VERSION "HNNBNNNYNNNNNNNNNNNNNNNNNNNNNNNNNNNNNNNNNN/4/%%%/4/'%**4NNN///"

NS_ :

BS_:

BU_: _4CL_C6 _6HP_C6 Airbag_C6 CVT_C6 DME_EDC16CP3000 DME_ME7_MED9_C6 DME_SIMOS6_C6 DME_Slave EPB_C6 ESP8_C6 Gateway_C6 LWR_AFS_C6 LWS_C6

BO_ 866 ACC_1: 8 DME_ME7_MED9_C6
 SG_ BZ_ACC1 : 0|4@1+ (1.0,0.0) [0.0|15.0] ""  DME_EDC16CP3000,DME_ME7_MED9_C6,DME_SIMOS6_C6,ESP8_C6
 SG_ Status_ACC : 4|3@1+ (1.0,0.0) [0.0|7.0] ""  DME_EDC16CP3000,DME_ME7_MED9_C6,DME_SIMOS6_C6,ESP8_C6
 SG_ Momenten_Anf_ACC : 8|8@1+ (0.39,0.0) [0.0|99.06] "%MDI"  DME_EDC16CP3000,DME_ME7_MED9_C6,DME_SIMOS6_C6
 SG_ Anhalten : 16|1@1+ (1.0,0.0) [0.0|1.0] ""  Vector__XXX
 SG_ AWV2_Freigabe : 17|1@1+ (1.0,0.0) [0.0|1.0] ""  Vector__XXX
 SG_ Freigabe_Momenten_Anf : 19|1@1+ (1.0,0.0) [0.0|1.0] ""  DME_EDC16CP3000,DME_ME7_MED9_C6,DME_SIMOS6_C6
 SG_ Verhinderung_SA : 20|1@1+ (1.0,0.0) [0.0|1.0] ""  DME_SIMOS6_C6
 SG_ Freigabe_Verzoeg_Anf : 21|1@1+ (1.0,0.0) [0.0|1.0] ""  _6HP_C6,DME_EDC16CP3000,DME_ME7_MED9_C6,ESP8_C6
 SG_ FSPE_ACC : 22|1@1+ (1.0,0.0) [0.0|1.0] ""  Vector__XXX
 SG_ Vorbefuellung_Bremsanlage : 23|1@1+ (1.0,0.0) [0.0|1.0] ""  ESP8_C6
 SG_ Verzoeg_Anf_ACC : 24|8@1+ (0.024,-3.984) [-3.984|2.112] "m/s2"  DME_EDC16CP3000,DME_ME7_MED9_C6,ESP8_C6
 SG_ Sollbeschl_Getr : 32|8@1+ (0.024,-3.984) [-3.984|2.112] "m/s2"  Vector__XXX
 SG_ AWV2_Priowarnung_LDW : 40|1@1+ (1.0,0.0) [0.0|1.0] ""  Vector__XXX
 SG_ Dynamik_Bremsdruck : 41|2@1+ (1.0,0.0) [0.0|3.0] ""  ESP8_C6
 SG_ Sender_Info : 43|1@1+ (1.0,0.0) [0.0|1.0] ""  _6HP_C6
 SG_ ESP_Beeinflussung_ACC : 44|1@1+ (1.0,0.0) [0.0|1.0] ""  ESP8_C6
 SG_ AWV2_Ruckprofil : 45|3@1+ (1.0,0.0) [0.0|7.0] ""  Vector__XXX
 SG_ AWV1_Freigabe : 48|1@1+ (1.0,0.0) [0.0|1.0] ""  ESP8_C6
 SG_ AWV1_Prefill : 49|1@1+ (1.0,0.0) [0.0|1.0] ""  ESP8_C6
 SG_ AWV1_Parameter_HBA : 50|2@1+ (1.0,0.0) [0.0|3.0] ""  ESP8_C6
 SG_ AWV1_Parameter_Nachtreten_HBA : 52|4@1+ (1.0,0.0) [0.0|15.0] ""  Vector__XXX
 SG_ CHK_ACC1 : 56|8@1+ (1.0,0.0) [0.0|255.0] ""  DME_EDC16CP3000,DME_ME7_MED9_C6,DME_SIMOS6_C6,ESP8_C6

BO_ 80 Airbag_1: 4 Airbag_C6
 SG_ Front_Crash : 0|1@1+ (1.0,0.0) [0.0|1.0] ""  ESP8_C6,Gateway_C6
 SG_ Heck_Crash : 1|1@1+ (1.0,0.0) [0.0|1.0] ""  ESP8_C6,Gateway_C6
 SG_ Seiten_Crash_Fahrer : 2|1@1+ (1.0,0.0) [0.0|1.0] ""  ESP8_C6,Gateway_C6
 SG_ Seiten_Crash_Beifahrer : 3|1@1+ (1.0,0.0) [0.0|1.0] ""  ESP8_C6,Gateway_C6
 SG_ Rollover : 4|1@1+ (1.0,0.0) [0.0|1.0] ""  ESP8_C6,Gateway_C6
 SG_ Crash_Intensitaet : 5|3@1+ (1.0,0.0) [0.0|7.0] ""  DME_EDC16CP3000,DME_ME7_MED9_C6,DME_SIMOS6_C6,Gateway_C6
 SG_ Airbag_Lampe : 8|1@1+ (1.0,0.0) [0.0|1.0] ""  Gateway_C6
 SG_ Airbag_deaktiviert : 9|1@1+ (1.0,0.0) [0.0|1.0] ""  Gateway_C6
 SG_ Beifahrerairbag_deaktiviert : 10|1@1+ (1.0,0.0) [0.0|1.0] ""  Gateway_C6
 SG_ Airbag_Systemfehler : 11|1@1+ (1.0,0.0) [0.0|1.0] ""  ESP8_C6,Gateway_C6
 SG_ Gurtschlossabfrage_Fahrer : 12|2@1+ (1.0,0.0) [0.0|3.0] ""  EPB_C6,ESP8_C6,Gateway_C6
 SG_ Gurtschlossabfrage_Beifahrer : 14|2@1+ (1.0,0.0) [0.0|3.0] ""  ESP8_C6,Gateway_C6
 SG_ Airbag_in_Diagnose : 16|1@1+ (1.0,0.0) [0.0|1.0] ""  Gateway_C6
 SG_ Airbag_im_Stellgliedtest : 17|1@1+ (1.0,0.0) [0.0|1.0] ""  DME_EDC16CP3000,Gateway_C6
 SG_ Gurtwarnung_Beifahrer : 18|1@1+ (1.0,0.0) [0.0|1.0] ""  Gateway_C6
 SG_ FSPE_Airbag : 19|1@1+ (1.0,0.0) [0.0|1.0] ""  Gateway_C6
 SG_ BZ_Airbag1 : 20|4@1+ (1.0,0.0) [0.0|15.0] ""  DME_EDC16CP3000,DME_ME7_MED9_C6,DME_SIMOS6_C6,EPB_C6,ESP8_C6,Gateway_C6
 SG_ CHK_Airbag1 : 24|8@1+ (1.0,0.0) [0.0|255.0] ""  DME_EDC16CP3000,DME_ME7_MED9_C6,DME_SIMOS6_C6,EPB_C6,ESP8_C6,Gateway_C6

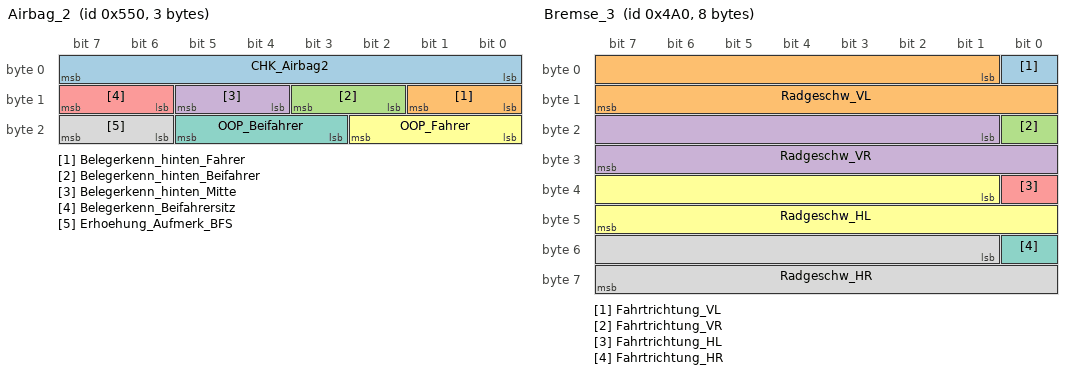
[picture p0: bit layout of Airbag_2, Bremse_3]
BO_ 1360 Airbag_2: 3 Airbag_C6
 SG_ CHK_Airbag2 : 0|8@1+ (1.0,0.0) [0.0|255.0] ""  Gateway_C6
 SG_ Belegerkenn_hinten_Fahrer : 8|2@1+ (1.0,0.0) [0.0|3.0] ""  Gateway_C6
 SG_ Belegerkenn_hinten_Beifahrer : 10|2@1+ (1.0,0.0) [0.0|3.0] ""  Gateway_C6
 SG_ Belegerkenn_hinten_Mitte : 12|2@1+ (1.0,0.0) [0.0|3.0] ""  Gateway_C6
 SG_ Belegerkenn_Beifahrersitz : 14|2@1+ (1.0,0.0) [0.0|3.0] ""  Gateway_C6
 SG_ OOP_Fahrer : 16|3@1+ (1.0,0.0) [0.0|7.0] ""  Gateway_C6
 SG_ OOP_Beifahrer : 19|3@1+ (1.0,0.0) [0.0|7.0] ""  Gateway_C6
 SG_ Erhoehung_Aufmerk_BFS : 22|2@1+ (1.0,0.0) [0.0|3.0] ""  Gateway_C6

BO_ 882 BEM_1_ACAN: 8 Gateway_C6
 SG_ Leerlaufdrehzahl_Erhoehung : 0|2@1+ (1.0,0.0) [0.0|3.0] ""  DME_EDC16CP3000,DME_SIMOS6_C6
 SG_ Anforderung_HSH : 2|1@1+ (1.0,0.0) [0.0|1.0] ""  Vector__XXX
 SG_ Abschaltstufen : 3|3@1+ (1.0,0.0) [0.0|7.0] ""  _4CL_C6,DME_SIMOS6_C6
 SG_ Lastabwurf_Rueckmeldung : 6|2@1+ (1.0,0.0) [0.0|3.0] ""  DME_SIMOS6_C6
 SG_ Load_Response_Generator : 8|2@1+ (3.0,0.0) [0.0|9.0] "s"  DME_SIMOS6_C6
 SG_ Einschaltung_PTC_Hzg : 10|2@1+ (1.0,0.0) [0.0|3.0] ""  DME_EDC16CP3000,DME_SIMOS6_C6
 SG_ BZ_BEM1 : 12|4@1+ (1.0,0.0) [0.0|15.0] ""  DME_EDC16CP3000,DME_SIMOS6_C6
 SG_ Generator_Lastmoment : 16|8@1+ (0.5,0.0) [0.0|127.0] "Nm"  DME_ME7_MED9_C6,DME_SIMOS6_C6
 SG_ Generator_Leistungsaufnahme : 24|8@1+ (50.0,0.0) [0.0|12700.0] "W"  DME_SIMOS6_C6
 SG_ Ruecknahme_HSH : 34|1@1+ (1.0,0.0) [0.0|1.0] ""  Vector__XXX
 SG_ Red_Innenraumgeblaese : 35|2@1+ (1.0,0.0) [0.0|3.0] ""  Vector__XXX
 SG_ Anforderung_Kluefter_ : 37|1@1+ (1.0,0.0) [0.0|1.0] ""  Vector__XXX
 SG_ BEM_Batteriespannung : 40|8@1+ (0.05,5.0) [5.0|16.0] "V"  Vector__XXX
 SG_ Abschalt_Heizsysteme : 48|3@1+ (1.0,0.0) [0.0|7.0] ""  Vector__XXX
 SG_ HL_Systemregelung_Status : 51|1@1+ (1.0,0.0) [0.0|1.0] ""  Vector__XXX
 SG_ HL_Systeme_Status : 52|4@1+ (1.0,0.0) [0.0|7.0] ""  Vector__XXX
 SG_ CHK_BEM1 : 56|8@1+ (1.0,0.0) [0.0|255.0] ""  _4CL_C6,DME_EDC16CP3000,DME_SIMOS6_C6

BO_ 416 Bremse_1: 8 ESP8_C6
 SG_ ASR_Anforderung : 0|1@1+ (1.0,0.0) [0.0|1.0] ""  _4CL_C6,_6HP_C6,Airbag_C6,DME_EDC16CP3000,DME_ME7_MED9_C6,DME_SIMOS6_C6,EPB_C6,Gateway_C6
 SG_ MSR_Anforderung : 1|1@1+ (1.0,0.0) [0.0|1.0] ""  Airbag_C6,DME_EDC16CP3000,DME_ME7_MED9_C6,DME_SIMOS6_C6,EPB_C6,Gateway_C6
 SG_ ABS_Bremsung : 2|1@1+ (1.0,0.0) [0.0|1.0] ""  _4CL_C6,_6HP_C6,Airbag_C6,DME_EDC16CP3000,DME_ME7_MED9_C6,DME_SIMOS6_C6,EPB_C6,Gateway_C6
 SG_ EDS_Eingriff : 3|1@1+ (1.0,0.0) [0.0|1.0] ""  DME_EDC16CP3000,DME_ME7_MED9_C6,DME_SIMOS6_C6,Gateway_C6
 SG_ ESP_Eingriff : 4|1@1+ (1.0,0.0) [0.0|1.0] ""  _4CL_C6,_6HP_C6,DME_EDC16CP3000,DME_ME7_MED9_C6,DME_SIMOS6_C6,EPB_C6,Gateway_C6
 SG_ ASR_Schaltbeeinflussung : 5|2@1+ (1.0,0.0) [0.0|3.0] ""  _6HP_C6,Gateway_C6
 SG_ EBV_Eingriff : 7|1@1+ (1.0,0.0) [0.0|1.0] ""  EPB_C6,Gateway_C6
 SG_ Lampe_ABS : 8|1@1+ (1.0,0.0) [0.0|1.0] ""  _6HP_C6,Gateway_C6
 SG_ Lampe_ASR_ESP : 9|1@1+ (1.0,0.0) [0.0|1.0] ""  Gateway_C6
 SG_ BKL : 10|1@1+ (1.0,0.0) [0.0|1.0] ""  Gateway_C6
 SG_ Bremslichtschalter_ESP m0  : 11|1@1+ (1.0,0.0) [0.0|1.0] ""  _4CL_C6,DME_EDC16CP3000,DME_ME7_MED9_C6,DME_SIMOS6_C6,EPB_C6,Gateway_C6,LWR_AFS_C6
 SG_ Fahrer_bremst m1  : 11|1@1+ (1.0,0.0) [0.0|1.0] ""  Gateway_C6
 SG_ Bremstestschalter_ESP m0  : 12|1@1+ (1.0,0.0) [0.0|1.0] ""  DME_EDC16CP3000,DME_ME7_MED9_C6,DME_SIMOS6_C6,EPB_C6,Gateway_C6,LWR_AFS_C6
 SG_ Status_aktives_Bremssystem m1  : 12|1@1+ (1.0,0.0) [0.0|1.0] ""  Gateway_C6
 SG_ Schlechtwegausblendung : 13|1@1+ (1.0,0.0) [0.0|1.0] ""  DME_ME7_MED9_C6,DME_SIMOS6_C6,Gateway_C6
 SG_ FStatus_Schlechtwegausblendung : 14|1@1+ (1.0,0.0) [0.0|1.0] ""  DME_ME7_MED9_C6,DME_SIMOS6_C6,Gateway_C6
 SG_ ABS_in_Diagnose : 15|1@1+ (1.0,0.0) [0.0|1.0] ""  DME_ME7_MED9_C6,Gateway_C6
 SG_ Aktiver_BKV M  : 16|1@1+ (1.0,0.0) [0.0|1.0] ""  DME_ME7_MED9_C6,DME_SIMOS6_C6,Gateway_C6
 SG_ Geschwindigkeit_15Bit : 17|15@1+ (0.01,0.0) [0.0|326.39] "km/h"  _6HP_C6,Airbag_C6,DME_EDC16CP3000,DME_ME7_MED9_C6,DME_SIMOS6_C6,EPB_C6,Gateway_C6
 SG_ ASR_Eingriffmom_langsam : 32|8@1+ (0.39,0.0) [0.0|99.06] "%MDI"  _6HP_C6,DME_ME7_MED9_C6,DME_SIMOS6_C6,Gateway_C6
 SG_ ASR_Eingriffmom_schnell : 40|8@1+ (0.39,0.0) [0.0|99.06] "%MDI"  _6HP_C6,DME_EDC16CP3000,DME_ME7_MED9_C6,DME_SIMOS6_C6,Gateway_C6
 SG_ MSR_Eingriffmom : 48|8@1+ (0.39,0.0) [0.0|99.06] "%MDI"  DME_EDC16CP3000,DME_ME7_MED9_C6,DME_SIMOS6_C6,Gateway_C6
 SG_ BZ_Bremse1 : 56|4@1+ (1.0,0.0) [0.0|15.0] ""  _4CL_C6,DME_EDC16CP3000,DME_ME7_MED9_C6,DME_SIMOS6_C6,EPB_C6,Gateway_C6
 SG_ ASR_Steuergeraet : 60|1@1+ (1.0,0.0) [0.0|1.0] ""  DME_ME7_MED9_C6,Gateway_C6
 SG_ ESP_passiv_getastet : 61|1@1+ (1.0,0.0) [0.0|1.0] ""  _6HP_C6,Gateway_C6
 SG_ ESP_Systemstatus : 62|1@1+ (1.0,0.0) [0.0|1.0] ""  _4CL_C6,DME_EDC16CP3000,DME_SIMOS6_C6,EPB_C6,Gateway_C6
 SG_ Geschwindigkeitersatzwert : 63|1@1+ (1.0,0.0) [0.0|1.0] ""  Airbag_C6,DME_SIMOS6_C6,EPB_C6,Gateway_C6

BO_ 1440 Bremse_2: 8 ESP8_C6
 SG_ Querbeschleunigung m0  : 0|8@1+ (0.01,-1.27) [-1.27|1.27] "g"  _4CL_C6,_6HP_C6,DME_EDC16CP3000,DME_ME7_MED9_C6,DME_SIMOS6_C6,Gateway_C6
 SG_ Zaehnezahl m1  : 0|8@1+ (1.0,0.0) [0.0|255.0] ""  Gateway_C6
 SG_ Mux_Code_Bremse2 M  : 8|1@1+ (1.0,0.0) [0.0|1.0] ""  _4CL_C6,_6HP_C6,DME_EDC16CP3000,DME_ME7_MED9_C6,DME_SIMOS6_C6,Gateway_C6
 SG_ Mittlere_Raddrehzahl : 9|15@1+ (0.0020,0.0) [0.0|65.278] "1/s"  Gateway_C6
 SG_ Lampe_ABS : 24|1@1+ (1.0,0.0) [0.0|1.0] ""  Gateway_C6
 SG_ Lampe_ASR_ESP : 25|1@1+ (1.0,0.0) [0.0|1.0] ""  Gateway_C6
 SG_ BKL : 26|1@1+ (1.0,0.0) [0.0|1.0] ""  Gateway_C6
 SG_ Warnlampe_RKA : 27|1@1+ (1.0,0.0) [0.0|1.0] ""  Gateway_C6
 SG_ BZ_Bremse2 : 28|4@1+ (1.0,0.0) [0.0|15.0] ""  _4CL_C6,Gateway_C6
 SG_ Textbits_Bremse : 32|4@1+ (1.0,0.0) [0.0|15.0] ""  Gateway_C6
 SG_ Akustische_Warnung : 36|2@1+ (1.0,0.0) [0.0|3.0] ""  Gateway_C6
 SG_ Bremskontroll_Blinkmode : 39|1@1+ (1.0,0.0) [0.0|1.0] ""  Gateway_C6
 SG_ Wegimpulse_VA : 40|11@1+ (1.0,0.0) [0.0|2047.0] ""  Gateway_C6
 SG_ Wegimpulszaehlerstatus : 51|1@1+ (1.0,0.0) [0.0|1.0] ""  Gateway_C6
 SG_ FSPE_Bremse : 52|1@1+ (1.0,0.0) [0.0|1.0] ""  Gateway_C6
 SG_ QBit_Querbeschleunigung : 54|1@1+ (1.0,0.0) [0.0|1.0] ""  _4CL_C6,Gateway_C6
 SG_ FStatus_Wegimpulse : 55|1@1+ (1.0,0.0) [0.0|1.0] ""  Gateway_C6
 SG_ Impulszahl : 56|6@1+ (1.0,0.0) [0.0|63.0] ""  Gateway_C6
 SG_ SIB_ESP : 62|1@1+ (1.0,0.0) [0.0|1.0] ""  Gateway_C6
 SG_ Gemessene_Querbeschleunigung : 63|1@1+ (1.0,0.0) [0.0|1.0] ""  Gateway_C6

BO_ 1184 Bremse_3: 8 ESP8_C6
 SG_ Fahrtrichtung_VL : 0|1@1+ (1.0,0.0) [0.0|1.0] ""  Gateway_C6,LWS_C6
 SG_ Radgeschw_VL : 1|15@1+ (0.01,0.0) [0.0|326.39] "km/h"  _6HP_C6,DME_ME7_MED9_C6,DME_SIMOS6_C6,EPB_C6,Gateway_C6,LWS_C6
 SG_ Fahrtrichtung_VR : 16|1@1+ (1.0,0.0) [0.0|1.0] ""  Gateway_C6,LWS_C6
 SG_ Radgeschw_VR : 17|15@1+ (0.01,0.0) [0.0|326.39] "km/h"  _6HP_C6,DME_ME7_MED9_C6,DME_SIMOS6_C6,EPB_C6,Gateway_C6,LWS_C6
 SG_ Fahrtrichtung_HL : 32|1@1+ (1.0,0.0) [0.0|1.0] ""  Gateway_C6,LWR_AFS_C6,LWS_C6
 SG_ Radgeschw_HL : 33|15@1+ (0.01,0.0) [0.0|326.39] "km/h"  _6HP_C6,DME_ME7_MED9_C6,DME_SIMOS6_C6,EPB_C6,Gateway_C6,LWR_AFS_C6,LWS_C6
 SG_ Fahrtrichtung_HR : 48|1@1+ (1.0,0.0) [0.0|1.0] ""  Gateway_C6,LWR_AFS_C6,LWS_C6
 SG_ Radgeschw_HR : 49|15@1+ (0.01,0.0) [0.0|326.39] "km/h"  _6HP_C6,DME_ME7_MED9_C6,DME_SIMOS6_C6,EPB_C6,Gateway_C6,LWR_AFS_C6,LWS_C6

BO_ 1192 Bremse_5: 8 ESP8_C6
 SG_ Giergeschwindigkeit : 0|14@1+ (0.01,0.0) [0.0|163.82] "Grad/s"  Gateway_C6
 SG_ Gierrate_ungueltig : 14|1@1+ (1.0,0.0) [0.0|1.0] ""  Gateway_C6
 SG_ Signum_Giergeschwindigkeit : 15|1@1+ (1.0,0.0) [0.0|1.0] ""  Gateway_C6
 SG_ Bremsdruck : 16|12@1+ (0.1,0.0) [0.0|409.4] "bar"  _4CL_C6,EPB_C6,Gateway_C6
 SG_ Stillstandsflag : 28|1@1+ (1.0,0.0) [0.0|1.0] ""  _4CL_C6,EPB_C6,Gateway_C6
 SG_ Bremsdruck_ungueltig : 29|1@1+ (1.0,0.0) [0.0|1.0] ""  _4CL_C6,EPB_C6,Gateway_C6
 SG_ Status_Bremsdruck_ESP_System : 30|1@1+ (1.0,0.0) [0.0|1.0] ""  Gateway_C6
 SG_ Signum_Bremsdruck : 31|1@1+ (1.0,0.0) [0.0|1.0] ""  _4CL_C6,Gateway_C6
 SG_ Reifentoleranzabgleich_VR : 32|8@1+ (0.04883,-6.20117) [-6.20117|6.15234] "%"  Gateway_C6
 SG_ FStatus_Anfahrhilfe : 40|1@1+ (1.0,0.0) [0.0|1.0] ""  EPB_C6,Gateway_C6
 SG_ Anfahrhilfe_aktiv : 41|1@1+ (1.0,0.0) [0.0|1.0] ""  EPB_C6,Gateway_C6
 SG_ Geschwindigkeitsueberwachung : 42|1@1+ (1.0,0.0) [0.0|1.0] ""  Gateway_C6
 SG_ TSP_aktiv : 43|1@1+ (1.0,0.0) [0.0|1.0] ""  Gateway_C6
 SG_ Notfallblinken : 44|1@1+ (1.0,0.0) [0.0|1.0] ""  Gateway_C6
 SG_ Rueckfallebene_ECD : 45|1@1+ (1.0,0.0) [0.0|1.0] ""  Gateway_C6
 SG_ AWV2_Durchfuehrung_Bremsruck : 46|1@1+ (1.0,0.0) [0.0|1.0] ""  Gateway_C6
 SG_ Bremsentemperatur : 48|3@1+ (125.0,125.0) [125.0|1000.0] "°C"  Gateway_C6
 SG_ Bremslicht_ECD : 51|1@1+ (1.0,0.0) [0.0|1.0] ""  Gateway_C6
 SG_ BZ_Bremse5 : 52|4@1+ (1.0,0.0) [0.0|15.0] ""  _4CL_C6,EPB_C6,Gateway_C6
 SG_ CHK_Bremse5 : 56|8@1+ (1.0,0.0) [0.0|255.0] ""  _4CL_C6,EPB_C6,Gateway_C6

BO_ 428 Bremse_8: 8 ESP8_C6
 SG_ CHK_Bremse8 : 0|8@1+ (1.0,0.0) [0.0|255.0] ""  DME_EDC16CP3000,DME_ME7_MED9_C6,DME_SIMOS6_C6,EPB_C6,Gateway_C6
 SG_ BZ_Bremse8 : 8|4@1+ (1.0,0.0) [0.0|15.0] ""  DME_EDC16CP3000,DME_ME7_MED9_C6,DME_SIMOS6_C6,EPB_C6,Gateway_C6
 SG_ Status_Bremse_ACC_Anf : 12|1@1+ (1.0,0.0) [0.0|1.0] ""  DME_SIMOS6_C6,Gateway_C6
 SG_ Verzoegerung_EPB_aktiviert : 13|1@1+ (1.0,0.0) [0.0|1.0] ""  DME_EDC16CP3000,DME_ME7_MED9_C6,DME_SIMOS6_C6,EPB_C6,Gateway_C6
 SG_ Status_Bremsentemperatur : 14|1@1+ (1.0,0.0) [0.0|1.0] ""  DME_EDC16CP3000,DME_ME7_MED9_C6,DME_SIMOS6_C6,Gateway_C6
 SG_ Status_Bremsdruck : 15|1@1+ (1.0,0.0) [0.0|1.0] ""  DME_ME7_MED9_C6,EPB_C6,Gateway_C6
 SG_ Reifentoleranzabgleich_HL : 16|8@1+ (0.04883,-6.20117) [-6.20117|6.15234] "%"  Gateway_C6
 SG_ Reifentoleranzabgleich_HR : 24|8@1+ (0.04883,-6.20117) [-6.20117|6.15234] "%"  Gateway_C6
 SG_ Status_HW_BLS_Ausgang : 41|1@1+ (1.0,0.0) [0.0|1.0] ""  Gateway_C6
 SG_ QBit_Laengsbeschleunigung : 42|1@1+ (1.0,0.0) [0.0|1.0] ""  Gateway_C6
 SG_ AWV1_Parametersatz_HBA : 43|2@1+ (1.0,0.0) [0.0|3.0] ""  Gateway_C6
 SG_ Aktives_Bremssystem : 45|1@1+ (1.0,0.0) [0.0|1.0] ""  Gateway_C6
 SG_ Fahrer_bremst : 46|1@1+ (1.0,0.0) [0.0|1.0] ""  Gateway_C6
 SG_ Status_aktives_Bremssystem : 47|1@1+ (1.0,0.0) [0.0|1.0] ""  Gateway_C6
 SG_ Laengsbeschleunigung : 48|10@1+ (0.03125,-16.0) [-16.0|15.9375] "m/s2"  DME_SIMOS6_C6,Gateway_C6
 SG_ Konsistenz_ACC_Botschaft : 58|1@1+ (1.0,0.0) [0.0|1.0] ""  DME_ME7_MED9_C6,DME_SIMOS6_C6,Gateway_C6
 SG_ Quattroantrieb : 59|1@1+ (1.0,0.0) [0.0|1.0] ""  Gateway_C6
 SG_ Status_Verzoegerungsregler : 60|1@1+ (1.0,0.0) [0.0|1.0] ""  DME_EDC16CP3000,DME_ME7_MED9_C6,DME_SIMOS6_C6,Gateway_C6
 SG_ Status_BLS : 61|1@1+ (1.0,0.0) [0.0|1.0] ""  DME_EDC16CP3000,DME_ME7_MED9_C6,DME_SIMOS6_C6,Gateway_C6
 SG_ EPB_Verzoegerung_verfuegbar : 62|1@1+ (1.0,0.0) [0.0|1.0] ""  EPB_C6,Gateway_C6
 SG_ EPB_Botschaft_plausibel : 63|1@1+ (1.0,0.0) [0.0|1.0] ""  EPB_C6,Gateway_C6

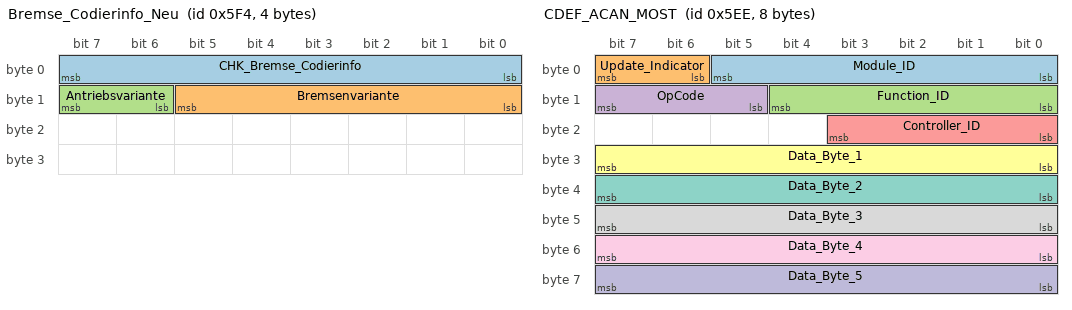
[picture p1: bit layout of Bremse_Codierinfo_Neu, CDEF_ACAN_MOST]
BO_ 1524 Bremse_Codierinfo_Neu: 4 Airbag_C6
 SG_ CHK_Bremse_Codierinfo : 0|8@1+ (1.0,0.0) [0.0|255.0] ""  ESP8_C6
 SG_ Bremsenvariante : 8|6@1+ (1.0,0.0) [0.0|63.0] ""  ESP8_C6
 SG_ Antriebsvariante : 14|2@1+ (1.0,0.0) [0.0|3.0] ""  ESP8_C6

BO_ 1518 CDEF_ACAN_MOST: 8 _4CL_C6
 SG_ Module_ID : 0|6@1+ (1.0,0.0) [0.0|63.0] ""  Gateway_C6
 SG_ Update_Indicator : 6|2@1+ (1.0,0.0) [0.0|3.0] ""  Gateway_C6
 SG_ Function_ID : 8|5@1+ (1.0,0.0) [0.0|31.0] ""  Gateway_C6
 SG_ OpCode : 13|3@1+ (1.0,0.0) [0.0|7.0] ""  Gateway_C6
 SG_ Controller_ID : 16|4@1+ (1.0,0.0) [0.0|15.0] ""  Gateway_C6
 SG_ Data_Byte_1 : 24|8@1+ (1.0,0.0) [0.0|255.0] ""  Gateway_C6
 SG_ Data_Byte_2 : 32|8@1+ (1.0,0.0) [0.0|255.0] ""  Gateway_C6
 SG_ Data_Byte_3 : 40|8@1+ (1.0,0.0) [0.0|255.0] ""  Gateway_C6
 SG_ Data_Byte_4 : 48|8@1+ (1.0,0.0) [0.0|255.0] ""  Gateway_C6
 SG_ Data_Byte_5 : 56|8@1+ (1.0,0.0) [0.0|255.0] ""  Gateway_C6

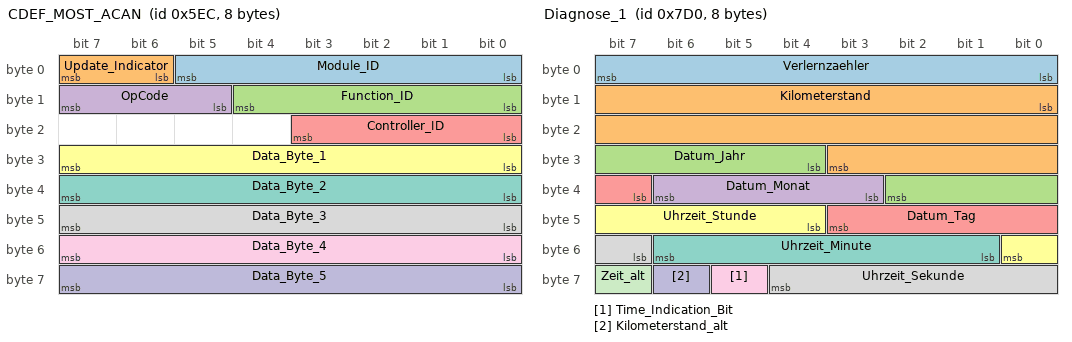
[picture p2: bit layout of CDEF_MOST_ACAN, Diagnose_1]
BO_ 1516 CDEF_MOST_ACAN: 8 Gateway_C6
 SG_ Module_ID : 0|6@1+ (1.0,0.0) [0.0|63.0] ""  _4CL_C6
 SG_ Update_Indicator : 6|2@1+ (1.0,0.0) [0.0|3.0] ""  _4CL_C6
 SG_ Function_ID : 8|5@1+ (1.0,0.0) [0.0|31.0] ""  _4CL_C6
 SG_ OpCode : 13|3@1+ (1.0,0.0) [0.0|7.0] ""  _4CL_C6
 SG_ Controller_ID : 16|4@1+ (1.0,0.0) [0.0|15.0] ""  _4CL_C6
 SG_ Data_Byte_1 : 24|8@1+ (1.0,0.0) [0.0|255.0] ""  _4CL_C6
 SG_ Data_Byte_2 : 32|8@1+ (1.0,0.0) [0.0|255.0] ""  _4CL_C6
 SG_ Data_Byte_3 : 40|8@1+ (1.0,0.0) [0.0|255.0] ""  _4CL_C6
 SG_ Data_Byte_4 : 48|8@1+ (1.0,0.0) [0.0|255.0] ""  _4CL_C6
 SG_ Data_Byte_5 : 56|8@1+ (1.0,0.0) [0.0|255.0] ""  _4CL_C6

BO_ 2000 Diagnose_1: 8 Gateway_C6
 SG_ Verlernzaehler : 0|8@1+ (1.0,0.0) [0.0|254.0] ""  _4CL_C6,EPB_C6,ESP8_C6,LWR_AFS_C6
 SG_ Kilometerstand : 8|20@1+ (1.0,0.0) [0.0|1048574.0] "km"  _4CL_C6,_6HP_C6,DME_EDC16CP3000,EPB_C6,ESP8_C6,LWR_AFS_C6
 SG_ Datum_Jahr : 28|7@1+ (1.0,2000.0) [2000.0|2127.0] ""  _4CL_C6,_6HP_C6,DME_EDC16CP3000,EPB_C6,ESP8_C6,LWR_AFS_C6
 SG_ Datum_Monat : 35|4@1+ (1.0,0.0) [1.0|12.0] ""  _4CL_C6,_6HP_C6,DME_EDC16CP3000,EPB_C6,ESP8_C6,LWR_AFS_C6
 SG_ Datum_Tag : 39|5@1+ (1.0,0.0) [1.0|31.0] ""  _4CL_C6,_6HP_C6,DME_EDC16CP3000,EPB_C6,ESP8_C6,LWR_AFS_C6
 SG_ Uhrzeit_Stunde : 44|5@1+ (1.0,0.0) [0.0|23.0] "h"  _4CL_C6,_6HP_C6,DME_EDC16CP3000,EPB_C6,ESP8_C6,LWR_AFS_C6
 SG_ Uhrzeit_Minute : 49|6@1+ (1.0,0.0) [0.0|59.0] "min"  _4CL_C6,_6HP_C6,DME_EDC16CP3000,EPB_C6,ESP8_C6,LWR_AFS_C6
 SG_ Uhrzeit_Sekunde : 55|6@1+ (1.0,0.0) [0.0|59.0] "s"  _4CL_C6,_6HP_C6,DME_EDC16CP3000,EPB_C6,ESP8_C6,LWR_AFS_C6
 SG_ Time_Indication_Bit : 61|1@1+ (1.0,0.0) [0.0|1.0] ""  Vector__XXX
 SG_ Kilometerstand_alt : 62|1@1+ (1.0,0.0) [0.0|1.0] ""  _4CL_C6,DME_EDC16CP3000,EPB_C6,ESP8_C6,LWR_AFS_C6
 SG_ Zeit_alt : 63|1@1+ (1.0,0.0) [0.0|1.0] ""  _4CL_C6,DME_EDC16CP3000,EPB_C6,ESP8_C6,LWR_AFS_C6

BO_ 1472 EPB_1: 8 EPB_C6
 SG_ BZ_EPB1 : 0|4@1+ (1.0,0.0) [0.0|15.0] ""  ESP8_C6,Gateway_C6
 SG_ FStatus_EPB : 4|2@1+ (1.0,0.0) [0.0|3.0] ""  ESP8_C6,Gateway_C6
 SG_ Status_EPB : 6|1@1+ (1.0,0.0) [0.0|1.0] ""  ESP8_C6,Gateway_C6
 SG_ Schalterstatus_EPB : 7|1@1+ (1.0,0.0) [0.0|1.0] ""  ESP8_C6,Gateway_C6
 SG_ Erreichte_Spannkraft : 8|5@1+ (1.0,0.0) [0.0|30.0] "kN"  ESP8_C6,Gateway_C6
 SG_ Schalterinfo_EPB : 13|2@1+ (1.0,0.0) [0.0|3.0] ""  ESP8_C6,Gateway_C6
 SG_ Status_NWG : 15|1@1+ (1.0,0.0) [0.0|1.0] ""  _6HP_C6,ESP8_C6,Gateway_C6
 SG_ Neigungswinkel : 16|8@1+ (1.0,-128.0) [-128.0|127.0] "%g"  _6HP_C6,ESP8_C6,Gateway_C6
 SG_ Verz_anf_EPB : 24|8@1+ (0.048,-7.968) [-7.968|4.224] "m/s2"  ESP8_C6,Gateway_C6
 SG_ FSPE_EPB : 32|1@1+ (1.0,0.0) [0.0|1.0] ""  Gateway_C6
 SG_ Freig_Verz_anf_EPB : 33|1@1+ (1.0,0.0) [0.0|1.0] ""  ESP8_C6,Gateway_C6
 SG_ Verschleissanzeige : 34|2@1+ (1.0,0.0) [0.0|3.0] ""  Gateway_C6
 SG_ SIB_EPB : 36|1@1+ (1.0,0.0) [0.0|1.0] ""  Gateway_C6
 SG_ KL15_Status_Info : 37|1@1+ (1.0,0.0) [0.0|1.0] ""  Gateway_C6
 SG_ Funktionslampe_Auto_P : 38|1@1+ (1.0,0.0) [0.0|1.0] ""  Gateway_C6
 SG_ Bremslicht_dyn_Abbremsung : 39|1@1+ (1.0,0.0) [0.0|1.0] ""  Gateway_C6
 SG_ Warnton_1 : 40|1@1+ (1.0,0.0) [0.0|1.0] ""  Gateway_C6
 SG_ Warnton_2 : 41|1@1+ (1.0,0.0) [0.0|1.0] ""  Gateway_C6
 SG_ Anforderung_Shift_Lock_Lampe : 42|1@1+ (1.0,0.0) [0.0|1.0] ""  Gateway_C6
 SG_ Auto_Oeffnen_Schliessen_erlaubt : 43|1@1+ (1.0,0.0) [0.0|1.0] ""  CVT_C6,Gateway_C6
 SG_ QBit_Neigungswinkel : 44|1@1+ (1.0,0.0) [0.0|1.0] ""  Gateway_C6
 SG_ Kupplungsmodulationsbereich : 45|2@1+ (1.0,0.0) [0.0|3.0] ""  Gateway_C6
 SG_ Funktionslampe_EPB : 48|1@1+ (1.0,0.0) [0.0|1.0] ""  Gateway_C6
 SG_ Warnton_EPB : 49|1@1+ (1.0,0.0) [0.0|1.0] ""  Gateway_C6
 SG_ Fehlerlampe_BKL : 50|1@1+ (1.0,0.0) [0.0|1.0] ""  Gateway_C6
 SG_ Fehlerlampe_Gelb_EPB : 51|1@1+ (1.0,0.0) [0.0|1.0] ""  Gateway_C6
 SG_ Textmeldungen_EPB : 52|4@1+ (1.0,0.0) [0.0|15.0] ""  Gateway_C6
 SG_ CHK_EPB1 : 56|8@1+ (1.0,0.0) [0.0|255.0] ""  ESP8_C6,Gateway_C6

BO_ 912 Gateway_Komfort_1: 8 Gateway_C6
 SG_ RDK_alt : 0|1@1+ (1.0,0.0) [0.0|1.0] ""  Vector__XXX
 SG_ Anhaenger_alt : 1|1@1+ (1.0,0.0) [0.0|1.0] ""  _4CL_C6,DME_ME7_MED9_C6
 SG_ Licht_hinten_alt : 3|1@1+ (1.0,0.0) [0.0|1.0] ""  DME_ME7_MED9_C6,LWR_AFS_C6
 SG_ Licht_vorne_alt : 5|1@1+ (1.0,0.0) [0.0|1.0] ""  LWR_AFS_C6
 SG_ ACAN_Sleep_ACK : 7|1@1+ (1.0,0.0) [0.0|1.0] ""  _4CL_C6,_6HP_C6,CVT_C6,DME_EDC16CP3000,DME_ME7_MED9_C6,DME_SIMOS6_C6,EPB_C6,ESP8_C6,LWS_C6
 SG_ Rueckfahrlichtschalter_ein : 17|1@1+ (1.0,0.0) [0.0|1.0] ""  EPB_C6,ESP8_C6
 SG_ KY2_ELV_verr : 18|1@1+ (1.0,0.0) [0.0|1.0] ""  EPB_C6
 SG_ mKessy2_alt : 19|1@1+ (1.0,0.0) [0.0|1.0] ""  EPB_C6
 SG_ mStHeizung1_alt : 20|1@1+ (1.0,0.0) [0.0|1.0] ""  Vector__XXX
 SG_ ILM_H_Botschaftszaehler : 24|4@1+ (1.0,0.0) [0.0|15.0] ""  DME_ME7_MED9_C6
 SG_ Rueckfahrlicht_akt : 28|1@1+ (1.0,0.0) [0.0|1.0] ""  ESP8_C6,LWR_AFS_C6
 SG_ Bremsl_HL_def : 29|1@1+ (1.0,0.0) [0.0|1.0] ""  DME_EDC16CP3000,DME_ME7_MED9_C6
 SG_ Bremsl_HR_def : 30|1@1+ (1.0,0.0) [0.0|1.0] ""  DME_EDC16CP3000,DME_ME7_MED9_C6
 SG_ Bremsl_3_def : 31|1@1+ (1.0,0.0) [0.0|1.0] ""  DME_EDC16CP3000,DME_ME7_MED9_C6
 SG_ ILM_BLS_unplausibel : 32|1@1+ (1.0,0.0) [0.0|1.0] ""  Vector__XXX
 SG_ ILM_ECD_unplausibel : 33|1@1+ (1.0,0.0) [0.0|1.0] ""  DME_EDC16CP3000,DME_ME7_MED9_C6
 SG_ Blinken_links : 34|1@1+ (1.0,0.0) [0.0|1.0] ""  LWR_AFS_C6
 SG_ Blinken_rechts : 35|1@1+ (1.0,0.0) [0.0|1.0] ""  LWR_AFS_C6
 SG_ AAG_Botschaftszaehler : 40|4@1+ (1.0,0.0) [0.0|15.0] ""  DME_EDC16CP3000,DME_ME7_MED9_C6
 SG_ AAG_BLS_unplausibel : 44|1@1+ (1.0,0.0) [0.0|1.0] ""  Vector__XXX
 SG_ AAG_ECD_unplausibel : 45|1@1+ (1.0,0.0) [0.0|1.0] ""  DME_EDC16CP3000,DME_ME7_MED9_C6
 SG_ Anhaenger_erkannt : 46|1@1+ (1.0,0.0) [0.0|1.0] ""  _4CL_C6,DME_EDC16CP3000,DME_ME7_MED9_C6
 SG_ Bremslicht_AH_def : 47|1@1+ (1.0,0.0) [0.0|1.0] ""  DME_EDC16CP3000,DME_ME7_MED9_C6
 SG_ Abblendlicht_aktiv : 48|1@1+ (1.0,0.0) [0.0|1.0] ""  LWR_AFS_C6
 SG_ Fernlicht_aktiv : 49|1@1+ (1.0,0.0) [0.0|1.0] ""  LWR_AFS_C6
 SG_ Wischer_vorne_laeuft : 50|1@1+ (1.0,0.0) [0.0|1.0] ""  ESP8_C6
 SG_ ILM_Fahrer1_alt : 51|1@1+ (1.0,0.0) [0.0|1.0] ""  EPB_C6
 SG_ Abblend_VL_def : 52|1@1+ (1.0,0.0) [0.0|1.0] ""  LWR_AFS_C6
 SG_ Abblend_VR_def : 53|1@1+ (1.0,0.0) [0.0|1.0] ""  LWR_AFS_C6
 SG_ Blinken_Autobahn : 54|1@1+ (1.0,0.0) [0.0|1.0] ""  LWR_AFS_C6
 SG_ Warnblink_aktiv : 55|1@1+ (1.0,0.0) [0.0|1.0] ""  Vector__XXX
 SG_ SH_aktiv_Flag : 56|1@1+ (1.0,0.0) [0.0|1.0] ""  DME_ME7_MED9_C6
 SG_ SH_MVW : 57|1@1+ (1.0,0.0) [0.0|1.0] ""  DME_ME7_MED9_C6
 SG_ Nebellicht_aktiv : 58|1@1+ (1.0,0.0) [0.0|1.0] ""  Vector__XXX

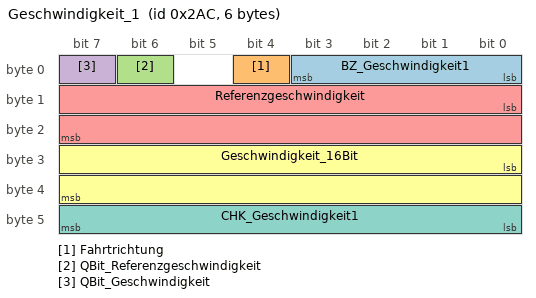
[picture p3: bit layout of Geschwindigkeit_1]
BO_ 684 Geschwindigkeit_1: 6 ESP8_C6
 SG_ BZ_Geschwindigkeit1 : 0|4@1+ (1.0,0.0) [0.0|15.0] ""  _4CL_C6
 SG_ Fahrtrichtung : 4|1@1+ (1.0,0.0) [0.0|1.0] ""  Vector__XXX
 SG_ QBit_Referenzgeschwindigkeit : 6|1@1+ (1.0,0.0) [0.0|1.0] ""  Vector__XXX
 SG_ QBit_Geschwindigkeit : 7|1@1+ (1.0,0.0) [0.0|1.0] ""  _4CL_C6
 SG_ Referenzgeschwindigkeit : 8|16@1+ (0.01,0.0) [0.0|654.15] "km/h"  Vector__XXX
 SG_ Geschwindigkeit_16Bit : 24|16@1+ (0.01,0.0) [0.0|654.15] "km/h"  _4CL_C6
 SG_ CHK_Geschwindigkeit1 : 40|8@1+ (1.0,0.0) [0.0|255.0] ""  _4CL_C6

BO_TX_BU_ 866 :DME_ME7_MED9_C6,Gateway_C6;

CM_ "Generiert durch die EE-Vernetzungsdatenbank, Version 2.17";

CM_ SG_ 866 Anhalten "Anforderung an das Bremssystem, einen Anhaltevorgang bis zum Stand durchzuführen

0x0 = keine Anhalteanforderung
0x1 = Anhalteanforderung aktiv";
CM_ SG_ 866 AWV1_Freigabe "Das Freigabebit muss gesetzt sein, um die Anforderungen 'Prefill' oder 'adaptiver HBA freizugeben'. HBA = hydraulischer Bremsassistent

0x0 = AWV1 nicht freigegeben
0x1 = AWV1 freigegeben";
CM_ SG_ 866 AWV1_Parameter_HBA "Anforderung an das ESP, welcher HBA-Parametersatz verwendet werden soll. Die Festlegung der Empfindlichkeitsschwellen der verschiedenen Parametersätze erfolgt mit der Applikation des Gesamtssystems ESP/ACC bzw. des HBA. Umsetzung der Anforderung im ESP nu";
CM_ SG_ 866 AWV1_Prefill "Anforderung an das ESP, dass Prefill-Funktion aktiviert werden soll. Umsetzung der Prefill-Anforderung im ESP nur in Verbindung mit gesetztem Bit 'AWV1_Freigabe'.

0x0 = keine Prefill Anforderung
0x1 = Prefill Anforderung";
CM_ SG_ 866 AWV2_Freigabe "Das Freigabebit muss gesetzt sein, um die Anforderung AWV2_Ruckprofil zur Umsetzung freizugeben.

0x0 = keine Freigabe
0x1 = Freigabe";
CM_ SG_ 866 AWV2_Priowarnung_LDW "Signal an LDW, zur Unterdrückung der LDW-Warnung bei AWV2-Warnung. Bei AWV2-Warnung kann ein massives Lenkmanöver notwendig sein,  die zusätzliche LDW-Warnung könnte den Fahrer verunsichern. 

0x0 = keine Warnung
0x1 = AWV2 Priowarnung (LDW unterdrückt";
CM_ SG_ 866 AWV2_Ruckprofil "Anforderung an ESP, welcher Ruck aus einer Auswahl von maximal 7 verschiedenen Ruckprofilen verwendet werden soll. Eine Umsetzung der Ruckanforderung im ESP erfolgt nur mit gesetztem Bit AWV2_Freigabe.

0x0 .. 0x7 = Ruckprofile";
CM_ SG_ 866 BZ_ACC1 "Freilaufender 4Bit-Botschaftszähler";
CM_ SG_ 866 CHK_ACC1 "XOR über Summe aller Bytes siehe High-Speed-CAN-Lastenheft";
CM_ SG_ 866 Dynamik_Bremsdruck "Beide Bits können unabhängig voneinander gesetzt oder nicht gesetzt sein. Sie stellen keine direkte Anforderung an das Bremssystem darf, sondern beschreiben, in welcher Weise eine ACC-Verzögerungsanforderung umgesetzt werden soll.

x0 = reduzierte Dynam";
CM_ SG_ 866 ESP_Beeinflussung_ACC "Bit wird verwendet, um ESP zwangsweise zu aktivieren. Bei einem gesetzten Bit ist ein ausgetastetes ESP wieder aktiviert bzw. wird die Austastung verhindert.

0x0 = keine ESP Beeinflussung
0x1 = ESP Zwangszuschaltung";
CM_ SG_ 866 Freigabe_Momenten_Anf "Bit 'Freigabe Momentenanforderung' darf nicht gleichzeitig mit 'Bit Freigabe Verzögerungsanforderung' gesetzt sein (Verriegelung erfolgt im ACC-SG).

0x0 = Momentenanforderung nicht freigegeben
0x1 = Momentenanforderung freigegeben";
CM_ SG_ 866 Freigabe_Verzoeg_Anf "Bit 'Freigabe Verzögerungsanforderung' darf nicht gleichzeitig mit Bit 'Freigabe Momentenanforderung' gesetzt sein.

0x0 = Verzögerungsanforderung nicht freigegeben
0x1 = Verzögerungsanforderung freigegeben

";
CM_ SG_ 866 FSPE_ACC "Bei gesetztem Bit ist mindestens ein Kundendienstfehler eingetragen

0x0 = kein KD_Fehler eingetragen
0x1 = KD_Fehler eingetragen
";
CM_ SG_ 866 Momenten_Anf_ACC "Anforderung von Motormoment durch ACC.

0xFF = nicht definiert";
CM_ SG_ 866 Sender_Info "Kennung für Empfänger (ESP, Getriebe), ob GRA oder ACC im Fahrzeug

0x0 = Sender ist Motor
0x1 = Sender ist ACC ";
CM_ SG_ 866 Sollbeschl_Getr "Vorgesehen für Nutzung mit CVT-Getriebe. Das Signal wird nicht mehr in Motor_6 gespiegelt, sondern sollte direkt vom Getriebe eingelesen werden. Die exakte Spezifikation des Signals 'Sollbeschleunigung' (vgl. mit dem Signal Verzögerungsanforderung) und di";
CM_ SG_ 866 Status_ACC "'ACC OFF' bedeutet ACC-Hauptschalter ist 'Gerastet Aus

'ACC Reversibler Fehler' bedeutet, daß das ACC aktuell einen 
reversiblen Fehler im ACC-SG selbst oder in einem zum 
ACC-System gehörenden SG erkennt.

'ACC irreversibler Fehler' bedeutet, daß ";
CM_ SG_ 866 Verhinderung_SA "0x0  = Schubabschaltung zulässig
0x1 = Schubabschaltung nicht zulässig";
CM_ SG_ 866 Verzoeg_Anf_ACC "Verzögerungsanforderung an die Bremse.

0xA6 = Init";
CM_ SG_ 866 Vorbefuellung_Bremsanlage "Zur Beschleunigung des Einsetzens einer ECD-Bremsung nach ACC-Anforderung.

0x0 = keine Vorbefüllung
0x1 = Bremsanlage Vorbefüllung";

CM_ SG_ 80 Airbag_deaktiviert "Airbag oder Gurtstraffer wurden per Anpassung deaktiviert: Aktualisierung erst nach Selbsttest

0x0 = Airbag aktiv
0x1 = Airbag deaktiviert";
CM_ SG_ 80 Airbag_im_Stellgliedtest "Information, ob Airbag im Stellgliedtest ist, um eine Notrufauflösung beim Stellgliedtest zu verhindern

0x0 = Airbag nicht im Stellgliedtest
0x1 = Airbag im Stellgliedtest";
CM_ SG_ 80 Airbag_in_Diagnose "0x0 = Airbag nicht in Diagnose
0x1 = Airbag in Diagnose";
CM_ SG_ 80 Airbag_Lampe "Sicherheitswarnlampe im Kombi wird vom Airbag-SG angesteuert; Zustand der Lampe wird auf dem CAN-Bus ausgegeben (auch Blinkinformation).

0x0 = Lampe aus
0x1 = Lampe ein";
CM_ SG_ 80 Airbag_Systemfehler "Ggf. wird Warnlampe dauernd eingeschaltet.

0x0 = kein Fehler
0x1 = Systemfehler";
CM_ SG_ 80 Beifahrerairbag_deaktiviert "Als Option vorgehalten, Beifahrerairbag wurden per Schlüsselschalter oder Insassenerkennung deaktiviert

0x0 = Beifahrerairbag aktiv
0x1 = Beifahrerairbag deaktiviert";
CM_ SG_ 80 BZ_Airbag1 "Freilaufender 4Bit-Botschaftszähler";
CM_ SG_ 80 CHK_Airbag1 "XOR über Summe aller Bytes siehe High-Speed-CAN-Lastenheft";
CM_ SG_ 80 Crash_Intensitaet "Die folgende Auswertung ist bei VW geplant:
>= 0x1: ZV auf
>= 0x2: Notruf ausgelöst
>= 0x4: Kraftstoffabschaltung (mit RDW-Schwelle aktiviert, d.h.Bit 7 = 1); 

Information bleibt bei jeder Schwellwert-überschreitung für ~1 s bestehen 
(Achtung: Ene";
CM_ SG_ 80 Front_Crash "Bit wird bei Überschreitung der Gurtstraffer-, US- und RdW-Schwelle gesetzt

0x0 = kein Front-Crash
0x1 = Front-Crash";
CM_ SG_ 80 FSPE_Airbag "Bei gesetztem Bit ist mindestens ein Kundendienstfehler eingetragen

0x0 = kein KD_Fehler eingetragen
0x1 = KD_Fehler eingetragen

";
CM_ SG_ 80 Gurtschlossabfrage_Beifahrer "Schalterinformation Gurtschloß Beifahrer

0x0 = nicht verfügbar
0x1 = Fehler
0x2 = Gurt nicht gesteckt
0x3 = Gurt gesteckt

";
CM_ SG_ 80 Gurtschlossabfrage_Fahrer "Schalterinformation Gurtschloß Fahrer

0x0 = nicht verfügbar
0x1 = Fehler
0x2 = Gurt nicht gesteckt
0x3 = Gurt gesteckt";
CM_ SG_ 80 Gurtwarnung_Beifahrer "Beifahrer hat Gurt nicht gesteckt, Anzeige im Kombi

0x0 = keine Warnung
0x1 = Gurtwarnung auslösen";
CM_ SG_ 80 Heck_Crash "Wird für alle neu anlaufenden Projekte umgesetzt: AB8.4, Audi8/VW8

0x0 = kein Heck-Crash
0x1 = Heck-Crash";
CM_ SG_ 80 Rollover "Wird im B6/B7 Cabrio und New Beetle Cabrio bedient.

0x0 = kein Rollover
0x0 = Rollover";
CM_ SG_ 80 Seiten_Crash_Beifahrer "Z.Zt. nur in Verbindung mit Crash-Intensität >= 100b (Kraftstoffpumpenabschaltung) verwendet.

0x0 = kein Seiten Crash Beifahrer
0x1 = Seiten Crash Beifahrer";
CM_ SG_ 80 Seiten_Crash_Fahrer "Z.Zt. nur in Verbindung mit Crash-Intensität >= 100b (Kraftstoffpumpenabschaltung) verwendet.

0x0 = kein Seiten Crash Fahrer
0x1 = Seiten-Crash Fahrer";

CM_ SG_ 1360 Belegerkenn_Beifahrersitz "Wird in US-Steuergeräten Audi8R/VW8R/AB8.4E++ bedient, optional bei der RdW, falls SBE_EuroNCAP entschieden wird.

0x0 = Beifahrer nicht verfügbar
0x1 = Beifahrer Fehler
0x2 = Beifahrer nicht belegt
0x3 = Beifahrer belegt";
CM_ SG_ 1360 Belegerkenn_hinten_Beifahrer "Belegungserkennung über Gurt-Wickelband

0x0 = hinten Beifahrer nicht verfügbar
0x1 = hinten Beifahrer Fehler
0x2 = hinten Beifahrer nicht belegt
0x3 = hinten Beifahrer belegt";
CM_ SG_ 1360 Belegerkenn_hinten_Fahrer "Belegungserkennung über Gurt-Wickelband

0x0 = hinten Fahrer nicht verfügbar
0x1 = hinten Fahrer Fehler
0x2 = hinten Fahrer nicht belegt
0x3 = hinten Fahrer belegt";
CM_ SG_ 1360 Belegerkenn_hinten_Mitte "Belegungserkennung über Gurt-Wickelband

0x0 = hinten Mitte nicht verfügbar
0x1 = hinten Mitte Fehler
0x2 = hinten Mitte nicht belegt
0x3 = hinten Mitte belegt";
CM_ SG_ 1360 CHK_Airbag2 "XOR über Summe aller Bytes siehe High-Speed-CAN-Lastenheftheft";
CM_ SG_ 1360 Erhoehung_Aufmerk_BFS "Der Fahrer soll bei einem Statuswechsel des Beifahrerairbags (ausgelöst durch die Beifahrerinsassenerkennung oder den Schlüsselschloßschalter) aufmerksam gemacht werden durch eine Anzeige im Kombi. Nur Audi: gültig für: AB2 (4-Türer AU352), B7, C6, D3

";
CM_ SG_ 1360 OOP_Beifahrer "OOP = Out of Position

0x0 = Nicht verfügbar
0x1 = Fehler
0x4 = Fahrer in Position
0x5 = Fahrer out of position 70%
0x6 = Fahrer out of position 30%";
CM_ SG_ 1360 OOP_Fahrer "OOP = Out of Position

0x0 = Nicht verfügbar
0x1 = Fehler
0x4 = Fahrer in Position
0x5 = Fahrer out of position 70%
0x6 = Fahrer out of position 30%";

CM_ SG_ 882 Abschalt_Heizsysteme "Bit 0 = 1 :  Abschaltung FSH und PTC Heizung; 
Bit 1 = 1 :  Abschaltung HSH, Sitzhzg, Aussenspiegelhzg, Lenkradhzg
Bit 2 = reserviert";
CM_ SG_ 882 Abschaltstufen "0x0 = Stufe 0; 0x1 = Stufe 1; 0x2 = Stufe 2; 0x3 = Stufe 3; 0x4 = Stufe 4; 0x5 = Stufe 21; 0x6 = Stufe 5; 0x7 = Stufe 6";
CM_ SG_ 882 Anforderung_HSH "1 = HSH soll  eingeschaltet werden. Wird gesetzt, wenn die Stabilität des Energienetzes diagnostiziert werden soll";
CM_ SG_ 882 BEM_Batteriespannung "Spannungsmessung vom Energiemanagement (Bordnetzbatterie); FFh = Fehler";
CM_ SG_ 882 BZ_BEM1 "Botschaftszaehler zur Lebenderkennung";
CM_ SG_ 882 CHK_BEM1 "XOR über Summe aller Bytes
siehe High-Speed-CAN-Lastenheft";
CM_ SG_ 882 Einschaltung_PTC_Hzg "00:alle Stufen ausgeschaltet
01:300W-Stufe eingeschaltet
10: 2x300W-Stufe eingeschaltet
11:beide Stufen eingeschaltet";
CM_ SG_ 882 Generator_Lastmoment "Wird vom MSG zur Berechnung der Motorlast benoetigt. Genauigkeit ca. +/- (5Nm + 20% vom Messwert). Dieser Wert ist statisch, d.h. Momentaufnahme durch Änderung der Generatorgeschwindigkeit ist nicht b";
CM_ SG_ 882 Generator_Leistungsaufnahme "Wird vom MSG zur Berechnung der Motorlast benoetigt. Genauigkeit ca. +/- (500W + 20% vom Messwert). Dieser Wert ist statisch, d.h. Momentaufnahme durch Änderung der Generatorgeschwindigkeit ist nicht ";
CM_ SG_ 882 HL_Systeme_Status "0000 = idle; 0001 = Reserve 1; 0010 = Reserve 2; 0011 = Reserve 3; 0100 = Überlast 4; 0101 = Überlast 3; 0110 = Überlast 2; 0111 = Überlast 1; 1xxx = undef";
CM_ SG_ 882 HL_Systemregelung_Status "0 = Regelung inaktiv, 1 = Regelung aktiv";
CM_ SG_ 882 Lastabwurf_Rueckmeldung "Rueckmeldung ueber Lastabwurf fuer Notlauf.
Stufe 0:  keine Reduktion
Stufe 1:  Reduktion Generatorspg. = 13,3V
Stufe 2:  Reduktion Generatorspg. = 12,6V
Stufe 3:  Reduktion Generatorspg. = 11,8V";
CM_ SG_ 882 Leerlaufdrehzahl_Erhoehung "Anforderung einer Leerlaufdrehzahlanhebung in 2 Stufen. Die Höhe der LL-Stufen ist im MSG appliziert.
Bit 1 Bit 0 
00 keine Erhoehung 
01 Stufe 1
10 Stufe 2
11 nicht def.";
CM_ SG_ 882 Load_Response_Generator "Bestaetigung der vom MSG angeforderten Load-Response-Time unter Angabe des Wertes. Diese Massnahme darf nur kurzfristig bzw. als Notlauf wirksam sein.";
CM_ SG_ 882 Red_Innenraumgeblaese "00 = nix, 01 = Reduzierung Stufe 1, 02 = Reduzierung Stufe 2, Reduzierung Stufe 3 (= Abschaltung Kompressor)


";
CM_ SG_ 882 Ruecknahme_HSH "1 = Heckscheibenheizung soll ausgeschaltet werden";

CM_ SG_ 416 ABS_Bremsung "Antiblockiersystem, Bit zeigt auch Druckabbau an (z.B. ESP hat zuviel Druck aufgebaut oder ungebremste Regelung auf Bahnübergang)

0x0 = keine ABS-Regelung
0x1 = ABS-Regelung";
CM_ SG_ 416 Aktiver_BKV "neues Status-Bit zur Vermeidung von Problemen während der Übergangszeit auf die neue Definition (BKV) und zur Darstellung des Fehlerzustandes: nur noch in T5 und im Colorado und AU716

0x0 = Aktiver BKV nicht verbaut oder Fehler
0x1 = Aktiver BKV verba";
CM_ SG_ 416 ASR_Anforderung "Die Momentenanforderung 'ASR Eingriffsmoment langsam' Byte 5 und 'ASR Eingriffsmoment schnell' Byte 6 sind auszuführen.

0x0 = keine Anforderung
0x1 = ASR-Anforderung";
CM_ SG_ 416 ASR_Schaltbeeinflussung "Wunsch an das Getriebe während einer ASR Regelung, bei Audi nur 0x0 und 0x1 genutzt

0x0 = keine Anforderung
0x1 = ASR-Schaltkennfeld
0x2 = Rückschaltung
0x3 = Schaltverbot

";
CM_ SG_ 416 ASR_Steuergeraet "Codierinformation für Kombi.Ggf. wird die ASR-Lampe angesteuert.

0x0 = ABS, ABS/EDS
0x1 = ASR, ESP, MABS";
CM_ SG_ 416 BKL "Rote Lampe wird angesteuert, bspw. bei EBV-Ausfall; Sicherheitswarnlampe im Audi C6/D3/AU716. (Blinktakt wird wie bisher vom Kombi generiert). Separate Bremskontroll-Lampe (Audi ab D3/C6) wird als Sicherheitswarnlampe aufgeprüft (Initwert 1); Kombinierte ";
CM_ SG_ 416 Bremslichtschalter_ESP "Signalnamenunterscheidung:

Bosch: Signalname 'Bremslichtschalter' (HW-Signal)
ContiTEVES mit aktivem Bremskraftsverstärker: 'Fahrer bremst' (kein BLS vorhanden!)

Ohne BKV wird hier der Bremslichtschalter (0 kein Bremsen, 1 Bremse betätigt) übertrag";
CM_ SG_ 416 Bremstestschalter_ESP "Beim Bosch-ABS wird der Bremstestschalter (0 kein Bremsen, 1 Bremse betätigt) übertragen ab PQ46: Druckschwelleninformation (Byte 2, Bit 3) kann noch nicht oder aufgrund eines Fehlers nicht ausgegeben werden

0x0 = kein Bremsen
0x1 = Bremse betätigt
";
CM_ SG_ 416 EBV_Eingriff "Elektronische Bremskraftverteilung, aktueller Eingriff (Druckhalten, Druckabbau), kein ABS / ESP-Eingriff

0x0 = kein EBV-Eingriff
0x1 = EBV-Eingriff";
CM_ SG_ 416 EDS_Eingriff "Elektronische Differentialsperre

0x0 = kein EDS-Eingriff
0x1 = EDS-Eingriff";
CM_ SG_ 416 ESP_Eingriff "Eingriff des Fahrdynamikreglers

0x0 = kein ESP-Eingriff
0x1 = ESP-Eingriff";
CM_ SG_ 416 ESP_passiv_getastet "ESP oder ASR vom Fahrer passiv getastet 

0x0 = ESP aktiviert
0x1 = ESP passiv getastet

Andere Bedeutung im AU716:

Offroad Modus

0x0 = ESP aktiviert
0x1 = ESP offroad mode";
CM_ SG_ 416 ESP_Systemstatus "Fehler steht für Stillegung ESP mit Fehlereintrag

0x0 = OK
0x1 = Fehler";
CM_ SG_ 416 Fahrer_bremst "Fahrer bremst bzw. bremst stärker als aktives Bremssystem (nur benötigt für aktive Bremssysteme, die das Bremspedal mitziehen). Zusatzinfo: Signal muß zusammen mit Status BLS (Bremse8, Byte8, Bit5) bewertet werden (Gültigkeit)";
CM_ SG_ 416 FStatus_Schlechtwegausblendung "Initwert 1 wird gesendet, wenn Funktion nicht umgesetzt
ESP 5.7 = Im ESP-Fehlerfall ist Bit ungültig
ESP 8 = Im ESP-Fehlerfall ist Bit weiterhin gültig

0x0 = gültig
0x1 = ungültig
";
CM_ SG_ 416 Geschwindigkeit_15Bit "Wertebereich geht von 0x0000 bis 0x7F7F (^=32639). Ungültiger Wertebereich von 0x7F7F bis 0x7FC3

Spezielle Werte im ungültigen Wertebereich:

0x7FC4 = V_INIT
0x7FD5 = V_USPG
0x7FE6 = V_FEHLER";
CM_ SG_ 416 Geschwindigkeitersatzwert "Geschwindigkeit wird als Ersatzwert ausgegeben, bspw. wenn ein Sensor defekt oder kein Radumfang gelernt ist. Bei Contiteves und passiven Sensoren wird der Wert des Hinterrades eingespiegelt.

0x0 = iO
0x1 = Ersatzwert";
CM_ SG_ 416 Lampe_ABS "Sicherheitswarnlampe

0x0 = Lampe aus
0x1 = Lampe ein";
CM_ SG_ 416 Lampe_ASR_ESP "Zustand der Lampe wird auf dem CAN-Bus ausgegeben (auch Blinkinformation) Fahrzeuge mit ASR/ESP/MABS-Funktionalität bedienen die
Sicherheitswarnlampe

0x0 = Lampe aus
0x1 = Lampe ein";
CM_ SG_ 416 MSR_Anforderung "Die Momentenanforderung 'MSR Eingriffsmoment' in Byte 7 ist auszuführen.

0x0 = keine Anfoderung
0x1 = MSR-Anforderung";
CM_ SG_ 416 Schlechtwegausblendung "OBD-Funktion (MAD-Signal), wird bei Teves / TRW nicht ausgegeben, für Plausibilisierung im Motor wegen Zündaussetzererkennung

0x0 = keine Schlechtwegausblendung
0x1 = Schlechtwegausblendung

";
CM_ SG_ 416 Status_aktives_Bremssystem "Bei einem aktiven BKV wird im angesteuerten Zustand (bspw. bei ESP-Eingriff oder ADR-Bremsung) ohne Beeinflussung des Fahrers das Bremspedal betätigt. In Bremse_1(Byte 2, Bit 3) ist ersichtlich, ob der Fahrer den aktiven BKV übertritt;

0x0 = Aktiver BK";

CM_ SG_ 1440 Akustische_Warnung "1: Bremse steuert den Gong im Kombi ein Mal an
2: Bremse steuert den Gong (oder Summer) im Kombi drei Mal an, z.Zt. nur in Kombination mit Text Werkstatt Bremse (Ausfall der EBV)
3: Summeransteuerung ist durch Kombi auf 1 Sekunde festgelegt. Auslösung d";
CM_ SG_ 1440 BKL "Rote Lampe wird angesteuert, bspw. bei EBV-Ausfall; Sicherheitswarnlampe im Audi C6/D3/AU716. (Blinktakt wird wie bisher vom Kombi generiert). Separate Bremskontroll-Lampe (Audi ab D3/C6) wird als Sicherheitswarnlampe aufgeprüft (Initwert 1); Kombinierte ";
CM_ SG_ 1440 Bremskontroll_Blinkmode "Bremskontroll-Lampe soll im Warnfall mit 1Hz blinken, wenn das Bit gesetzt ist, aktuell nur bei VW implementiert (TRW-Bremse im PQ46)

0x0 = BKL blinkt nicht 
0x1 = BKL blinkt mit 1 Hz";
CM_ SG_ 1440 BZ_Bremse2 "Freilaufender 4Bit-Botschaftszähler";
CM_ SG_ 1440 FStatus_Wegimpulse "Fehler wird gesetzt, wenn beide ABS-Drehzahlfühler an der Hinterachse defekt sind.

0x0 = Wegimpulse iO
0x1 = Fehler";
CM_ SG_ 1440 Gemessene_Querbeschleunigung "Querbeschleunigung in Byte1 wird entweder per Sensorwert gemessen oder im ESP errechnet.

0x0 = errechnet
0x1 = gemessen";
CM_ SG_ 1440 Lampe_ABS "Sicherheitswarnlampe

0x0 = Lampe aus
0x1 = Lampe ein";
CM_ SG_ 1440 Lampe_ASR_ESP "Zustand der Lampe wird auf dem CAN-Bus ausgegeben (auch Blinkinformation) Fahrzeuge mit ASR/ESP/MABS-Funktionalität bedienen die
Sicherheitswarnlampe

0x0 = Lampe aus
0x1 = Lampe ein";
CM_ SG_ 1440 Mittlere_Raddrehzahl "Radumdrehungen pro Sekunde sind Eingangsgröße für die Geschwindigkeitsberechnung im Kombi; es wird der Mittelwert der permanent angetriebenen Räder (alle außer Audi B6/D3) ausgegeben oder bei Audi B6/D3 die Geschwindigkeit des linken Vorderrades; im Kombi";
CM_ SG_ 1440 Mux_Code_Bremse2 "Multiplexer schaltet Byte 1 hat in der Hochlaufphase um (Boschsystem: ca. 2s, Contisystem: ca. 1,7s). Es wird zwischen Querbeschleunigung und Zähnezahl gemultiplext, es wird die Zähnezahl des Impulsrades ausgegeben.

0x0 = Querbeschleunigung übertragen";
CM_ SG_ 1440 QBit_Querbeschleunigung "Querbeschleunigung wird vom ESP aus Ersatzwerten errechnet, wenn Bit gesetzt ist. Güte des Signals ist verändert.

0x0 = gültiger Wert
0x1 =  Ersatzwert oder Initwert";
CM_ SG_ 1440 Querbeschleunigung "Zur Kurvenfahrterkennung für das Getriebe; Muss zusammen mit QBit (Bremse_2, Byte 7, Bit6) ausgewertet werden; Qualität des Signals ist abhängig, ob als gemessene oder berechnete Grösse ausgegeben (siehe Bit 'Gemessene Querbeschleunigung', Byte 8, Bit 7)";
CM_ SG_ 1440 Textbits_Bremse "0x0 = Kein Text
0x1 = ESP Störung
0x2 = ABS Störung
0x3 = ESP/ABS Störung
0x4 = Werkstatt Bremse
0x5 = ASR Störung
0x6 = ESP Deaktiviert
0x7 = ASR Deaktiviert;  im AU716: ESP offroad
0x8 = ESP Aktiviert
0x9 = Störung Hillholder
0xA = Keine Brems";
CM_ SG_ 1440 Warnlampe_RKA "Betrifft aktuell nur ContiTEVES-System im PQ35. Reifen-Kontroll-Anzeige im Kombi.

0x0 = Lampe aus
0x1 = Lampe ein

";
CM_ SG_ 1440 Wegimpulszaehlerstatus "Der Wegimpulszähler ist mindestens einmal übergelaufen (Reset des ABS-Steuergerätes) kann damit erkannt werden.

0x0 = Reset und kein Überlauf
0x1 = mindestens 1x Überlauf";
CM_ SG_ 1440 Zaehnezahl "Zähnezahl des verwendeten Impulsrades wird ausgegeben.";

CM_ SG_ 1184 Fahrtrichtung_HL "Fahrtrichtungserkennung Rad Hinten Links

0x0 = Vorwärts
0x1 = Rückwärts

ACHTUNG: Im AU716 wird ein abweichender Wert für den Stillstand bedient! Im Stillstand wird 0x1 ausgegeben.";
CM_ SG_ 1184 Fahrtrichtung_HR "Fahrtrichtungserkennung Rad Hinten Rechts

0x0 = Vorwärts
0x1 = Rückwärts

ACHTUNG: Im AU716 wird ein abweichender Wert für den Stillstand bedient! Im Stillstand wird 0x1 ausgegeben.";
CM_ SG_ 1184 Fahrtrichtung_VL "Fahrtrichtungserkennung Rad Vorne Links

0x0 = Vorwärts
0x1 = Rückwärts

ACHTUNG: Im AU716 wird ein abweichender Wert für den Stillstand bedient! Im Stillstand wird 0x1 ausgegeben.";
CM_ SG_ 1184 Fahrtrichtung_VR "Fahrtrichtungserkennung Rad Vorne Rechts

0x0 = Vorwärts
0x1 = Rückwärts

ACHTUNG: Im AU716 wird ein abweichender Wert für den Stillstand bedient! Im Stillstand wird 0x1 ausgegeben.";
CM_ SG_ 1184 Radgeschw_HL "Radgeschwindigkeit bezieht sich auf den Reifenumfang Kombi_3

0x7FC4 = V_INIT
0x7FD5 = V_USPG
0x7FE6 = V_FEHLER";
CM_ SG_ 1184 Radgeschw_HR "Radgeschwindigkeit bezieht sich auf den Reifenumfang Kombi_3

0x7FC4 = V_INIT
0x7FD5 = V_USPG
0x7FE6 = V_FEHLER";
CM_ SG_ 1184 Radgeschw_VL "Radgeschwindigkeit bezieht sich auf den Reifenumfang Kombi_3

0x7FC4 = V_INIT
0x7FD5 = V_USPG
0x7FE6 = V_FEHLER";
CM_ SG_ 1184 Radgeschw_VR "Radgeschwindigkeit bezieht sich auf den Reifenumfang Kombi_3

0x7FC4 = V_INIT
0x7FD5 = V_USPG
0x7FE6 = V_FEHLER";

CM_ SG_ 1192 Anfahrhilfe_aktiv "Anfahrhilfe (aktiver Bremsbooster) wird angesteuert (bisher nur Colorado/T5, nicht PQ35)

0x0 = nicht aktiv
0x1 = aktiv";
CM_ SG_ 1192 AWV2_Durchfuehrung_Bremsruck "Rückmeldung von der Bremse an ACC, dass der angeforderte AWV2-Bremsruck aktuell ausgeführt wird

0x0 = kein Bremsruck durchgeführt
0x1 = Bremsruck wird durchgeführt";
CM_ SG_ 1192 Bremsdruck "Low_Byte = Byte 1; High_Byte = Byte 2; Realer Meßbereich 0..170 bar, aktueller nicht offsetkorrigierter Bremsdruck im Hauptbremszylinder (ungefiltert)

Muss zusammen mit Bremsdruck ungültig (Bremse_5, Byte 4, Bit 5) und Status_Bremsdruck (Bremse_5, Byte";
CM_ SG_ 1192 Bremsdruck_ungueltig "QBit des Bremsdrucks

0x0 = gültig
0x1 = ungültig";
CM_ SG_ 1192 Bremsentemperatur "Aus Modell errechnet, bedient in den RB-Projekten Audi D3, C6; nicht ContiTEVES Mk60";
CM_ SG_ 1192 FStatus_Anfahrhilfe "Ausgabe eines niO-Systems: Bei gesetztem Fehler steht die Anfahrhilfe nicht zur Verfügung (bisher nur Colorado/T5, nicht PQ35). Ist die Anfahrhilfe generell in der SW nicht vorhanden wird 0x0 ausgegeben.

0x0 = kein Fehler
0x1 = Fehler";
CM_ SG_ 1192 Geschwindigkeitsueberwachung "Funktion Geschwindigkeitsüberwachung ist aktuell verfügbar, die Bits in Getriebe1 werden beachtet. Z.Zt. nur im Colorado.

0x0 = Geschwindigkeitsüberwachung nicht verfügbar
0x1 = Geschwindigkeitsüberwachung verfügbar
";
CM_ SG_ 1192 Giergeschwindigkeit "Low_Byte = Byte 1; High_Byte = Byte 2; Nicht offsetkorrigierte, gemessene Giergeschwindigkeit
tatsächliche Auflösung Bosch ESP: 0,27 Grad/s

0x3FFF = Fehler
";
CM_ SG_ 1192 Gierrate_ungueltig "Keine Filterung; ungültiger Wert kann bspw. aufgrund einer Unterspannung oder in der Initialisierungsphase ausgegeben werden. 

Beim AU716 auch während eines Sensortests!

QBit der Giergeschwindigkeit

0x0 = gültig
0x1 = ungültig";
CM_ SG_ 1192 Notfallblinken "Automatische Aktivierung des Warnblinkers und Bremsflächenvergrösserung bei Notbremsung. Funktion im ESP8 und ILM-Hinten ab Audi C6 erstmalig implementiert.

0x0 = keine Notbremsung erkannt
0x1 = Notbremsung erkannt";
CM_ SG_ 1192 Reifentoleranzabgleich_VR "Physikalischer Wertebereich +/-5%. Der Reifentoleranzabgleich bezieht sich auf das linke Vorderrad.

physikalischer Wert = ((HexWert-0x7F)/2048)*100%

0xFE = Abgleich noch nicht genügend konvergent
0xFF = Fehler


";
CM_ SG_ 1192 Rueckfallebene_ECD "Bit wird gesetzt, wenn das ESP einen Hardwarefehler (Drucksensor) erkannt hat; im Fehlerfall wird das interne Druckmodell herangezogen; Folge: unkomfortableres ACC, erstmalig umgesetzt Audi C6

0x0 = iO
0x1 = Fehler Drucksensor";
CM_ SG_ 1192 Signum_Bremsdruck "0x0 = positiv
0x1 = negativ";
CM_ SG_ 1192 Signum_Giergeschwindigkeit "0x0 = Giergeschwindigkeit positiv
0x1 = Giergeschwindigkeit negativ";
CM_ SG_ 1192 Status_Bremsdruck_ESP_System "Zur Plausibilisierung: Bremsdruck wird vom ESP aufgebaut bspw. Vorladepumpe. Nachlauf muß vom Empfänger berücksichtigt werden. Bei RB ESP 5.7, ESP 8 und CT Mk60 wird immer 0 ausgegeben, weil Drucksignal am Hauptbremszylinder nicht von Vorladepumpe kommen ";
CM_ SG_ 1192 Stillstandsflag "Fahrzeug steht (Algorithmus im Bremsensteuergerät) im PQ35/46 alle 4 Radgeschwindigkeiten 0.
Im AU716: Wenn alle DF Stillstand erkannt haben und Fahrzeug über Modellberechnung keine Bewegung zeigt wird Stillstand ausgegeben.

0x0 = kein Stillstand erka";
CM_ SG_ 1192 TSP_aktiv "Wenn TSP-Regelung (Trailer Stability Program) zu einer Verzögerung bspw. > 0,4g führt, wird das Bit gesetzt: im Colorado zusätzlich zum Hardwareausgang, in PQ35 / PQ46 ohne Hardwareausgang

0x0 = keine Bremslichtanforderung
0x1 = Bremslicht an";

CM_ SG_ 428 Fahrer_bremst "Fahrer bremst bzw. bremst stärker als aktives Bremssystem (nur benötigt für aktive Bremssysteme, die das Bremspedal mitziehen). Zusatzinfo: Signal muß zusammen mit Status BLS (Bremse8, Byte8, Bit5) bewertet werden (Gültigkeit)";
CM_ SG_ 428 Laengsbeschleunigung "offsetkorrigierter, gefilterter Wert";
CM_ SG_ 428 QBit_Laengsbeschleunigung "0x0 = gültiger Wert
0x1 =  Ersatzwert oder Initwert";
CM_ SG_ 428 Status_aktives_Bremssystem "Bei einem aktiven BKV wird im angesteuerten Zustand (bspw. bei ESP-Eingriff oder ADR-Bremsung) ohne Beeinflussung des Fahrers das Bremspedal betätigt. In Bremse_1(Byte 2, Bit 3) ist ersichtlich, ob der Fahrer den aktiven BKV übertritt;

0x0 = Aktiver BK";
CM_ SG_ 428 Status_BLS "Gültigkeit für Info 'Fahrer bremst' in Bremse1 und Bremse8";
CM_ SG_ 428 Status_Bremsdruck "Bei gesetztem Bit liegt p>2bar an; Modelldruck, hervorgerufen durch Fahrer, ECD, FZR, BMR";
CM_ SG_ 428 Status_HW_BLS_Ausgang "Bit signalisiert, Bremslichtschalterausgang defekt ist.";

CM_ SG_ 1524 Antriebsvariante "Ausgegeben wird die Antriebsvariante zur Codierplausibilisierung im ESP-Steuergerät";
CM_ SG_ 1524 Bremsenvariante "00H keine Variante hinterlegt";
CM_ SG_ 1524 CHK_Bremse_Codierinfo "XOR über Summe aller Bytes
siehe High-Speed-CAN-Lastenheft";

CM_ SG_ 2000 Datum_Monat "alle anderen Werte ungültig";
CM_ SG_ 2000 Datum_Tag "alle anderen Werte ungültig";
CM_ SG_ 2000 Kilometerstand "Low Byte 6, High Byte 7 und in Byte 8 Bit 3..0 (additiv); Wertebereich geht bis (220 - 1), Fehler wird ausgegeben, falls Kilometerstand nicht restaurierbar

0xFFFFF = Fehler
";
CM_ SG_ 2000 Kilometerstand_alt "0 = aktuell; 1 = Wert veraltet";
CM_ SG_ 2000 Time_Indication_Bit "im D3 immer 0 !!";
CM_ SG_ 2000 Uhrzeit_Minute "alle anderen Werte ungültig";
CM_ SG_ 2000 Uhrzeit_Sekunde "alle anderen Werte ungültig";
CM_ SG_ 2000 Uhrzeit_Stunde "alle anderen Werte ungültig";
CM_ SG_ 2000 Verlernzaehler "Binär, wrap around; 0xFF = ungültiger Zählerstand / kein gültiger Fahrzyklus¿;";
CM_ SG_ 2000 Zeit_alt "0 = aktuell; 1 = Wert veraltet";

CM_ SG_ 1472 Anforderung_Shift_Lock_Lampe "EPB kann manuell nur bei betätigter Fußbremse geöffnet werden. Wenn Bit gesetzt ist zeigt PQ46-Kombi die Shift-Lock-Lampe an.

0x0 = Shift Lock Lampe nicht angefordert
0x1 = Shift Lock Lampe angefordert";
CM_ SG_ 1472 Auto_Oeffnen_Schliessen_erlaubt "Automatisches Schließen / Öffnen der EPB erlaubt. Aktuell nur bei Audi für CVT-Getriebe Projekte.

0x0 = Automatisches S/Ö nicht erlaubt
0x1 = Automatisches S/Ö erlaubt";
CM_ SG_ 1472 Bremslicht_dyn_Abbremsung "Bremslichtansteuerung bei dynamischer Abbremsung (nur im VW PQ46)

0x0 = Bremslicht aus
0x1 = Bremslicht ein";
CM_ SG_ 1472 BZ_EPB1 "Freilaufender 4Bit-Botschaftszähler";
CM_ SG_ 1472 CHK_EPB1 "XOR über Summe aller Bytes siehe High-Speed-CAN-Lastenheft";
CM_ SG_ 1472 Erreichte_Spannkraft "Erzeugte Spannkraft. Bezieht sich auf die Aktuatoren.

0x1F = Fehler";
CM_ SG_ 1472 Fehlerlampe_BKL "Die BKL dient als rote Fehlerlampe für die EPB. Sie wird vom EPB-SG aktiv ausgeschaltet.

0x0 = BKL aus
0x1 = BKL ein";
CM_ SG_ 1472 Fehlerlampe_Gelb_EPB "Fehlerlampe für nicht liegenbleiberreleavante Fehler

0x0 = Lampe aus
0x1 = Lampe ein";
CM_ SG_ 1472 Freig_Verz_anf_EPB "0x0 = Verzögerungsanforderung nicht freigegeben
0x1 = Verzögerungsanforderung freigegeben	";
CM_ SG_ 1472 FSPE_EPB "Bei gesetztem Bit ist mindestens ein Kundendienstfehler eingetragen

0x0 = kein KD_Fehler eingetragen
0x1 = KD_Fehler eingetragen
";
CM_ SG_ 1472 FStatus_EPB "0x0 = volle Funktion
0x1 = linke Seite fehlerhaft
0x2 = rechte Seite fehlerhaft
0x3 = beide Seiten fehlerhaft";
CM_ SG_ 1472 Funktionslampe_Auto_P "Fahrerwunsch 'Auto P': im Stillstand wird die Parkeinstellung eingenommen (nur im VW PQ46).

0x0 = Lampe aus
0x1 = Lampe ein";
CM_ SG_ 1472 Funktionslampe_EPB "Bit wird nur gesetzt, wenn volle Spannkraft auf beiden Seiten erreicht. PQ46: Bit wird gesetzt, wenn BKL direkt vom EPB-SG als Funktionslampe angesteuert wird.

0x0 = Lampe aus
0x1 = Lampe ein
";
CM_ SG_ 1472 KL15_Status_Info "KL15 am EPB-Steuergerät. EPB fungierte für das ESP 5.7 im D3 als Lieferant der KL15 Information, weil ESP 5.7 keine CAN-Objekte mehr frei hatte, um die KL15-Information aus dem ZAS_1/Klemmen_Status Botschaft zu entnehmen. SW-Signal für ESP 5.7, um zu erke";
CM_ SG_ 1472 Kupplungsmodulationsbereich "Nur für Handschalter. Wird auf 0x1 gesetzt, wenn das PWM-Signal des Kupplungspedalsensors im Bereich zwischen 80%-Signalpegel und Minimum liegt.  Der Zustand 10 kann derzeit nur von Audi bedient werden, da der PQ46-Sensor keine Plausibilisierung des Signa";
CM_ SG_ 1472 Neigungswinkel "Neigungswinkelsignal";
CM_ SG_ 1472 QBit_Neigungswinkel "Mitteilung z.Zt. für ACC, um unter bestimmten Zuständen mitzuteilen, daß Neigungswinkel temporär ungültig ist. Bsp.: Selbsttest Neigungswinkelsensor.

0x0 = gültiger Wert
0x1 =  Ersatzwert oder Initwert

";
CM_ SG_ 1472 Schalterinfo_EPB "Spiegelt die Schalterstellung wieder.

0x0 = keine Fahreranforderung
0x1 = Fahreranforderung Öffnen
0x2 = Fahreranforderung Schließen
0x3 = Schalterfehler";
CM_ SG_ 1472 Schalterstatus_EPB "Auch bei voller Funktion kann kurzfristig ein Schalterfehler vorliegen. 

0x0 = volle Funktion
0x1 = Schalter ausser Funktion";
CM_ SG_ 1472 SIB_EPB "Die Sleepbereitschaft wird nach KL15 aus durch Setzen dieses Bits signalisiert.

0x0 = 
0x1 = ";
CM_ SG_ 1472 Status_EPB "Gibt den Zustand der EPB-Aktuatoren an. Verknüpfung mit Fehlerstatus; wenn z.B. 'Linke Seite fehlerhaft' und 'Bremse geschlossen', dann ist nur die rechte Seite geschlossen. Das Bit wird gesetzt, wenn auf einer Seite Spannkraft aufgebaut wird. Wenn auf be";
CM_ SG_ 1472 Status_NWG "Funktion des Neigungswinkelsensors. Dauerhafter Ausfall oder Fehler Neigungswinkelgeber.

0x0 = volle Funktion
0x1 = keine Funktion";
CM_ SG_ 1472 Textmeldungen_EPB "0x0 = keine_Anzeige
0x1 = Neigungswinkel_zu_gross
0x2 = Parkbremse_von_Hand_oeffnen
0x3 = EPB_in_Diagnose
0x4 = Bremspedal_betaetigen
0x5 = Parkbremse_Motorlauf_schliessen";
CM_ SG_ 1472 Verschleissanzeige "Es wird der höhere Verschleiß zur Anzeige gebracht.

0x0 = Belagstärke > x mm
0x2 = Belagstärke < y mm

0x1, 0x3 sind nicht belegt";
CM_ SG_ 1472 Verz_anf_EPB "Steuerungsanforderung an andere Systeme (z.B. ESP), um während der Fahrt, durch den Handbremsschalter ausgelöst, zu bremsen (ECD-Funktion)";
CM_ SG_ 1472 Warnton_1 "PQ46-Kombi löst einmal Warnton aus; wird nur zusammen mit gelber Fehlerlampe (Byte 7, Bit 3) gesetzt

0x0 = Warnton 1 aus
0x1 = Warnton 1 ein
";
CM_ SG_ 1472 Warnton_2 "PQ46-Kombi löst dreimal Warnton aus;  wird zusammen mit roter Fehlerlampe (Byte 7, Bit 2) gesetzt

0x0 = Warnton 2 aus
0x1 = Warnton 2 ein


";
CM_ SG_ 1472 Warnton_EPB "Bit wird gesetzt, wenn bei v > 0 eine Fahreran-forderung schließen vorhanden ist (ECD angefordert). PQ46-Kombi sendet Warnton (600Hz) solange dieses Bit gesetzt ist.

0x0 = Warnton aus
0x1 = Warnton an
";

CM_ SG_ 912 AAG_BLS_unplausibel "1 = BLS Signal unplausibel";
CM_ SG_ 912 AAG_ECD_unplausibel "1 = ECD Signal unplausibel";
CM_ SG_ 912 Abblend_VL_def "1 = Abblendlicht_vl_defekt";
CM_ SG_ 912 Abblend_VR_def "1 = Abblendlicht_vr_defekt";
CM_ SG_ 912 Abblendlicht_aktiv "1 = Abblendlicht_aktiv";
CM_ SG_ 912 ACAN_Sleep_ACK "Sleep_ACK für indirektes Netzwerkmanagement im ACAN";
CM_ SG_ 912 Anhaenger_erkannt "1 = Anhaenger erkannt";
CM_ SG_ 912 Bremsl_3_def "1 = hochgesetzte  Bremsleuchte defekt";
CM_ SG_ 912 Bremsl_HL_def "1 = mindestens ein Bremslicht hinten links defekt";
CM_ SG_ 912 Bremsl_HR_def "1 = mindestens ein Bremslicht hinten rechts defekt";
CM_ SG_ 912 Bremslicht_AH_def "1 = Anhaenger Bremslicht defekt";
CM_ SG_ 912 Fernlicht_aktiv "1 = Fernlicht_aktiv";
CM_ SG_ 912 Nebellicht_aktiv "1 = Nebellicht_aktiv";
CM_ SG_ 912 Rueckfahrlicht_akt "1 = Rückfahrlicht aktiv";
CM_ SG_ 912 Rueckfahrlichtschalter_ein "1 = Rueckfahrlichtschalter_ein";
CM_ SG_ 912 SH_aktiv_Flag "1 = Standheizung ist bzw. war die letzte Stunde aktiv; 
Achtung : Bit ist in VW D1 anders belegt";
CM_ SG_ 912 SH_MVW "0 = SH ohne Motorvorwärmung (kl. Kreis); 1 = SH mit Motorvorwärmung (gr. Kreis); Achtung : Bit ist in VW D1 anders belegt";
CM_ SG_ 912 Warnblink_aktiv "1 = Warnblink_aktiv";
CM_ SG_ 912 Wischer_vorne_laeuft "1 = Wischer vorne läuft";

BA_DEF_  "GenNWMApBusSleep" STRING;
BA_DEF_  "GenNWMApCanNormal" STRING;
BA_DEF_  "GenNWMApCanOff" STRING;
BA_DEF_  "GenNWMApCanOn" STRING;
BA_DEF_  "GenNWMApCanSleep" STRING;
BA_DEF_  "GenNWMApCanWakeUp" STRING;
BA_DEF_  "GenNWMGotoMode_Awake" STRING;
BA_DEF_  "GenNWMGotoMode_BusSleep" STRING;
BA_DEF_  "GenNWMSleepTime" INT -2147483648 2147483647;
BA_DEF_  "GenNWMTalkNM" STRING;
BA_DEF_  "Manufacturer" STRING;
BA_DEF_  "NmBaseAddress" HEX 0 2047;
BA_DEF_  "NWM-BasisAdresse" HEX 0 2047;
BA_DEF_  "NmMessageCount" INT 1 255;
BA_DEF_  "NWMMessageCount" INT 1 64;
BA_DEF_  "NmType" STRING;
BA_DEF_  "NWM-Typ" ENUM "VAG-OSEK", "None";
BA_DEF_  "VAGTP20_SetupMessageCount" INT 0 255;
BA_DEF_  "VAGTP20_SetupStartAddress" HEX 0 2047;
BA_DEF_  "VersionDay" INT 1 31;
BA_DEF_  "VersionMonth" INT 1 12;
BA_DEF_  "VersionNumber" INT -2147483648 2147483647;
BA_DEF_  "VersionWeek" INT 1 52;
BA_DEF_  "VersionYear" INT 0 99;
BA_DEF_ BU_  "GenNodAutoGenDsp" ENUM "No", "Yes";
BA_DEF_ BU_  "GenNodAutoGenSnd" ENUM "No", "Yes";
BA_DEF_ BU_  "GenNodSleepTime" INT -2147483648 2147483647;
BA_DEF_ BU_  "iLUsed" ENUM "No", "Yes";
BA_DEF_ BU_  "NmCAN" INT 1 2;
BA_DEF_ BU_  "NmNode" ENUM "No", "Yes";
BA_DEF_ BU_  "NWM-Knoten" ENUM "No", "Yes";
BA_DEF_ BU_  "NmStationAddress" HEX 0 63;
BA_DEF_ BU_  "NWM-StationsAdresse" HEX 0 63;
BA_DEF_ BU_  "NodeLayerModules" STRING;
BA_DEF_ BU_  "VAGTP20_TargetAddress" HEX 0 127;
BA_DEF_ BO_  "GenMsgAutoGenDsp" ENUM "No", "Yes";
BA_DEF_ BO_  "GenMsgAutoGenSnd" ENUM "No", "Yes";
BA_DEF_ BO_  "GenMsgCycleTime" INT 0 65535;
BA_DEF_ BO_  "GenMsgCycleTimeFast" INT 0 65535;
BA_DEF_ BO_  "GenMsgDelayTime" INT 0 100000;
BA_DEF_ BO_  "GenMsgILSupport" ENUM "No", "Yes";
BA_DEF_ BO_  "GenMsgSendType" ENUM "cyclicX", "spontanX", "cyclicIfActiveX", "spontanWithDelay", "cyclicAndSpontanX", "cyclicAndSpontanWithDelay", "spontanWithRepetition", "cyclicIfActiveAndSpontanWD", "cyclicIfActiveFast", "cyclicWithRepeatOnDemand";
BA_DEF_ BO_  "GenMsgStartDelayTime" INT 0 100000;
BA_DEF_ BO_  "NmMessage" ENUM "No", "Yes";
BA_DEF_ BO_  "NWM-Botschaft" ENUM "No", "Yes";
BA_DEF_ BO_  "VAGTP20_API" HEX 0 255;
BA_DEF_ BO_  "VAGTP20_DynConnection" ENUM "No", "Yes";
BA_DEF_ BO_  "VAGTP20_DynSetup" ENUM "No", "Yes";
BA_DEF_ BO_  "VAGTP20_StatConnection" ENUM "No", "Yes";
BA_DEF_ SG_  "GenSigAltSetting" STRING;
BA_DEF_ SG_  "GenSigAssignSetting" STRING;
BA_DEF_ SG_  "GenSigAutoGenDsp" ENUM "No", "Yes";
BA_DEF_ SG_  "GenSigAutoGenSnd" ENUM "No", "Yes";
BA_DEF_ SG_  "GenSigConditionalSend" STRING;
BA_DEF_ SG_  "GenSigEnvVarType" ENUM "int", "float", "undef";
BA_DEF_ SG_  "GenSigEVName" STRING;
BA_DEF_ SG_  "GenSigInactiveValue" INT -2147483648 2147483647;
BA_DEF_ SG_  "GenSigPostIfSetting" STRING;
BA_DEF_ SG_  "GenSigPostSetting" STRING;
BA_DEF_ SG_  "GenSigPreIfSetting" STRING;
BA_DEF_ SG_  "GenSigPreSetting" STRING;
BA_DEF_ SG_  "GenSigSendType" ENUM "Cyclic", "OnWrite", "OnWriteWithRepetition", "OnChange", "OnChangeWithRepetition", "IfActive", "IfActiveWithRepetition", "NoSigSendType";
BA_DEF_ SG_  "GenSigStartValue" INT -2147483648 2147483647;
BA_DEF_ SG_  "NWM-WakeupAllowed" ENUM "No", "Yes";
BA_DEF_ SG_  "GenSigTimeoutMsg_ESP8_C6" HEX 0 2047;
BA_DEF_ SG_  "GenSigTimeoutMsg_DME_EDC16CP3000" HEX 0 2047;
BA_DEF_ SG_  "GenSigTimeoutMsg_DME_ME7_MED9_C6" HEX 0 2047;
BA_DEF_ SG_  "GenSigTimeoutMsg_DME_SIMOS6_C6" HEX 0 2047;
BA_DEF_ SG_  "GenSigTimeoutMsg__6HP_C6" HEX 0 2047;
BA_DEF_ SG_  "GenSigTimeoutMsg_Gateway_C6" HEX 0 2047;
BA_DEF_ SG_  "GenSigTimeoutMsg_EPB_C6" HEX 0 2047;
BA_DEF_ SG_  "GenSigTimeoutMsg__4CL_C6" HEX 0 2047;
BA_DEF_ SG_  "GenSigTimeoutMsg_Airbag_C6" HEX 0 2047;
BA_DEF_ SG_  "GenSigTimeoutMsg_LWR_AFS_C6" HEX 0 2047;
BA_DEF_ SG_  "GenSigTimeoutMsg_LWS_C6" HEX 0 2047;
BA_DEF_ SG_  "GenSigTimeoutMsg_CVT_C6" HEX 0 2047;
BA_DEF_ SG_  "GenSigTimeoutMsg_DME_Slave" HEX 0 2047;
BA_DEF_DEF_  "GenNWMApBusSleep" "";
BA_DEF_DEF_  "GenNWMApCanNormal" "";
BA_DEF_DEF_  "GenNWMApCanOff" "";
BA_DEF_DEF_  "GenNWMApCanOn" "";
BA_DEF_DEF_  "GenNWMApCanSleep" "";
BA_DEF_DEF_  "GenNWMApCanWakeUp" "";
BA_DEF_DEF_  "GenNWMGotoMode_Awake" "";
BA_DEF_DEF_  "GenNWMGotoMode_BusSleep" "";
BA_DEF_DEF_  "GenNWMSleepTime" 0;
BA_DEF_DEF_  "GenNWMTalkNM" "";
BA_DEF_DEF_  "Manufacturer" "";
BA_DEF_DEF_  "NmBaseAddress" 0;
BA_DEF_DEF_  "NWM-BasisAdresse" 0;
BA_DEF_DEF_  "NmMessageCount" 64;
BA_DEF_DEF_  "NWMMessageCount" 64;
BA_DEF_DEF_  "NmType" "VAG-OSEK";
BA_DEF_DEF_  "NWM-Typ" "VAG-OSEK";
BA_DEF_DEF_  "VAGTP20_SetupMessageCount" 128;
BA_DEF_DEF_  "VAGTP20_SetupStartAddress" 0;
BA_DEF_DEF_  "VersionDay" 15;
BA_DEF_DEF_  "VersionMonth" 12;
BA_DEF_DEF_  "VersionNumber" 0;
BA_DEF_DEF_  "VersionWeek" 50;
BA_DEF_DEF_  "VersionYear" 5;
BA_DEF_DEF_  "GenNodAutoGenDsp" "Yes";
BA_DEF_DEF_  "GenNodAutoGenSnd" "Yes";
BA_DEF_DEF_  "GenNodSleepTime" 0;
BA_DEF_DEF_  "iLUsed" "";
BA_DEF_DEF_  "NmCAN" 1;
BA_DEF_DEF_  "NmNode" "No";
BA_DEF_DEF_  "NWM-Knoten" "No";
BA_DEF_DEF_  "NmStationAddress" 0;
BA_DEF_DEF_  "NWM-StationsAdresse" 0;
BA_DEF_DEF_  "NodeLayerModules" "VAGNM01.DLL";
BA_DEF_DEF_  "VAGTP20_TargetAddress" 0;
BA_DEF_DEF_  "GenMsgAutoGenDsp" "Yes";
BA_DEF_DEF_  "GenMsgAutoGenSnd" "Yes";
BA_DEF_DEF_  "GenMsgCycleTime" 0;
BA_DEF_DEF_  "GenMsgCycleTimeFast" 0;
BA_DEF_DEF_  "GenMsgDelayTime" 0;
BA_DEF_DEF_  "GenMsgILSupport" "";
BA_DEF_DEF_  "GenMsgSendType" "cyclicX";
BA_DEF_DEF_  "GenMsgStartDelayTime" 0;
BA_DEF_DEF_  "NmMessage" "No";
BA_DEF_DEF_  "NWM-Botschaft" "No";
BA_DEF_DEF_  "VAGTP20_API" 0;
BA_DEF_DEF_  "VAGTP20_DynConnection" "No";
BA_DEF_DEF_  "VAGTP20_DynSetup" "No";
BA_DEF_DEF_  "VAGTP20_StatConnection" "No";
BA_DEF_DEF_  "GenSigAltSetting" "";
BA_DEF_DEF_  "GenSigAssignSetting" "";
BA_DEF_DEF_  "GenSigAutoGenDsp" "";
BA_DEF_DEF_  "GenSigAutoGenSnd" "";
BA_DEF_DEF_  "GenSigConditionalSend" "";
BA_DEF_DEF_  "GenSigEnvVarType" "undef";
BA_DEF_DEF_  "GenSigEVName" "";
BA_DEF_DEF_  "GenSigInactiveValue" 0;
BA_DEF_DEF_  "GenSigPostIfSetting" "";
BA_DEF_DEF_  "GenSigPostSetting" "";
BA_DEF_DEF_  "GenSigPreIfSetting" "";
BA_DEF_DEF_  "GenSigPreSetting" "";
BA_DEF_DEF_  "GenSigSendType" "Cyclic";
BA_DEF_DEF_  "GenSigStartValue" 0;
BA_DEF_DEF_  "NWM-WakeupAllowed" "";
BA_DEF_DEF_  "GenSigTimeoutMsg_ESP8_C6" 0;
BA_DEF_DEF_  "GenSigTimeoutMsg_DME_EDC16CP3000" 0;
BA_DEF_DEF_  "GenSigTimeoutMsg_DME_ME7_MED9_C6" 0;
BA_DEF_DEF_  "GenSigTimeoutMsg_DME_SIMOS6_C6" 0;
BA_DEF_DEF_  "GenSigTimeoutMsg__6HP_C6" 0;
BA_DEF_DEF_  "GenSigTimeoutMsg_Gateway_C6" 0;
BA_DEF_DEF_  "GenSigTimeoutMsg_EPB_C6" 0;
BA_DEF_DEF_  "GenSigTimeoutMsg__4CL_C6" 0;
BA_DEF_DEF_  "GenSigTimeoutMsg_Airbag_C6" 0;
BA_DEF_DEF_  "GenSigTimeoutMsg_LWR_AFS_C6" 0;
BA_DEF_DEF_  "GenSigTimeoutMsg_LWS_C6" 0;
BA_DEF_DEF_  "GenSigTimeoutMsg_CVT_C6" 0;
BA_DEF_DEF_  "GenSigTimeoutMsg_DME_Slave" 0;
BA_  "GenNWMApBusSleep" "apBusSleep()";
BA_  "GenNWMApCanNormal" "apCanNormal()";
BA_  "GenNWMApCanOff" "apCanOff()";
BA_  "GenNWMApCanOn" "apCanOn()";
BA_  "GenNWMApCanSleep" "apCanSleep()";
BA_  "GenNWMApCanWakeUp" "apCanWakeUp()";
BA_  "GenNWMGotoMode_Awake" "gotoMode_Awake()";
BA_  "GenNWMGotoMode_BusSleep" "gotoMode_BusSleep()";
BA_  "GenNWMSleepTime" 30;
BA_  "GenNWMTalkNM" "talkNM()";
BA_  "Manufacturer" "VAG";
BA_  "NmBaseAddress" 1024;
BA_  "NWM-BasisAdresse" 1024;
BA_  "VAGTP20_SetupStartAddress" 512;
BA_ "GenNodSleepTime" BU_ _4CL_C6 30000;
BA_ "iLUsed" BU_ _4CL_C6 0;
BA_ "GenNodSleepTime" BU_ _6HP_C6 30000;
BA_ "iLUsed" BU_ _6HP_C6 0;
BA_ "VAGTP20_TargetAddress" BU_ _6HP_C6 2;
BA_ "GenNodSleepTime" BU_ Airbag_C6 30000;
BA_ "iLUsed" BU_ Airbag_C6 0;
BA_ "VAGTP20_TargetAddress" BU_ Airbag_C6 5;
BA_ "GenNodSleepTime" BU_ CVT_C6 30000;
BA_ "iLUsed" BU_ CVT_C6 0;
BA_ "GenNodSleepTime" BU_ DME_EDC16CP3000 30000;
BA_ "iLUsed" BU_ DME_EDC16CP3000 0;
BA_ "VAGTP20_TargetAddress" BU_ DME_EDC16CP3000 1;
BA_ "GenNodSleepTime" BU_ DME_ME7_MED9_C6 30000;
BA_ "iLUsed" BU_ DME_ME7_MED9_C6 0;
BA_ "VAGTP20_TargetAddress" BU_ DME_ME7_MED9_C6 1;
BA_ "GenNodSleepTime" BU_ DME_SIMOS6_C6 30000;
BA_ "iLUsed" BU_ DME_SIMOS6_C6 0;
BA_ "VAGTP20_TargetAddress" BU_ DME_SIMOS6_C6 1;
BA_ "GenNodSleepTime" BU_ DME_Slave 30000;
BA_ "iLUsed" BU_ DME_Slave 0;
BA_ "VAGTP20_TargetAddress" BU_ DME_Slave 21;
BA_ "GenNodSleepTime" BU_ EPB_C6 30000;
BA_ "iLUsed" BU_ EPB_C6 0;
BA_ "GenNodSleepTime" BU_ ESP8_C6 30000;
BA_ "iLUsed" BU_ ESP8_C6 0;
BA_ "GenNodAutoGenSnd" BU_ Gateway_C6 0;
BA_ "GenNodSleepTime" BU_ Gateway_C6 30000;
BA_ "iLUsed" BU_ Gateway_C6 0;
BA_ "NmNode" BU_ Gateway_C6 1;
BA_ "NWM-Knoten" BU_ Gateway_C6 1;
BA_ "NmStationAddress" BU_ Gateway_C6 11;
BA_ "NWM-StationsAdresse" BU_ Gateway_C6 11;
BA_ "VAGTP20_TargetAddress" BU_ Gateway_C6 31;
BA_ "GenNodSleepTime" BU_ LWR_AFS_C6 30000;
BA_ "iLUsed" BU_ LWR_AFS_C6 0;
BA_ "GenNodSleepTime" BU_ LWS_C6 30000;
BA_ "iLUsed" BU_ LWS_C6 0;
BA_ "GenMsgAutoGenSnd" BO_ 866 0;
BA_ "GenMsgCycleTime" BO_ 866 20;
BA_ "GenMsgILSupport" BO_ 866 0;
BA_ "GenMsgAutoGenSnd" BO_ 80 0;
BA_ "GenMsgCycleTime" BO_ 80 20;
BA_ "GenMsgILSupport" BO_ 80 0;
BA_ "GenMsgAutoGenSnd" BO_ 1360 0;
BA_ "GenMsgCycleTime" BO_ 1360 200;
BA_ "GenMsgILSupport" BO_ 1360 0;
BA_ "GenMsgAutoGenSnd" BO_ 882 0;
BA_ "GenMsgCycleTime" BO_ 882 50;
BA_ "GenMsgILSupport" BO_ 882 0;
BA_ "GenMsgAutoGenSnd" BO_ 416 0;
BA_ "GenMsgCycleTime" BO_ 416 20;
BA_ "GenMsgILSupport" BO_ 416 0;
BA_ "GenMsgAutoGenSnd" BO_ 1440 0;
BA_ "GenMsgCycleTime" BO_ 1440 20;
BA_ "GenMsgILSupport" BO_ 1440 0;
BA_ "GenMsgAutoGenSnd" BO_ 1184 0;
BA_ "GenMsgCycleTime" BO_ 1184 20;
BA_ "GenMsgILSupport" BO_ 1184 0;
BA_ "GenMsgAutoGenSnd" BO_ 1192 0;
BA_ "GenMsgCycleTime" BO_ 1192 20;
BA_ "GenMsgILSupport" BO_ 1192 0;
BA_ "GenMsgAutoGenSnd" BO_ 428 0;
BA_ "GenMsgCycleTime" BO_ 428 20;
BA_ "GenMsgILSupport" BO_ 428 0;
BA_ "GenMsgCycleTime" BO_ 1524 1000;
BA_ "GenMsgILSupport" BO_ 1524 0;
BA_ "GenMsgAutoGenSnd" BO_ 1518 0;
BA_ "GenMsgDelayTime" BO_ 1518 50;
BA_ "GenMsgILSupport" BO_ 1518 0;
BA_ "GenMsgSendType" BO_ 1518 7;
BA_ "GenMsgAutoGenSnd" BO_ 1516 0;
BA_ "GenMsgDelayTime" BO_ 1516 50;
BA_ "GenMsgILSupport" BO_ 1516 0;
BA_ "GenMsgSendType" BO_ 1516 7;
BA_ "GenMsgAutoGenSnd" BO_ 2000 0;
BA_ "GenMsgCycleTime" BO_ 2000 1000;
BA_ "GenMsgILSupport" BO_ 2000 0;
BA_ "GenMsgAutoGenSnd" BO_ 1472 0;
BA_ "GenMsgCycleTime" BO_ 1472 20;
BA_ "GenMsgILSupport" BO_ 1472 0;
BA_ "GenMsgAutoGenSnd" BO_ 912 0;
BA_ "GenMsgCycleTime" BO_ 912 100;
BA_ "GenMsgILSupport" BO_ 912 0;
BA_ "GenMsgAutoGenSnd" BO_ 684 0;
BA_ "GenMsgCycleTime" BO_ 684 20;
BA_ "GenMsgILSupport" BO_ 684 0;
BA_ "GenSigAutoGenDsp" SG_ 866 Anhalten 1;
BA_ "GenSigAutoGenSnd" SG_ 866 Anhalten 1;
BA_ "GenSigSendType" SG_ 866 Anhalten 7;
BA_ "NWM-WakeupAllowed" SG_ 866 Anhalten 0;
BA_ "GenSigAutoGenDsp" SG_ 866 AWV1_Freigabe 1;
BA_ "GenSigAutoGenSnd" SG_ 866 AWV1_Freigabe 1;
BA_ "GenSigSendType" SG_ 866 AWV1_Freigabe 7;
BA_ "NWM-WakeupAllowed" SG_ 866 AWV1_Freigabe 0;
BA_ "GenSigTimeoutMsg_ESP8_C6" SG_ 866 AWV1_Freigabe 866;
BA_ "GenSigAutoGenDsp" SG_ 866 AWV1_Parameter_HBA 1;
BA_ "GenSigAutoGenSnd" SG_ 866 AWV1_Parameter_HBA 1;
BA_ "GenSigSendType" SG_ 866 AWV1_Parameter_HBA 7;
BA_ "NWM-WakeupAllowed" SG_ 866 AWV1_Parameter_HBA 0;
BA_ "GenSigTimeoutMsg_ESP8_C6" SG_ 866 AWV1_Parameter_HBA 866;
BA_ "GenSigAutoGenDsp" SG_ 866 AWV1_Parameter_Nachtreten_HBA 1;
BA_ "GenSigAutoGenSnd" SG_ 866 AWV1_Parameter_Nachtreten_HBA 1;
BA_ "GenSigSendType" SG_ 866 AWV1_Parameter_Nachtreten_HBA 7;
BA_ "NWM-WakeupAllowed" SG_ 866 AWV1_Parameter_Nachtreten_HBA 0;
BA_ "GenSigAutoGenDsp" SG_ 866 AWV1_Prefill 1;
BA_ "GenSigAutoGenSnd" SG_ 866 AWV1_Prefill 1;
BA_ "GenSigSendType" SG_ 866 AWV1_Prefill 7;
BA_ "NWM-WakeupAllowed" SG_ 866 AWV1_Prefill 0;
BA_ "GenSigTimeoutMsg_ESP8_C6" SG_ 866 AWV1_Prefill 866;
BA_ "GenSigAutoGenDsp" SG_ 866 AWV2_Freigabe 1;
BA_ "GenSigAutoGenSnd" SG_ 866 AWV2_Freigabe 1;
BA_ "GenSigSendType" SG_ 866 AWV2_Freigabe 7;
BA_ "NWM-WakeupAllowed" SG_ 866 AWV2_Freigabe 0;
BA_ "GenSigAutoGenDsp" SG_ 866 AWV2_Priowarnung_LDW 1;
BA_ "GenSigAutoGenSnd" SG_ 866 AWV2_Priowarnung_LDW 1;
BA_ "GenSigSendType" SG_ 866 AWV2_Priowarnung_LDW 7;
BA_ "NWM-WakeupAllowed" SG_ 866 AWV2_Priowarnung_LDW 0;
BA_ "GenSigAutoGenDsp" SG_ 866 AWV2_Ruckprofil 1;
BA_ "GenSigAutoGenSnd" SG_ 866 AWV2_Ruckprofil 1;
BA_ "GenSigSendType" SG_ 866 AWV2_Ruckprofil 7;
BA_ "NWM-WakeupAllowed" SG_ 866 AWV2_Ruckprofil 0;
BA_ "GenSigAutoGenDsp" SG_ 866 BZ_ACC1 0;
BA_ "GenSigAutoGenSnd" SG_ 866 BZ_ACC1 0;
BA_ "GenSigSendType" SG_ 866 BZ_ACC1 7;
BA_ "NWM-WakeupAllowed" SG_ 866 BZ_ACC1 0;
BA_ "GenSigTimeoutMsg_DME_EDC16CP3000" SG_ 866 BZ_ACC1 866;
BA_ "GenSigTimeoutMsg_DME_ME7_MED9_C6" SG_ 866 BZ_ACC1 866;
BA_ "GenSigTimeoutMsg_DME_SIMOS6_C6" SG_ 866 BZ_ACC1 866;
BA_ "GenSigTimeoutMsg_ESP8_C6" SG_ 866 BZ_ACC1 866;
BA_ "GenSigAutoGenDsp" SG_ 866 CHK_ACC1 0;
BA_ "GenSigAutoGenSnd" SG_ 866 CHK_ACC1 0;
BA_ "GenSigSendType" SG_ 866 CHK_ACC1 7;
BA_ "NWM-WakeupAllowed" SG_ 866 CHK_ACC1 0;
BA_ "GenSigTimeoutMsg_DME_EDC16CP3000" SG_ 866 CHK_ACC1 866;
BA_ "GenSigTimeoutMsg_DME_ME7_MED9_C6" SG_ 866 CHK_ACC1 866;
BA_ "GenSigTimeoutMsg_DME_SIMOS6_C6" SG_ 866 CHK_ACC1 866;
BA_ "GenSigTimeoutMsg_ESP8_C6" SG_ 866 CHK_ACC1 866;
BA_ "GenSigAutoGenDsp" SG_ 866 Dynamik_Bremsdruck 0;
BA_ "GenSigAutoGenSnd" SG_ 866 Dynamik_Bremsdruck 0;
BA_ "GenSigSendType" SG_ 866 Dynamik_Bremsdruck 7;
BA_ "NWM-WakeupAllowed" SG_ 866 Dynamik_Bremsdruck 0;
BA_ "GenSigTimeoutMsg_ESP8_C6" SG_ 866 Dynamik_Bremsdruck 866;
BA_ "GenSigAutoGenDsp" SG_ 866 ESP_Beeinflussung_ACC 0;
BA_ "GenSigAutoGenSnd" SG_ 866 ESP_Beeinflussung_ACC 0;
BA_ "GenSigSendType" SG_ 866 ESP_Beeinflussung_ACC 7;
BA_ "NWM-WakeupAllowed" SG_ 866 ESP_Beeinflussung_ACC 0;
BA_ "GenSigTimeoutMsg_ESP8_C6" SG_ 866 ESP_Beeinflussung_ACC 866;
BA_ "GenSigAutoGenDsp" SG_ 866 Freigabe_Momenten_Anf 0;
BA_ "GenSigAutoGenSnd" SG_ 866 Freigabe_Momenten_Anf 0;
BA_ "GenSigSendType" SG_ 866 Freigabe_Momenten_Anf 7;
BA_ "NWM-WakeupAllowed" SG_ 866 Freigabe_Momenten_Anf 0;
BA_ "GenSigTimeoutMsg_DME_EDC16CP3000" SG_ 866 Freigabe_Momenten_Anf 866;
BA_ "GenSigTimeoutMsg_DME_ME7_MED9_C6" SG_ 866 Freigabe_Momenten_Anf 866;
BA_ "GenSigTimeoutMsg_DME_SIMOS6_C6" SG_ 866 Freigabe_Momenten_Anf 866;
BA_ "GenSigAutoGenDsp" SG_ 866 Freigabe_Verzoeg_Anf 0;
BA_ "GenSigAutoGenSnd" SG_ 866 Freigabe_Verzoeg_Anf 0;
BA_ "GenSigSendType" SG_ 866 Freigabe_Verzoeg_Anf 7;
BA_ "NWM-WakeupAllowed" SG_ 866 Freigabe_Verzoeg_Anf 0;
BA_ "GenSigTimeoutMsg__6HP_C6" SG_ 866 Freigabe_Verzoeg_Anf 866;
BA_ "GenSigTimeoutMsg_DME_EDC16CP3000" SG_ 866 Freigabe_Verzoeg_Anf 866;
BA_ "GenSigTimeoutMsg_DME_ME7_MED9_C6" SG_ 866 Freigabe_Verzoeg_Anf 866;
BA_ "GenSigTimeoutMsg_ESP8_C6" SG_ 866 Freigabe_Verzoeg_Anf 866;
BA_ "GenSigAutoGenDsp" SG_ 866 FSPE_ACC 0;
BA_ "GenSigAutoGenSnd" SG_ 866 FSPE_ACC 0;
BA_ "GenSigSendType" SG_ 866 FSPE_ACC 7;
BA_ "NWM-WakeupAllowed" SG_ 866 FSPE_ACC 0;
BA_ "GenSigAutoGenDsp" SG_ 866 Momenten_Anf_ACC 0;
BA_ "GenSigAutoGenSnd" SG_ 866 Momenten_Anf_ACC 0;
BA_ "GenSigSendType" SG_ 866 Momenten_Anf_ACC 7;
BA_ "NWM-WakeupAllowed" SG_ 866 Momenten_Anf_ACC 0;
BA_ "GenSigTimeoutMsg_DME_EDC16CP3000" SG_ 866 Momenten_Anf_ACC 866;
BA_ "GenSigTimeoutMsg_DME_ME7_MED9_C6" SG_ 866 Momenten_Anf_ACC 866;
BA_ "GenSigTimeoutMsg_DME_SIMOS6_C6" SG_ 866 Momenten_Anf_ACC 866;
BA_ "GenSigAutoGenDsp" SG_ 866 Sender_Info 0;
BA_ "GenSigAutoGenSnd" SG_ 866 Sender_Info 0;
BA_ "GenSigSendType" SG_ 866 Sender_Info 7;
BA_ "NWM-WakeupAllowed" SG_ 866 Sender_Info 0;
BA_ "GenSigTimeoutMsg__6HP_C6" SG_ 866 Sender_Info 866;
BA_ "GenSigAutoGenDsp" SG_ 866 Sollbeschl_Getr 0;
BA_ "GenSigAutoGenSnd" SG_ 866 Sollbeschl_Getr 0;
BA_ "GenSigSendType" SG_ 866 Sollbeschl_Getr 7;
BA_ "GenSigStartValue" SG_ 866 Sollbeschl_Getr 166;
BA_ "NWM-WakeupAllowed" SG_ 866 Sollbeschl_Getr 0;
BA_ "GenSigAutoGenDsp" SG_ 866 Status_ACC 0;
BA_ "GenSigAutoGenSnd" SG_ 866 Status_ACC 0;
BA_ "GenSigSendType" SG_ 866 Status_ACC 7;
BA_ "NWM-WakeupAllowed" SG_ 866 Status_ACC 0;
BA_ "GenSigTimeoutMsg_DME_EDC16CP3000" SG_ 866 Status_ACC 866;
BA_ "GenSigTimeoutMsg_DME_ME7_MED9_C6" SG_ 866 Status_ACC 866;
BA_ "GenSigTimeoutMsg_DME_SIMOS6_C6" SG_ 866 Status_ACC 866;
BA_ "GenSigTimeoutMsg_ESP8_C6" SG_ 866 Status_ACC 866;
BA_ "GenSigAutoGenDsp" SG_ 866 Verhinderung_SA 0;
BA_ "GenSigAutoGenSnd" SG_ 866 Verhinderung_SA 0;
BA_ "GenSigSendType" SG_ 866 Verhinderung_SA 7;
BA_ "NWM-WakeupAllowed" SG_ 866 Verhinderung_SA 0;
BA_ "GenSigTimeoutMsg_DME_SIMOS6_C6" SG_ 866 Verhinderung_SA 866;
BA_ "GenSigAutoGenDsp" SG_ 866 Verzoeg_Anf_ACC 0;
BA_ "GenSigAutoGenSnd" SG_ 866 Verzoeg_Anf_ACC 0;
BA_ "GenSigSendType" SG_ 866 Verzoeg_Anf_ACC 7;
BA_ "GenSigStartValue" SG_ 866 Verzoeg_Anf_ACC 166;
BA_ "NWM-WakeupAllowed" SG_ 866 Verzoeg_Anf_ACC 0;
BA_ "GenSigTimeoutMsg_DME_EDC16CP3000" SG_ 866 Verzoeg_Anf_ACC 866;
BA_ "GenSigTimeoutMsg_DME_ME7_MED9_C6" SG_ 866 Verzoeg_Anf_ACC 866;
BA_ "GenSigTimeoutMsg_ESP8_C6" SG_ 866 Verzoeg_Anf_ACC 866;
BA_ "GenSigAutoGenDsp" SG_ 866 Vorbefuellung_Bremsanlage 0;
BA_ "GenSigAutoGenSnd" SG_ 866 Vorbefuellung_Bremsanlage 0;
BA_ "GenSigSendType" SG_ 866 Vorbefuellung_Bremsanlage 7;
BA_ "NWM-WakeupAllowed" SG_ 866 Vorbefuellung_Bremsanlage 0;
BA_ "GenSigTimeoutMsg_ESP8_C6" SG_ 866 Vorbefuellung_Bremsanlage 866;
BA_ "GenSigAutoGenDsp" SG_ 80 Airbag_deaktiviert 0;
BA_ "GenSigAutoGenSnd" SG_ 80 Airbag_deaktiviert 0;
BA_ "GenSigSendType" SG_ 80 Airbag_deaktiviert 7;
BA_ "NWM-WakeupAllowed" SG_ 80 Airbag_deaktiviert 0;
BA_ "GenSigTimeoutMsg_Gateway_C6" SG_ 80 Airbag_deaktiviert 80;
BA_ "GenSigAutoGenDsp" SG_ 80 Airbag_im_Stellgliedtest 0;
BA_ "GenSigAutoGenSnd" SG_ 80 Airbag_im_Stellgliedtest 0;
BA_ "GenSigSendType" SG_ 80 Airbag_im_Stellgliedtest 7;
BA_ "NWM-WakeupAllowed" SG_ 80 Airbag_im_Stellgliedtest 0;
BA_ "GenSigTimeoutMsg_DME_EDC16CP3000" SG_ 80 Airbag_im_Stellgliedtest 80;
BA_ "GenSigTimeoutMsg_Gateway_C6" SG_ 80 Airbag_im_Stellgliedtest 80;
BA_ "GenSigAutoGenDsp" SG_ 80 Airbag_in_Diagnose 0;
BA_ "GenSigAutoGenSnd" SG_ 80 Airbag_in_Diagnose 0;
BA_ "GenSigSendType" SG_ 80 Airbag_in_Diagnose 7;
BA_ "NWM-WakeupAllowed" SG_ 80 Airbag_in_Diagnose 0;
BA_ "GenSigTimeoutMsg_Gateway_C6" SG_ 80 Airbag_in_Diagnose 80;
BA_ "GenSigAutoGenDsp" SG_ 80 Airbag_Lampe 0;
BA_ "GenSigAutoGenSnd" SG_ 80 Airbag_Lampe 0;
BA_ "GenSigSendType" SG_ 80 Airbag_Lampe 7;
BA_ "GenSigStartValue" SG_ 80 Airbag_Lampe 1;
BA_ "NWM-WakeupAllowed" SG_ 80 Airbag_Lampe 0;
BA_ "GenSigTimeoutMsg_Gateway_C6" SG_ 80 Airbag_Lampe 80;
BA_ "GenSigAutoGenDsp" SG_ 80 Airbag_Systemfehler 0;
BA_ "GenSigAutoGenSnd" SG_ 80 Airbag_Systemfehler 0;
BA_ "GenSigSendType" SG_ 80 Airbag_Systemfehler 7;
BA_ "NWM-WakeupAllowed" SG_ 80 Airbag_Systemfehler 0;
BA_ "GenSigTimeoutMsg_ESP8_C6" SG_ 80 Airbag_Systemfehler 80;
BA_ "GenSigTimeoutMsg_Gateway_C6" SG_ 80 Airbag_Systemfehler 80;
BA_ "GenSigAutoGenDsp" SG_ 80 Beifahrerairbag_deaktiviert 0;
BA_ "GenSigAutoGenSnd" SG_ 80 Beifahrerairbag_deaktiviert 0;
BA_ "GenSigSendType" SG_ 80 Beifahrerairbag_deaktiviert 7;
BA_ "GenSigStartValue" SG_ 80 Beifahrerairbag_deaktiviert 1;
BA_ "NWM-WakeupAllowed" SG_ 80 Beifahrerairbag_deaktiviert 0;
BA_ "GenSigTimeoutMsg_Gateway_C6" SG_ 80 Beifahrerairbag_deaktiviert 80;
BA_ "GenSigAutoGenDsp" SG_ 80 BZ_Airbag1 0;
BA_ "GenSigAutoGenSnd" SG_ 80 BZ_Airbag1 0;
BA_ "GenSigSendType" SG_ 80 BZ_Airbag1 7;
BA_ "NWM-WakeupAllowed" SG_ 80 BZ_Airbag1 0;
BA_ "GenSigTimeoutMsg_DME_EDC16CP3000" SG_ 80 BZ_Airbag1 80;
BA_ "GenSigTimeoutMsg_DME_ME7_MED9_C6" SG_ 80 BZ_Airbag1 80;
BA_ "GenSigTimeoutMsg_DME_SIMOS6_C6" SG_ 80 BZ_Airbag1 80;
BA_ "GenSigTimeoutMsg_EPB_C6" SG_ 80 BZ_Airbag1 80;
BA_ "GenSigTimeoutMsg_ESP8_C6" SG_ 80 BZ_Airbag1 80;
BA_ "GenSigTimeoutMsg_Gateway_C6" SG_ 80 BZ_Airbag1 80;
BA_ "GenSigAutoGenDsp" SG_ 80 CHK_Airbag1 0;
BA_ "GenSigAutoGenSnd" SG_ 80 CHK_Airbag1 0;
BA_ "GenSigSendType" SG_ 80 CHK_Airbag1 7;
BA_ "NWM-WakeupAllowed" SG_ 80 CHK_Airbag1 0;
BA_ "GenSigTimeoutMsg_DME_EDC16CP3000" SG_ 80 CHK_Airbag1 80;
BA_ "GenSigTimeoutMsg_DME_ME7_MED9_C6" SG_ 80 CHK_Airbag1 80;
BA_ "GenSigTimeoutMsg_DME_SIMOS6_C6" SG_ 80 CHK_Airbag1 80;
BA_ "GenSigTimeoutMsg_EPB_C6" SG_ 80 CHK_Airbag1 80;
BA_ "GenSigTimeoutMsg_ESP8_C6" SG_ 80 CHK_Airbag1 80;
BA_ "GenSigTimeoutMsg_Gateway_C6" SG_ 80 CHK_Airbag1 80;
BA_ "GenSigAutoGenDsp" SG_ 80 Crash_Intensitaet 0;
BA_ "GenSigAutoGenSnd" SG_ 80 Crash_Intensitaet 0;
BA_ "GenSigSendType" SG_ 80 Crash_Intensitaet 7;
BA_ "NWM-WakeupAllowed" SG_ 80 Crash_Intensitaet 0;
BA_ "GenSigTimeoutMsg_DME_EDC16CP3000" SG_ 80 Crash_Intensitaet 80;
BA_ "GenSigTimeoutMsg_DME_ME7_MED9_C6" SG_ 80 Crash_Intensitaet 80;
BA_ "GenSigTimeoutMsg_DME_SIMOS6_C6" SG_ 80 Crash_Intensitaet 80;
BA_ "GenSigTimeoutMsg_Gateway_C6" SG_ 80 Crash_Intensitaet 80;
BA_ "GenSigAutoGenDsp" SG_ 80 Front_Crash 0;
BA_ "GenSigAutoGenSnd" SG_ 80 Front_Crash 0;
BA_ "GenSigSendType" SG_ 80 Front_Crash 7;
BA_ "NWM-WakeupAllowed" SG_ 80 Front_Crash 0;
BA_ "GenSigTimeoutMsg_ESP8_C6" SG_ 80 Front_Crash 80;
BA_ "GenSigTimeoutMsg_Gateway_C6" SG_ 80 Front_Crash 80;
BA_ "GenSigAutoGenDsp" SG_ 80 FSPE_Airbag 0;
BA_ "GenSigAutoGenSnd" SG_ 80 FSPE_Airbag 0;
BA_ "GenSigSendType" SG_ 80 FSPE_Airbag 7;
BA_ "NWM-WakeupAllowed" SG_ 80 FSPE_Airbag 0;
BA_ "GenSigTimeoutMsg_Gateway_C6" SG_ 80 FSPE_Airbag 80;
BA_ "GenSigAutoGenDsp" SG_ 80 Gurtschlossabfrage_Beifahrer 0;
BA_ "GenSigAutoGenSnd" SG_ 80 Gurtschlossabfrage_Beifahrer 0;
BA_ "GenSigSendType" SG_ 80 Gurtschlossabfrage_Beifahrer 7;
BA_ "NWM-WakeupAllowed" SG_ 80 Gurtschlossabfrage_Beifahrer 0;
BA_ "GenSigTimeoutMsg_ESP8_C6" SG_ 80 Gurtschlossabfrage_Beifahrer 80;
BA_ "GenSigTimeoutMsg_Gateway_C6" SG_ 80 Gurtschlossabfrage_Beifahrer 80;
BA_ "GenSigAutoGenDsp" SG_ 80 Gurtschlossabfrage_Fahrer 0;
BA_ "GenSigAutoGenSnd" SG_ 80 Gurtschlossabfrage_Fahrer 0;
BA_ "GenSigSendType" SG_ 80 Gurtschlossabfrage_Fahrer 7;
BA_ "NWM-WakeupAllowed" SG_ 80 Gurtschlossabfrage_Fahrer 0;
BA_ "GenSigTimeoutMsg_EPB_C6" SG_ 80 Gurtschlossabfrage_Fahrer 80;
BA_ "GenSigTimeoutMsg_ESP8_C6" SG_ 80 Gurtschlossabfrage_Fahrer 80;
BA_ "GenSigTimeoutMsg_Gateway_C6" SG_ 80 Gurtschlossabfrage_Fahrer 80;
BA_ "GenSigAutoGenDsp" SG_ 80 Gurtwarnung_Beifahrer 1;
BA_ "GenSigAutoGenSnd" SG_ 80 Gurtwarnung_Beifahrer 1;
BA_ "GenSigSendType" SG_ 80 Gurtwarnung_Beifahrer 7;
BA_ "NWM-WakeupAllowed" SG_ 80 Gurtwarnung_Beifahrer 0;
BA_ "GenSigTimeoutMsg_Gateway_C6" SG_ 80 Gurtwarnung_Beifahrer 80;
BA_ "GenSigAutoGenDsp" SG_ 80 Heck_Crash 0;
BA_ "GenSigAutoGenSnd" SG_ 80 Heck_Crash 0;
BA_ "GenSigSendType" SG_ 80 Heck_Crash 7;
BA_ "NWM-WakeupAllowed" SG_ 80 Heck_Crash 0;
BA_ "GenSigTimeoutMsg_ESP8_C6" SG_ 80 Heck_Crash 80;
BA_ "GenSigTimeoutMsg_Gateway_C6" SG_ 80 Heck_Crash 80;
BA_ "GenSigAutoGenDsp" SG_ 80 Rollover 0;
BA_ "GenSigAutoGenSnd" SG_ 80 Rollover 0;
BA_ "GenSigSendType" SG_ 80 Rollover 7;
BA_ "NWM-WakeupAllowed" SG_ 80 Rollover 0;
BA_ "GenSigTimeoutMsg_ESP8_C6" SG_ 80 Rollover 80;
BA_ "GenSigTimeoutMsg_Gateway_C6" SG_ 80 Rollover 80;
BA_ "GenSigAutoGenDsp" SG_ 80 Seiten_Crash_Beifahrer 0;
BA_ "GenSigAutoGenSnd" SG_ 80 Seiten_Crash_Beifahrer 0;
BA_ "GenSigSendType" SG_ 80 Seiten_Crash_Beifahrer 7;
BA_ "NWM-WakeupAllowed" SG_ 80 Seiten_Crash_Beifahrer 0;
BA_ "GenSigTimeoutMsg_ESP8_C6" SG_ 80 Seiten_Crash_Beifahrer 80;
BA_ "GenSigTimeoutMsg_Gateway_C6" SG_ 80 Seiten_Crash_Beifahrer 80;
BA_ "GenSigAutoGenDsp" SG_ 80 Seiten_Crash_Fahrer 0;
BA_ "GenSigAutoGenSnd" SG_ 80 Seiten_Crash_Fahrer 0;
BA_ "GenSigSendType" SG_ 80 Seiten_Crash_Fahrer 7;
BA_ "NWM-WakeupAllowed" SG_ 80 Seiten_Crash_Fahrer 0;
BA_ "GenSigTimeoutMsg_ESP8_C6" SG_ 80 Seiten_Crash_Fahrer 80;
BA_ "GenSigTimeoutMsg_Gateway_C6" SG_ 80 Seiten_Crash_Fahrer 80;
BA_ "GenSigAutoGenDsp" SG_ 1360 Belegerkenn_Beifahrersitz 0;
BA_ "GenSigAutoGenSnd" SG_ 1360 Belegerkenn_Beifahrersitz 0;
BA_ "GenSigSendType" SG_ 1360 Belegerkenn_Beifahrersitz 7;
BA_ "NWM-WakeupAllowed" SG_ 1360 Belegerkenn_Beifahrersitz 0;
BA_ "GenSigTimeoutMsg_Gateway_C6" SG_ 1360 Belegerkenn_Beifahrersitz 1360;
BA_ "GenSigAutoGenDsp" SG_ 1360 Belegerkenn_hinten_Beifahrer 0;
BA_ "GenSigAutoGenSnd" SG_ 1360 Belegerkenn_hinten_Beifahrer 0;
BA_ "GenSigSendType" SG_ 1360 Belegerkenn_hinten_Beifahrer 7;
BA_ "NWM-WakeupAllowed" SG_ 1360 Belegerkenn_hinten_Beifahrer 0;
BA_ "GenSigTimeoutMsg_Gateway_C6" SG_ 1360 Belegerkenn_hinten_Beifahrer 1360;
BA_ "GenSigAutoGenDsp" SG_ 1360 Belegerkenn_hinten_Fahrer 0;
BA_ "GenSigAutoGenSnd" SG_ 1360 Belegerkenn_hinten_Fahrer 0;
BA_ "GenSigSendType" SG_ 1360 Belegerkenn_hinten_Fahrer 7;
BA_ "NWM-WakeupAllowed" SG_ 1360 Belegerkenn_hinten_Fahrer 0;
BA_ "GenSigTimeoutMsg_Gateway_C6" SG_ 1360 Belegerkenn_hinten_Fahrer 1360;
BA_ "GenSigAutoGenDsp" SG_ 1360 Belegerkenn_hinten_Mitte 0;
BA_ "GenSigAutoGenSnd" SG_ 1360 Belegerkenn_hinten_Mitte 0;
BA_ "GenSigSendType" SG_ 1360 Belegerkenn_hinten_Mitte 7;
BA_ "NWM-WakeupAllowed" SG_ 1360 Belegerkenn_hinten_Mitte 0;
BA_ "GenSigTimeoutMsg_Gateway_C6" SG_ 1360 Belegerkenn_hinten_Mitte 1360;
BA_ "GenSigAutoGenDsp" SG_ 1360 CHK_Airbag2 0;
BA_ "GenSigAutoGenSnd" SG_ 1360 CHK_Airbag2 0;
BA_ "GenSigSendType" SG_ 1360 CHK_Airbag2 7;
BA_ "NWM-WakeupAllowed" SG_ 1360 CHK_Airbag2 0;
BA_ "GenSigTimeoutMsg_Gateway_C6" SG_ 1360 CHK_Airbag2 1360;
BA_ "GenSigAutoGenDsp" SG_ 1360 Erhoehung_Aufmerk_BFS 1;
BA_ "GenSigAutoGenSnd" SG_ 1360 Erhoehung_Aufmerk_BFS 1;
BA_ "GenSigSendType" SG_ 1360 Erhoehung_Aufmerk_BFS 7;
BA_ "NWM-WakeupAllowed" SG_ 1360 Erhoehung_Aufmerk_BFS 0;
BA_ "GenSigTimeoutMsg_Gateway_C6" SG_ 1360 Erhoehung_Aufmerk_BFS 1360;
BA_ "GenSigAutoGenDsp" SG_ 1360 OOP_Beifahrer 0;
BA_ "GenSigAutoGenSnd" SG_ 1360 OOP_Beifahrer 0;
BA_ "GenSigSendType" SG_ 1360 OOP_Beifahrer 7;
BA_ "NWM-WakeupAllowed" SG_ 1360 OOP_Beifahrer 0;
BA_ "GenSigTimeoutMsg_Gateway_C6" SG_ 1360 OOP_Beifahrer 1360;
BA_ "GenSigAutoGenDsp" SG_ 1360 OOP_Fahrer 0;
BA_ "GenSigAutoGenSnd" SG_ 1360 OOP_Fahrer 0;
BA_ "GenSigSendType" SG_ 1360 OOP_Fahrer 7;
BA_ "NWM-WakeupAllowed" SG_ 1360 OOP_Fahrer 0;
BA_ "GenSigTimeoutMsg_Gateway_C6" SG_ 1360 OOP_Fahrer 1360;
BA_ "GenSigAutoGenDsp" SG_ 882 Abschalt_Heizsysteme 0;
BA_ "GenSigAutoGenSnd" SG_ 882 Abschalt_Heizsysteme 0;
BA_ "GenSigSendType" SG_ 882 Abschalt_Heizsysteme 7;
BA_ "NWM-WakeupAllowed" SG_ 882 Abschalt_Heizsysteme 0;
BA_ "GenSigAutoGenDsp" SG_ 882 Abschaltstufen 0;
BA_ "GenSigAutoGenSnd" SG_ 882 Abschaltstufen 0;
BA_ "GenSigSendType" SG_ 882 Abschaltstufen 7;
BA_ "NWM-WakeupAllowed" SG_ 882 Abschaltstufen 0;
BA_ "GenSigTimeoutMsg__4CL_C6" SG_ 882 Abschaltstufen 882;
BA_ "GenSigTimeoutMsg_DME_SIMOS6_C6" SG_ 882 Abschaltstufen 882;
BA_ "GenSigAutoGenDsp" SG_ 882 Anforderung_HSH 0;
BA_ "GenSigAutoGenSnd" SG_ 882 Anforderung_HSH 0;
BA_ "GenSigSendType" SG_ 882 Anforderung_HSH 7;
BA_ "NWM-WakeupAllowed" SG_ 882 Anforderung_HSH 0;
BA_ "GenSigAutoGenDsp" SG_ 882 Anforderung_Kluefter_ 1;
BA_ "GenSigAutoGenSnd" SG_ 882 Anforderung_Kluefter_ 1;
BA_ "GenSigSendType" SG_ 882 Anforderung_Kluefter_ 7;
BA_ "NWM-WakeupAllowed" SG_ 882 Anforderung_Kluefter_ 0;
BA_ "GenSigAutoGenDsp" SG_ 882 BEM_Batteriespannung 0;
BA_ "GenSigAutoGenSnd" SG_ 882 BEM_Batteriespannung 0;
BA_ "GenSigSendType" SG_ 882 BEM_Batteriespannung 7;
BA_ "NWM-WakeupAllowed" SG_ 882 BEM_Batteriespannung 0;
BA_ "GenSigAutoGenDsp" SG_ 882 BZ_BEM1 0;
BA_ "GenSigAutoGenSnd" SG_ 882 BZ_BEM1 0;
BA_ "GenSigSendType" SG_ 882 BZ_BEM1 7;
BA_ "NWM-WakeupAllowed" SG_ 882 BZ_BEM1 0;
BA_ "GenSigTimeoutMsg_DME_EDC16CP3000" SG_ 882 BZ_BEM1 882;
BA_ "GenSigTimeoutMsg_DME_SIMOS6_C6" SG_ 882 BZ_BEM1 882;
BA_ "GenSigAutoGenDsp" SG_ 882 CHK_BEM1 0;
BA_ "GenSigAutoGenSnd" SG_ 882 CHK_BEM1 0;
BA_ "GenSigSendType" SG_ 882 CHK_BEM1 7;
BA_ "NWM-WakeupAllowed" SG_ 882 CHK_BEM1 0;
BA_ "GenSigTimeoutMsg__4CL_C6" SG_ 882 CHK_BEM1 882;
BA_ "GenSigTimeoutMsg_DME_EDC16CP3000" SG_ 882 CHK_BEM1 882;
BA_ "GenSigTimeoutMsg_DME_SIMOS6_C6" SG_ 882 CHK_BEM1 882;
BA_ "GenSigAutoGenDsp" SG_ 882 Einschaltung_PTC_Hzg 0;
BA_ "GenSigAutoGenSnd" SG_ 882 Einschaltung_PTC_Hzg 0;
BA_ "GenSigSendType" SG_ 882 Einschaltung_PTC_Hzg 7;
BA_ "NWM-WakeupAllowed" SG_ 882 Einschaltung_PTC_Hzg 0;
BA_ "GenSigTimeoutMsg_DME_EDC16CP3000" SG_ 882 Einschaltung_PTC_Hzg 882;
BA_ "GenSigTimeoutMsg_DME_SIMOS6_C6" SG_ 882 Einschaltung_PTC_Hzg 882;
BA_ "GenSigAutoGenDsp" SG_ 882 Generator_Lastmoment 0;
BA_ "GenSigAutoGenSnd" SG_ 882 Generator_Lastmoment 0;
BA_ "GenSigSendType" SG_ 882 Generator_Lastmoment 7;
BA_ "NWM-WakeupAllowed" SG_ 882 Generator_Lastmoment 0;
BA_ "GenSigTimeoutMsg_DME_ME7_MED9_C6" SG_ 882 Generator_Lastmoment 882;
BA_ "GenSigTimeoutMsg_DME_SIMOS6_C6" SG_ 882 Generator_Lastmoment 882;
BA_ "GenSigAutoGenDsp" SG_ 882 Generator_Leistungsaufnahme 0;
BA_ "GenSigAutoGenSnd" SG_ 882 Generator_Leistungsaufnahme 0;
BA_ "GenSigSendType" SG_ 882 Generator_Leistungsaufnahme 7;
BA_ "NWM-WakeupAllowed" SG_ 882 Generator_Leistungsaufnahme 0;
BA_ "GenSigTimeoutMsg_DME_SIMOS6_C6" SG_ 882 Generator_Leistungsaufnahme 882;
BA_ "GenSigAutoGenDsp" SG_ 882 HL_Systeme_Status 0;
BA_ "GenSigAutoGenSnd" SG_ 882 HL_Systeme_Status 0;
BA_ "GenSigSendType" SG_ 882 HL_Systeme_Status 7;
BA_ "NWM-WakeupAllowed" SG_ 882 HL_Systeme_Status 0;
BA_ "GenSigAutoGenDsp" SG_ 882 HL_Systemregelung_Status 0;
BA_ "GenSigAutoGenSnd" SG_ 882 HL_Systemregelung_Status 0;
BA_ "GenSigSendType" SG_ 882 HL_Systemregelung_Status 7;
BA_ "NWM-WakeupAllowed" SG_ 882 HL_Systemregelung_Status 0;
BA_ "GenSigAutoGenDsp" SG_ 882 Lastabwurf_Rueckmeldung 0;
BA_ "GenSigAutoGenSnd" SG_ 882 Lastabwurf_Rueckmeldung 0;
BA_ "GenSigSendType" SG_ 882 Lastabwurf_Rueckmeldung 7;
BA_ "NWM-WakeupAllowed" SG_ 882 Lastabwurf_Rueckmeldung 0;
BA_ "GenSigTimeoutMsg_DME_SIMOS6_C6" SG_ 882 Lastabwurf_Rueckmeldung 882;
BA_ "GenSigAutoGenDsp" SG_ 882 Leerlaufdrehzahl_Erhoehung 0;
BA_ "GenSigAutoGenSnd" SG_ 882 Leerlaufdrehzahl_Erhoehung 0;
BA_ "GenSigSendType" SG_ 882 Leerlaufdrehzahl_Erhoehung 7;
BA_ "NWM-WakeupAllowed" SG_ 882 Leerlaufdrehzahl_Erhoehung 0;
BA_ "GenSigTimeoutMsg_DME_EDC16CP3000" SG_ 882 Leerlaufdrehzahl_Erhoehung 882;
BA_ "GenSigTimeoutMsg_DME_SIMOS6_C6" SG_ 882 Leerlaufdrehzahl_Erhoehung 882;
BA_ "GenSigAutoGenDsp" SG_ 882 Load_Response_Generator 0;
BA_ "GenSigAutoGenSnd" SG_ 882 Load_Response_Generator 0;
BA_ "GenSigSendType" SG_ 882 Load_Response_Generator 7;
BA_ "NWM-WakeupAllowed" SG_ 882 Load_Response_Generator 0;
BA_ "GenSigTimeoutMsg_DME_SIMOS6_C6" SG_ 882 Load_Response_Generator 882;
BA_ "GenSigAutoGenDsp" SG_ 882 Red_Innenraumgeblaese 1;
BA_ "GenSigAutoGenSnd" SG_ 882 Red_Innenraumgeblaese 1;
BA_ "GenSigSendType" SG_ 882 Red_Innenraumgeblaese 7;
BA_ "NWM-WakeupAllowed" SG_ 882 Red_Innenraumgeblaese 0;
BA_ "GenSigAutoGenDsp" SG_ 882 Ruecknahme_HSH 0;
BA_ "GenSigAutoGenSnd" SG_ 882 Ruecknahme_HSH 0;
BA_ "GenSigSendType" SG_ 882 Ruecknahme_HSH 7;
BA_ "NWM-WakeupAllowed" SG_ 882 Ruecknahme_HSH 0;
BA_ "GenSigAutoGenDsp" SG_ 416 ABS_Bremsung 0;
BA_ "GenSigAutoGenSnd" SG_ 416 ABS_Bremsung 0;
BA_ "GenSigSendType" SG_ 416 ABS_Bremsung 7;
BA_ "NWM-WakeupAllowed" SG_ 416 ABS_Bremsung 0;
BA_ "GenSigTimeoutMsg__4CL_C6" SG_ 416 ABS_Bremsung 416;
BA_ "GenSigTimeoutMsg__6HP_C6" SG_ 416 ABS_Bremsung 416;
BA_ "GenSigTimeoutMsg_Airbag_C6" SG_ 416 ABS_Bremsung 416;
BA_ "GenSigTimeoutMsg_DME_EDC16CP3000" SG_ 416 ABS_Bremsung 416;
BA_ "GenSigTimeoutMsg_DME_ME7_MED9_C6" SG_ 416 ABS_Bremsung 416;
BA_ "GenSigTimeoutMsg_DME_SIMOS6_C6" SG_ 416 ABS_Bremsung 416;
BA_ "GenSigTimeoutMsg_EPB_C6" SG_ 416 ABS_Bremsung 416;
BA_ "GenSigTimeoutMsg_Gateway_C6" SG_ 416 ABS_Bremsung 416;
BA_ "GenSigAutoGenDsp" SG_ 416 ABS_in_Diagnose 0;
BA_ "GenSigAutoGenSnd" SG_ 416 ABS_in_Diagnose 0;
BA_ "GenSigSendType" SG_ 416 ABS_in_Diagnose 7;
BA_ "NWM-WakeupAllowed" SG_ 416 ABS_in_Diagnose 0;
BA_ "GenSigTimeoutMsg_DME_ME7_MED9_C6" SG_ 416 ABS_in_Diagnose 416;
BA_ "GenSigTimeoutMsg_Gateway_C6" SG_ 416 ABS_in_Diagnose 416;
BA_ "GenSigAutoGenDsp" SG_ 416 Aktiver_BKV 0;
BA_ "GenSigAutoGenSnd" SG_ 416 Aktiver_BKV 0;
BA_ "GenSigSendType" SG_ 416 Aktiver_BKV 7;
BA_ "NWM-WakeupAllowed" SG_ 416 Aktiver_BKV 0;
BA_ "GenSigTimeoutMsg_DME_ME7_MED9_C6" SG_ 416 Aktiver_BKV 416;
BA_ "GenSigTimeoutMsg_DME_SIMOS6_C6" SG_ 416 Aktiver_BKV 416;
BA_ "GenSigTimeoutMsg_Gateway_C6" SG_ 416 Aktiver_BKV 416;
BA_ "GenSigAutoGenDsp" SG_ 416 ASR_Anforderung 0;
BA_ "GenSigAutoGenSnd" SG_ 416 ASR_Anforderung 0;
BA_ "GenSigSendType" SG_ 416 ASR_Anforderung 7;
BA_ "NWM-WakeupAllowed" SG_ 416 ASR_Anforderung 0;
BA_ "GenSigTimeoutMsg__4CL_C6" SG_ 416 ASR_Anforderung 416;
BA_ "GenSigTimeoutMsg__6HP_C6" SG_ 416 ASR_Anforderung 416;
BA_ "GenSigTimeoutMsg_Airbag_C6" SG_ 416 ASR_Anforderung 416;
BA_ "GenSigTimeoutMsg_DME_EDC16CP3000" SG_ 416 ASR_Anforderung 416;
BA_ "GenSigTimeoutMsg_DME_ME7_MED9_C6" SG_ 416 ASR_Anforderung 416;
BA_ "GenSigTimeoutMsg_DME_SIMOS6_C6" SG_ 416 ASR_Anforderung 416;
BA_ "GenSigTimeoutMsg_EPB_C6" SG_ 416 ASR_Anforderung 416;
BA_ "GenSigTimeoutMsg_Gateway_C6" SG_ 416 ASR_Anforderung 416;
BA_ "GenSigAutoGenDsp" SG_ 416 ASR_Eingriffmom_langsam 0;
BA_ "GenSigAutoGenSnd" SG_ 416 ASR_Eingriffmom_langsam 0;
BA_ "GenSigSendType" SG_ 416 ASR_Eingriffmom_langsam 7;
BA_ "GenSigStartValue" SG_ 416 ASR_Eingriffmom_langsam 254;
BA_ "NWM-WakeupAllowed" SG_ 416 ASR_Eingriffmom_langsam 0;
BA_ "GenSigTimeoutMsg__6HP_C6" SG_ 416 ASR_Eingriffmom_langsam 416;
BA_ "GenSigTimeoutMsg_DME_ME7_MED9_C6" SG_ 416 ASR_Eingriffmom_langsam 416;
BA_ "GenSigTimeoutMsg_DME_SIMOS6_C6" SG_ 416 ASR_Eingriffmom_langsam 416;
BA_ "GenSigTimeoutMsg_Gateway_C6" SG_ 416 ASR_Eingriffmom_langsam 416;
BA_ "GenSigAutoGenDsp" SG_ 416 ASR_Eingriffmom_schnell 0;
BA_ "GenSigAutoGenSnd" SG_ 416 ASR_Eingriffmom_schnell 0;
BA_ "GenSigSendType" SG_ 416 ASR_Eingriffmom_schnell 7;
BA_ "GenSigStartValue" SG_ 416 ASR_Eingriffmom_schnell 254;
BA_ "NWM-WakeupAllowed" SG_ 416 ASR_Eingriffmom_schnell 0;
BA_ "GenSigTimeoutMsg__6HP_C6" SG_ 416 ASR_Eingriffmom_schnell 416;
BA_ "GenSigTimeoutMsg_DME_EDC16CP3000" SG_ 416 ASR_Eingriffmom_schnell 416;
BA_ "GenSigTimeoutMsg_DME_ME7_MED9_C6" SG_ 416 ASR_Eingriffmom_schnell 416;
BA_ "GenSigTimeoutMsg_DME_SIMOS6_C6" SG_ 416 ASR_Eingriffmom_schnell 416;
BA_ "GenSigTimeoutMsg_Gateway_C6" SG_ 416 ASR_Eingriffmom_schnell 416;
BA_ "GenSigAutoGenDsp" SG_ 416 ASR_Schaltbeeinflussung 0;
BA_ "GenSigAutoGenSnd" SG_ 416 ASR_Schaltbeeinflussung 0;
BA_ "GenSigSendType" SG_ 416 ASR_Schaltbeeinflussung 7;
BA_ "NWM-WakeupAllowed" SG_ 416 ASR_Schaltbeeinflussung 0;
BA_ "GenSigTimeoutMsg__6HP_C6" SG_ 416 ASR_Schaltbeeinflussung 416;
BA_ "GenSigTimeoutMsg_Gateway_C6" SG_ 416 ASR_Schaltbeeinflussung 416;
BA_ "GenSigAutoGenDsp" SG_ 416 ASR_Steuergeraet 0;
BA_ "GenSigAutoGenSnd" SG_ 416 ASR_Steuergeraet 0;
BA_ "GenSigSendType" SG_ 416 ASR_Steuergeraet 7;
BA_ "NWM-WakeupAllowed" SG_ 416 ASR_Steuergeraet 0;
BA_ "GenSigTimeoutMsg_DME_ME7_MED9_C6" SG_ 416 ASR_Steuergeraet 416;
BA_ "GenSigTimeoutMsg_Gateway_C6" SG_ 416 ASR_Steuergeraet 416;
BA_ "GenSigAutoGenDsp" SG_ 416 BKL 0;
BA_ "GenSigAutoGenSnd" SG_ 416 BKL 0;
BA_ "GenSigSendType" SG_ 416 BKL 7;
BA_ "GenSigStartValue" SG_ 416 BKL 1;
BA_ "NWM-WakeupAllowed" SG_ 416 BKL 0;
BA_ "GenSigTimeoutMsg_Gateway_C6" SG_ 416 BKL 416;
BA_ "GenSigAutoGenDsp" SG_ 416 Bremslichtschalter_ESP 0;
BA_ "GenSigAutoGenSnd" SG_ 416 Bremslichtschalter_ESP 0;
BA_ "GenSigSendType" SG_ 416 Bremslichtschalter_ESP 7;
BA_ "NWM-WakeupAllowed" SG_ 416 Bremslichtschalter_ESP 0;
BA_ "GenSigTimeoutMsg__4CL_C6" SG_ 416 Bremslichtschalter_ESP 416;
BA_ "GenSigTimeoutMsg_DME_EDC16CP3000" SG_ 416 Bremslichtschalter_ESP 416;
BA_ "GenSigTimeoutMsg_DME_ME7_MED9_C6" SG_ 416 Bremslichtschalter_ESP 416;
BA_ "GenSigTimeoutMsg_DME_SIMOS6_C6" SG_ 416 Bremslichtschalter_ESP 416;
BA_ "GenSigTimeoutMsg_EPB_C6" SG_ 416 Bremslichtschalter_ESP 416;
BA_ "GenSigTimeoutMsg_Gateway_C6" SG_ 416 Bremslichtschalter_ESP 416;
BA_ "GenSigTimeoutMsg_LWR_AFS_C6" SG_ 416 Bremslichtschalter_ESP 416;
BA_ "GenSigAutoGenDsp" SG_ 416 Bremstestschalter_ESP 0;
BA_ "GenSigAutoGenSnd" SG_ 416 Bremstestschalter_ESP 0;
BA_ "GenSigSendType" SG_ 416 Bremstestschalter_ESP 7;
BA_ "NWM-WakeupAllowed" SG_ 416 Bremstestschalter_ESP 0;
BA_ "GenSigTimeoutMsg_DME_EDC16CP3000" SG_ 416 Bremstestschalter_ESP 416;
BA_ "GenSigTimeoutMsg_DME_ME7_MED9_C6" SG_ 416 Bremstestschalter_ESP 416;
BA_ "GenSigTimeoutMsg_DME_SIMOS6_C6" SG_ 416 Bremstestschalter_ESP 416;
BA_ "GenSigTimeoutMsg_EPB_C6" SG_ 416 Bremstestschalter_ESP 416;
BA_ "GenSigTimeoutMsg_Gateway_C6" SG_ 416 Bremstestschalter_ESP 416;
BA_ "GenSigTimeoutMsg_LWR_AFS_C6" SG_ 416 Bremstestschalter_ESP 416;
BA_ "GenSigAutoGenDsp" SG_ 416 BZ_Bremse1 0;
BA_ "GenSigAutoGenSnd" SG_ 416 BZ_Bremse1 0;
BA_ "GenSigSendType" SG_ 416 BZ_Bremse1 7;
BA_ "NWM-WakeupAllowed" SG_ 416 BZ_Bremse1 0;
BA_ "GenSigTimeoutMsg__4CL_C6" SG_ 416 BZ_Bremse1 416;
BA_ "GenSigTimeoutMsg_DME_EDC16CP3000" SG_ 416 BZ_Bremse1 416;
BA_ "GenSigTimeoutMsg_DME_ME7_MED9_C6" SG_ 416 BZ_Bremse1 416;
BA_ "GenSigTimeoutMsg_DME_SIMOS6_C6" SG_ 416 BZ_Bremse1 416;
BA_ "GenSigTimeoutMsg_EPB_C6" SG_ 416 BZ_Bremse1 416;
BA_ "GenSigTimeoutMsg_Gateway_C6" SG_ 416 BZ_Bremse1 416;
BA_ "GenSigAutoGenDsp" SG_ 416 EBV_Eingriff 0;
BA_ "GenSigAutoGenSnd" SG_ 416 EBV_Eingriff 0;
BA_ "GenSigSendType" SG_ 416 EBV_Eingriff 7;
BA_ "NWM-WakeupAllowed" SG_ 416 EBV_Eingriff 0;
BA_ "GenSigTimeoutMsg_EPB_C6" SG_ 416 EBV_Eingriff 416;
BA_ "GenSigTimeoutMsg_Gateway_C6" SG_ 416 EBV_Eingriff 416;
BA_ "GenSigAutoGenDsp" SG_ 416 EDS_Eingriff 0;
BA_ "GenSigAutoGenSnd" SG_ 416 EDS_Eingriff 0;
BA_ "GenSigSendType" SG_ 416 EDS_Eingriff 7;
BA_ "NWM-WakeupAllowed" SG_ 416 EDS_Eingriff 0;
BA_ "GenSigTimeoutMsg_DME_EDC16CP3000" SG_ 416 EDS_Eingriff 416;
BA_ "GenSigTimeoutMsg_DME_ME7_MED9_C6" SG_ 416 EDS_Eingriff 416;
BA_ "GenSigTimeoutMsg_DME_SIMOS6_C6" SG_ 416 EDS_Eingriff 416;
BA_ "GenSigTimeoutMsg_Gateway_C6" SG_ 416 EDS_Eingriff 416;
BA_ "GenSigAutoGenDsp" SG_ 416 ESP_Eingriff 0;
BA_ "GenSigAutoGenSnd" SG_ 416 ESP_Eingriff 0;
BA_ "GenSigSendType" SG_ 416 ESP_Eingriff 7;
BA_ "NWM-WakeupAllowed" SG_ 416 ESP_Eingriff 0;
BA_ "GenSigTimeoutMsg__4CL_C6" SG_ 416 ESP_Eingriff 416;
BA_ "GenSigTimeoutMsg__6HP_C6" SG_ 416 ESP_Eingriff 416;
BA_ "GenSigTimeoutMsg_DME_EDC16CP3000" SG_ 416 ESP_Eingriff 416;
BA_ "GenSigTimeoutMsg_DME_ME7_MED9_C6" SG_ 416 ESP_Eingriff 416;
BA_ "GenSigTimeoutMsg_DME_SIMOS6_C6" SG_ 416 ESP_Eingriff 416;
BA_ "GenSigTimeoutMsg_EPB_C6" SG_ 416 ESP_Eingriff 416;
BA_ "GenSigTimeoutMsg_Gateway_C6" SG_ 416 ESP_Eingriff 416;
BA_ "GenSigAutoGenDsp" SG_ 416 ESP_passiv_getastet 0;
BA_ "GenSigAutoGenSnd" SG_ 416 ESP_passiv_getastet 0;
BA_ "GenSigSendType" SG_ 416 ESP_passiv_getastet 7;
BA_ "NWM-WakeupAllowed" SG_ 416 ESP_passiv_getastet 0;
BA_ "GenSigTimeoutMsg__6HP_C6" SG_ 416 ESP_passiv_getastet 416;
BA_ "GenSigTimeoutMsg_Gateway_C6" SG_ 416 ESP_passiv_getastet 416;
BA_ "GenSigAutoGenDsp" SG_ 416 ESP_Systemstatus 0;
BA_ "GenSigAutoGenSnd" SG_ 416 ESP_Systemstatus 0;
BA_ "GenSigSendType" SG_ 416 ESP_Systemstatus 7;
BA_ "NWM-WakeupAllowed" SG_ 416 ESP_Systemstatus 0;
BA_ "GenSigTimeoutMsg__4CL_C6" SG_ 416 ESP_Systemstatus 416;
BA_ "GenSigTimeoutMsg_DME_EDC16CP3000" SG_ 416 ESP_Systemstatus 416;
BA_ "GenSigTimeoutMsg_DME_SIMOS6_C6" SG_ 416 ESP_Systemstatus 416;
BA_ "GenSigTimeoutMsg_EPB_C6" SG_ 416 ESP_Systemstatus 416;
BA_ "GenSigTimeoutMsg_Gateway_C6" SG_ 416 ESP_Systemstatus 416;
BA_ "GenSigAutoGenDsp" SG_ 416 Fahrer_bremst 1;
BA_ "GenSigAutoGenSnd" SG_ 416 Fahrer_bremst 1;
BA_ "GenSigSendType" SG_ 416 Fahrer_bremst 7;
BA_ "NWM-WakeupAllowed" SG_ 416 Fahrer_bremst 0;
BA_ "GenSigTimeoutMsg_Gateway_C6" SG_ 416 Fahrer_bremst 416;
BA_ "GenSigAutoGenDsp" SG_ 416 FStatus_Schlechtwegausblendung 0;
BA_ "GenSigAutoGenSnd" SG_ 416 FStatus_Schlechtwegausblendung 0;
BA_ "GenSigSendType" SG_ 416 FStatus_Schlechtwegausblendung 7;
BA_ "NWM-WakeupAllowed" SG_ 416 FStatus_Schlechtwegausblendung 0;
BA_ "GenSigTimeoutMsg_DME_ME7_MED9_C6" SG_ 416 FStatus_Schlechtwegausblendung 416;
BA_ "GenSigTimeoutMsg_DME_SIMOS6_C6" SG_ 416 FStatus_Schlechtwegausblendung 416;
BA_ "GenSigTimeoutMsg_Gateway_C6" SG_ 416 FStatus_Schlechtwegausblendung 416;
BA_ "GenSigAutoGenDsp" SG_ 416 Geschwindigkeit_15Bit 0;
BA_ "GenSigAutoGenSnd" SG_ 416 Geschwindigkeit_15Bit 0;
BA_ "GenSigSendType" SG_ 416 Geschwindigkeit_15Bit 7;
BA_ "GenSigStartValue" SG_ 416 Geschwindigkeit_15Bit 32708;
BA_ "NWM-WakeupAllowed" SG_ 416 Geschwindigkeit_15Bit 0;
BA_ "GenSigTimeoutMsg__6HP_C6" SG_ 416 Geschwindigkeit_15Bit 416;
BA_ "GenSigTimeoutMsg_Airbag_C6" SG_ 416 Geschwindigkeit_15Bit 416;
BA_ "GenSigTimeoutMsg_DME_EDC16CP3000" SG_ 416 Geschwindigkeit_15Bit 416;
BA_ "GenSigTimeoutMsg_DME_ME7_MED9_C6" SG_ 416 Geschwindigkeit_15Bit 416;
BA_ "GenSigTimeoutMsg_DME_SIMOS6_C6" SG_ 416 Geschwindigkeit_15Bit 416;
BA_ "GenSigTimeoutMsg_EPB_C6" SG_ 416 Geschwindigkeit_15Bit 416;
BA_ "GenSigTimeoutMsg_Gateway_C6" SG_ 416 Geschwindigkeit_15Bit 416;
BA_ "GenSigAutoGenDsp" SG_ 416 Geschwindigkeitersatzwert 0;
BA_ "GenSigAutoGenSnd" SG_ 416 Geschwindigkeitersatzwert 0;
BA_ "GenSigSendType" SG_ 416 Geschwindigkeitersatzwert 7;
BA_ "GenSigStartValue" SG_ 416 Geschwindigkeitersatzwert 1;
BA_ "NWM-WakeupAllowed" SG_ 416 Geschwindigkeitersatzwert 0;
BA_ "GenSigTimeoutMsg_Airbag_C6" SG_ 416 Geschwindigkeitersatzwert 416;
BA_ "GenSigTimeoutMsg_DME_SIMOS6_C6" SG_ 416 Geschwindigkeitersatzwert 416;
BA_ "GenSigTimeoutMsg_EPB_C6" SG_ 416 Geschwindigkeitersatzwert 416;
BA_ "GenSigTimeoutMsg_Gateway_C6" SG_ 416 Geschwindigkeitersatzwert 416;
BA_ "GenSigAutoGenDsp" SG_ 416 Lampe_ABS 0;
BA_ "GenSigAutoGenSnd" SG_ 416 Lampe_ABS 0;
BA_ "GenSigSendType" SG_ 416 Lampe_ABS 7;
BA_ "GenSigStartValue" SG_ 416 Lampe_ABS 1;
BA_ "NWM-WakeupAllowed" SG_ 416 Lampe_ABS 0;
BA_ "GenSigTimeoutMsg__6HP_C6" SG_ 416 Lampe_ABS 416;
BA_ "GenSigTimeoutMsg_Gateway_C6" SG_ 416 Lampe_ABS 416;
BA_ "GenSigAutoGenDsp" SG_ 416 Lampe_ASR_ESP 0;
BA_ "GenSigAutoGenSnd" SG_ 416 Lampe_ASR_ESP 0;
BA_ "GenSigSendType" SG_ 416 Lampe_ASR_ESP 7;
BA_ "GenSigStartValue" SG_ 416 Lampe_ASR_ESP 1;
BA_ "NWM-WakeupAllowed" SG_ 416 Lampe_ASR_ESP 0;
BA_ "GenSigTimeoutMsg_Gateway_C6" SG_ 416 Lampe_ASR_ESP 416;
BA_ "GenSigAutoGenDsp" SG_ 416 MSR_Anforderung 0;
BA_ "GenSigAutoGenSnd" SG_ 416 MSR_Anforderung 0;
BA_ "GenSigSendType" SG_ 416 MSR_Anforderung 7;
BA_ "NWM-WakeupAllowed" SG_ 416 MSR_Anforderung 0;
BA_ "GenSigTimeoutMsg_Airbag_C6" SG_ 416 MSR_Anforderung 416;
BA_ "GenSigTimeoutMsg_DME_EDC16CP3000" SG_ 416 MSR_Anforderung 416;
BA_ "GenSigTimeoutMsg_DME_ME7_MED9_C6" SG_ 416 MSR_Anforderung 416;
BA_ "GenSigTimeoutMsg_DME_SIMOS6_C6" SG_ 416 MSR_Anforderung 416;
BA_ "GenSigTimeoutMsg_EPB_C6" SG_ 416 MSR_Anforderung 416;
BA_ "GenSigTimeoutMsg_Gateway_C6" SG_ 416 MSR_Anforderung 416;
BA_ "GenSigAutoGenDsp" SG_ 416 MSR_Eingriffmom 0;
BA_ "GenSigAutoGenSnd" SG_ 416 MSR_Eingriffmom 0;
BA_ "GenSigSendType" SG_ 416 MSR_Eingriffmom 7;
BA_ "NWM-WakeupAllowed" SG_ 416 MSR_Eingriffmom 0;
BA_ "GenSigTimeoutMsg_DME_EDC16CP3000" SG_ 416 MSR_Eingriffmom 416;
BA_ "GenSigTimeoutMsg_DME_ME7_MED9_C6" SG_ 416 MSR_Eingriffmom 416;
BA_ "GenSigTimeoutMsg_DME_SIMOS6_C6" SG_ 416 MSR_Eingriffmom 416;
BA_ "GenSigTimeoutMsg_Gateway_C6" SG_ 416 MSR_Eingriffmom 416;
BA_ "GenSigAutoGenDsp" SG_ 416 Schlechtwegausblendung 0;
BA_ "GenSigAutoGenSnd" SG_ 416 Schlechtwegausblendung 0;
BA_ "GenSigSendType" SG_ 416 Schlechtwegausblendung 7;
BA_ "NWM-WakeupAllowed" SG_ 416 Schlechtwegausblendung 0;
BA_ "GenSigTimeoutMsg_DME_ME7_MED9_C6" SG_ 416 Schlechtwegausblendung 416;
BA_ "GenSigTimeoutMsg_DME_SIMOS6_C6" SG_ 416 Schlechtwegausblendung 416;
BA_ "GenSigTimeoutMsg_Gateway_C6" SG_ 416 Schlechtwegausblendung 416;
BA_ "GenSigAutoGenDsp" SG_ 416 Status_aktives_Bremssystem 1;
BA_ "GenSigAutoGenSnd" SG_ 416 Status_aktives_Bremssystem 1;
BA_ "GenSigSendType" SG_ 416 Status_aktives_Bremssystem 7;
BA_ "NWM-WakeupAllowed" SG_ 416 Status_aktives_Bremssystem 0;
BA_ "GenSigTimeoutMsg_Gateway_C6" SG_ 416 Status_aktives_Bremssystem 416;
BA_ "GenSigAutoGenDsp" SG_ 1440 Akustische_Warnung 1;
BA_ "GenSigAutoGenSnd" SG_ 1440 Akustische_Warnung 1;
BA_ "GenSigSendType" SG_ 1440 Akustische_Warnung 7;
BA_ "NWM-WakeupAllowed" SG_ 1440 Akustische_Warnung 0;
BA_ "GenSigTimeoutMsg_Gateway_C6" SG_ 1440 Akustische_Warnung 1440;
BA_ "GenSigAutoGenDsp" SG_ 1440 BKL 0;
BA_ "GenSigAutoGenSnd" SG_ 1440 BKL 0;
BA_ "GenSigSendType" SG_ 1440 BKL 7;
BA_ "GenSigStartValue" SG_ 1440 BKL 1;
BA_ "NWM-WakeupAllowed" SG_ 1440 BKL 0;
BA_ "GenSigTimeoutMsg_Gateway_C6" SG_ 1440 BKL 1440;
BA_ "GenSigAutoGenDsp" SG_ 1440 Bremskontroll_Blinkmode 1;
BA_ "GenSigAutoGenSnd" SG_ 1440 Bremskontroll_Blinkmode 1;
BA_ "GenSigSendType" SG_ 1440 Bremskontroll_Blinkmode 7;
BA_ "NWM-WakeupAllowed" SG_ 1440 Bremskontroll_Blinkmode 0;
BA_ "GenSigTimeoutMsg_Gateway_C6" SG_ 1440 Bremskontroll_Blinkmode 1440;
BA_ "GenSigAutoGenDsp" SG_ 1440 BZ_Bremse2 1;
BA_ "GenSigAutoGenSnd" SG_ 1440 BZ_Bremse2 1;
BA_ "GenSigSendType" SG_ 1440 BZ_Bremse2 7;
BA_ "NWM-WakeupAllowed" SG_ 1440 BZ_Bremse2 0;
BA_ "GenSigTimeoutMsg__4CL_C6" SG_ 1440 BZ_Bremse2 1440;
BA_ "GenSigTimeoutMsg_Gateway_C6" SG_ 1440 BZ_Bremse2 1440;
BA_ "GenSigAutoGenDsp" SG_ 1440 FSPE_Bremse 0;
BA_ "GenSigAutoGenSnd" SG_ 1440 FSPE_Bremse 0;
BA_ "GenSigSendType" SG_ 1440 FSPE_Bremse 7;
BA_ "NWM-WakeupAllowed" SG_ 1440 FSPE_Bremse 0;
BA_ "GenSigTimeoutMsg_Gateway_C6" SG_ 1440 FSPE_Bremse 1440;
BA_ "GenSigAutoGenDsp" SG_ 1440 FStatus_Wegimpulse 0;
BA_ "GenSigAutoGenSnd" SG_ 1440 FStatus_Wegimpulse 0;
BA_ "GenSigSendType" SG_ 1440 FStatus_Wegimpulse 7;
BA_ "NWM-WakeupAllowed" SG_ 1440 FStatus_Wegimpulse 0;
BA_ "GenSigTimeoutMsg_Gateway_C6" SG_ 1440 FStatus_Wegimpulse 1440;
BA_ "GenSigAutoGenDsp" SG_ 1440 Gemessene_Querbeschleunigung 0;
BA_ "GenSigAutoGenSnd" SG_ 1440 Gemessene_Querbeschleunigung 0;
BA_ "GenSigSendType" SG_ 1440 Gemessene_Querbeschleunigung 7;
BA_ "NWM-WakeupAllowed" SG_ 1440 Gemessene_Querbeschleunigung 0;
BA_ "GenSigTimeoutMsg_Gateway_C6" SG_ 1440 Gemessene_Querbeschleunigung 1440;
BA_ "GenSigAutoGenDsp" SG_ 1440 Impulszahl 0;
BA_ "GenSigAutoGenSnd" SG_ 1440 Impulszahl 0;
BA_ "GenSigSendType" SG_ 1440 Impulszahl 7;
BA_ "NWM-WakeupAllowed" SG_ 1440 Impulszahl 0;
BA_ "GenSigTimeoutMsg_Gateway_C6" SG_ 1440 Impulszahl 1440;
BA_ "GenSigAutoGenDsp" SG_ 1440 Lampe_ABS 0;
BA_ "GenSigAutoGenSnd" SG_ 1440 Lampe_ABS 0;
BA_ "GenSigSendType" SG_ 1440 Lampe_ABS 7;
BA_ "GenSigStartValue" SG_ 1440 Lampe_ABS 1;
BA_ "NWM-WakeupAllowed" SG_ 1440 Lampe_ABS 0;
BA_ "GenSigTimeoutMsg_Gateway_C6" SG_ 1440 Lampe_ABS 1440;
BA_ "GenSigAutoGenDsp" SG_ 1440 Lampe_ASR_ESP 0;
BA_ "GenSigAutoGenSnd" SG_ 1440 Lampe_ASR_ESP 0;
BA_ "GenSigSendType" SG_ 1440 Lampe_ASR_ESP 7;
BA_ "GenSigStartValue" SG_ 1440 Lampe_ASR_ESP 1;
BA_ "NWM-WakeupAllowed" SG_ 1440 Lampe_ASR_ESP 0;
BA_ "GenSigTimeoutMsg_Gateway_C6" SG_ 1440 Lampe_ASR_ESP 1440;
BA_ "GenSigAutoGenDsp" SG_ 1440 Mittlere_Raddrehzahl 0;
BA_ "GenSigAutoGenSnd" SG_ 1440 Mittlere_Raddrehzahl 0;
BA_ "GenSigSendType" SG_ 1440 Mittlere_Raddrehzahl 7;
BA_ "GenSigStartValue" SG_ 1440 Mittlere_Raddrehzahl 32708;
BA_ "NWM-WakeupAllowed" SG_ 1440 Mittlere_Raddrehzahl 0;
BA_ "GenSigTimeoutMsg_Gateway_C6" SG_ 1440 Mittlere_Raddrehzahl 1440;
BA_ "GenSigAutoGenDsp" SG_ 1440 Mux_Code_Bremse2 0;
BA_ "GenSigAutoGenSnd" SG_ 1440 Mux_Code_Bremse2 0;
BA_ "GenSigSendType" SG_ 1440 Mux_Code_Bremse2 7;
BA_ "GenSigStartValue" SG_ 1440 Mux_Code_Bremse2 1;
BA_ "NWM-WakeupAllowed" SG_ 1440 Mux_Code_Bremse2 0;
BA_ "GenSigTimeoutMsg__4CL_C6" SG_ 1440 Mux_Code_Bremse2 1440;
BA_ "GenSigTimeoutMsg__6HP_C6" SG_ 1440 Mux_Code_Bremse2 1440;
BA_ "GenSigTimeoutMsg_DME_EDC16CP3000" SG_ 1440 Mux_Code_Bremse2 1440;
BA_ "GenSigTimeoutMsg_DME_ME7_MED9_C6" SG_ 1440 Mux_Code_Bremse2 1440;
BA_ "GenSigTimeoutMsg_DME_SIMOS6_C6" SG_ 1440 Mux_Code_Bremse2 1440;
BA_ "GenSigTimeoutMsg_Gateway_C6" SG_ 1440 Mux_Code_Bremse2 1440;
BA_ "GenSigAutoGenDsp" SG_ 1440 QBit_Querbeschleunigung 0;
BA_ "GenSigAutoGenSnd" SG_ 1440 QBit_Querbeschleunigung 0;
BA_ "GenSigSendType" SG_ 1440 QBit_Querbeschleunigung 7;
BA_ "NWM-WakeupAllowed" SG_ 1440 QBit_Querbeschleunigung 0;
BA_ "GenSigTimeoutMsg__4CL_C6" SG_ 1440 QBit_Querbeschleunigung 1440;
BA_ "GenSigTimeoutMsg_Gateway_C6" SG_ 1440 QBit_Querbeschleunigung 1440;
BA_ "GenSigAutoGenDsp" SG_ 1440 Querbeschleunigung 0;
BA_ "GenSigAutoGenSnd" SG_ 1440 Querbeschleunigung 0;
BA_ "GenSigSendType" SG_ 1440 Querbeschleunigung 7;
BA_ "NWM-WakeupAllowed" SG_ 1440 Querbeschleunigung 0;
BA_ "GenSigTimeoutMsg__4CL_C6" SG_ 1440 Querbeschleunigung 1440;
BA_ "GenSigTimeoutMsg__6HP_C6" SG_ 1440 Querbeschleunigung 1440;
BA_ "GenSigTimeoutMsg_DME_EDC16CP3000" SG_ 1440 Querbeschleunigung 1440;
BA_ "GenSigTimeoutMsg_DME_ME7_MED9_C6" SG_ 1440 Querbeschleunigung 1440;
BA_ "GenSigTimeoutMsg_DME_SIMOS6_C6" SG_ 1440 Querbeschleunigung 1440;
BA_ "GenSigTimeoutMsg_Gateway_C6" SG_ 1440 Querbeschleunigung 1440;
BA_ "GenSigAutoGenDsp" SG_ 1440 SIB_ESP 0;
BA_ "GenSigAutoGenSnd" SG_ 1440 SIB_ESP 0;
BA_ "GenSigSendType" SG_ 1440 SIB_ESP 7;
BA_ "NWM-WakeupAllowed" SG_ 1440 SIB_ESP 0;
BA_ "GenSigTimeoutMsg_Gateway_C6" SG_ 1440 SIB_ESP 1440;
BA_ "GenSigAutoGenDsp" SG_ 1440 Textbits_Bremse 1;
BA_ "GenSigAutoGenSnd" SG_ 1440 Textbits_Bremse 1;
BA_ "GenSigSendType" SG_ 1440 Textbits_Bremse 7;
BA_ "NWM-WakeupAllowed" SG_ 1440 Textbits_Bremse 0;
BA_ "GenSigTimeoutMsg_Gateway_C6" SG_ 1440 Textbits_Bremse 1440;
BA_ "GenSigAutoGenDsp" SG_ 1440 Warnlampe_RKA 1;
BA_ "GenSigAutoGenSnd" SG_ 1440 Warnlampe_RKA 1;
BA_ "GenSigSendType" SG_ 1440 Warnlampe_RKA 7;
BA_ "NWM-WakeupAllowed" SG_ 1440 Warnlampe_RKA 0;
BA_ "GenSigTimeoutMsg_Gateway_C6" SG_ 1440 Warnlampe_RKA 1440;
BA_ "GenSigAutoGenDsp" SG_ 1440 Wegimpulse_VA 0;
BA_ "GenSigAutoGenSnd" SG_ 1440 Wegimpulse_VA 0;
BA_ "GenSigSendType" SG_ 1440 Wegimpulse_VA 7;
BA_ "NWM-WakeupAllowed" SG_ 1440 Wegimpulse_VA 0;
BA_ "GenSigTimeoutMsg_Gateway_C6" SG_ 1440 Wegimpulse_VA 1440;
BA_ "GenSigAutoGenDsp" SG_ 1440 Wegimpulszaehlerstatus 0;
BA_ "GenSigAutoGenSnd" SG_ 1440 Wegimpulszaehlerstatus 0;
BA_ "GenSigSendType" SG_ 1440 Wegimpulszaehlerstatus 7;
BA_ "NWM-WakeupAllowed" SG_ 1440 Wegimpulszaehlerstatus 0;
BA_ "GenSigTimeoutMsg_Gateway_C6" SG_ 1440 Wegimpulszaehlerstatus 1440;
BA_ "GenSigAutoGenDsp" SG_ 1440 Zaehnezahl 1;
BA_ "GenSigAutoGenSnd" SG_ 1440 Zaehnezahl 1;
BA_ "GenSigSendType" SG_ 1440 Zaehnezahl 7;
BA_ "NWM-WakeupAllowed" SG_ 1440 Zaehnezahl 0;
BA_ "GenSigTimeoutMsg_Gateway_C6" SG_ 1440 Zaehnezahl 1440;
BA_ "GenSigAutoGenDsp" SG_ 1184 Fahrtrichtung_HL 0;
BA_ "GenSigAutoGenSnd" SG_ 1184 Fahrtrichtung_HL 0;
BA_ "GenSigSendType" SG_ 1184 Fahrtrichtung_HL 7;
BA_ "NWM-WakeupAllowed" SG_ 1184 Fahrtrichtung_HL 0;
BA_ "GenSigTimeoutMsg_Gateway_C6" SG_ 1184 Fahrtrichtung_HL 1184;
BA_ "GenSigTimeoutMsg_LWR_AFS_C6" SG_ 1184 Fahrtrichtung_HL 1184;
BA_ "GenSigTimeoutMsg_LWS_C6" SG_ 1184 Fahrtrichtung_HL 1184;
BA_ "GenSigAutoGenDsp" SG_ 1184 Fahrtrichtung_HR 0;
BA_ "GenSigAutoGenSnd" SG_ 1184 Fahrtrichtung_HR 0;
BA_ "GenSigSendType" SG_ 1184 Fahrtrichtung_HR 7;
BA_ "NWM-WakeupAllowed" SG_ 1184 Fahrtrichtung_HR 0;
BA_ "GenSigTimeoutMsg_Gateway_C6" SG_ 1184 Fahrtrichtung_HR 1184;
BA_ "GenSigTimeoutMsg_LWR_AFS_C6" SG_ 1184 Fahrtrichtung_HR 1184;
BA_ "GenSigTimeoutMsg_LWS_C6" SG_ 1184 Fahrtrichtung_HR 1184;
BA_ "GenSigAutoGenDsp" SG_ 1184 Fahrtrichtung_VL 0;
BA_ "GenSigAutoGenSnd" SG_ 1184 Fahrtrichtung_VL 0;
BA_ "GenSigSendType" SG_ 1184 Fahrtrichtung_VL 7;
BA_ "NWM-WakeupAllowed" SG_ 1184 Fahrtrichtung_VL 0;
BA_ "GenSigTimeoutMsg_Gateway_C6" SG_ 1184 Fahrtrichtung_VL 1184;
BA_ "GenSigTimeoutMsg_LWS_C6" SG_ 1184 Fahrtrichtung_VL 1184;
BA_ "GenSigAutoGenDsp" SG_ 1184 Fahrtrichtung_VR 0;
BA_ "GenSigAutoGenSnd" SG_ 1184 Fahrtrichtung_VR 0;
BA_ "GenSigSendType" SG_ 1184 Fahrtrichtung_VR 7;
BA_ "NWM-WakeupAllowed" SG_ 1184 Fahrtrichtung_VR 0;
BA_ "GenSigTimeoutMsg_Gateway_C6" SG_ 1184 Fahrtrichtung_VR 1184;
BA_ "GenSigTimeoutMsg_LWS_C6" SG_ 1184 Fahrtrichtung_VR 1184;
BA_ "GenSigAutoGenDsp" SG_ 1184 Radgeschw_HL 0;
BA_ "GenSigAutoGenSnd" SG_ 1184 Radgeschw_HL 0;
BA_ "GenSigSendType" SG_ 1184 Radgeschw_HL 7;
BA_ "GenSigStartValue" SG_ 1184 Radgeschw_HL 32708;
BA_ "NWM-WakeupAllowed" SG_ 1184 Radgeschw_HL 0;
BA_ "GenSigTimeoutMsg__6HP_C6" SG_ 1184 Radgeschw_HL 1184;
BA_ "GenSigTimeoutMsg_DME_ME7_MED9_C6" SG_ 1184 Radgeschw_HL 1184;
BA_ "GenSigTimeoutMsg_DME_SIMOS6_C6" SG_ 1184 Radgeschw_HL 1184;
BA_ "GenSigTimeoutMsg_EPB_C6" SG_ 1184 Radgeschw_HL 1184;
BA_ "GenSigTimeoutMsg_Gateway_C6" SG_ 1184 Radgeschw_HL 1184;
BA_ "GenSigTimeoutMsg_LWR_AFS_C6" SG_ 1184 Radgeschw_HL 1184;
BA_ "GenSigTimeoutMsg_LWS_C6" SG_ 1184 Radgeschw_HL 1184;
BA_ "GenSigAutoGenDsp" SG_ 1184 Radgeschw_HR 0;
BA_ "GenSigAutoGenSnd" SG_ 1184 Radgeschw_HR 0;
BA_ "GenSigSendType" SG_ 1184 Radgeschw_HR 7;
BA_ "GenSigStartValue" SG_ 1184 Radgeschw_HR 32708;
BA_ "NWM-WakeupAllowed" SG_ 1184 Radgeschw_HR 0;
BA_ "GenSigTimeoutMsg__6HP_C6" SG_ 1184 Radgeschw_HR 1184;
BA_ "GenSigTimeoutMsg_DME_ME7_MED9_C6" SG_ 1184 Radgeschw_HR 1184;
BA_ "GenSigTimeoutMsg_DME_SIMOS6_C6" SG_ 1184 Radgeschw_HR 1184;
BA_ "GenSigTimeoutMsg_EPB_C6" SG_ 1184 Radgeschw_HR 1184;
BA_ "GenSigTimeoutMsg_Gateway_C6" SG_ 1184 Radgeschw_HR 1184;
BA_ "GenSigTimeoutMsg_LWR_AFS_C6" SG_ 1184 Radgeschw_HR 1184;
BA_ "GenSigTimeoutMsg_LWS_C6" SG_ 1184 Radgeschw_HR 1184;
BA_ "GenSigAutoGenDsp" SG_ 1184 Radgeschw_VL 0;
BA_ "GenSigAutoGenSnd" SG_ 1184 Radgeschw_VL 0;
BA_ "GenSigSendType" SG_ 1184 Radgeschw_VL 7;
BA_ "GenSigStartValue" SG_ 1184 Radgeschw_VL 32708;
BA_ "NWM-WakeupAllowed" SG_ 1184 Radgeschw_VL 0;
BA_ "GenSigTimeoutMsg__6HP_C6" SG_ 1184 Radgeschw_VL 1184;
BA_ "GenSigTimeoutMsg_DME_ME7_MED9_C6" SG_ 1184 Radgeschw_VL 1184;
BA_ "GenSigTimeoutMsg_DME_SIMOS6_C6" SG_ 1184 Radgeschw_VL 1184;
BA_ "GenSigTimeoutMsg_EPB_C6" SG_ 1184 Radgeschw_VL 1184;
BA_ "GenSigTimeoutMsg_Gateway_C6" SG_ 1184 Radgeschw_VL 1184;
BA_ "GenSigTimeoutMsg_LWS_C6" SG_ 1184 Radgeschw_VL 1184;
BA_ "GenSigAutoGenDsp" SG_ 1184 Radgeschw_VR 0;
BA_ "GenSigAutoGenSnd" SG_ 1184 Radgeschw_VR 0;
BA_ "GenSigSendType" SG_ 1184 Radgeschw_VR 7;
BA_ "GenSigStartValue" SG_ 1184 Radgeschw_VR 32708;
BA_ "NWM-WakeupAllowed" SG_ 1184 Radgeschw_VR 0;
BA_ "GenSigTimeoutMsg__6HP_C6" SG_ 1184 Radgeschw_VR 1184;
BA_ "GenSigTimeoutMsg_DME_ME7_MED9_C6" SG_ 1184 Radgeschw_VR 1184;
BA_ "GenSigTimeoutMsg_DME_SIMOS6_C6" SG_ 1184 Radgeschw_VR 1184;
BA_ "GenSigTimeoutMsg_EPB_C6" SG_ 1184 Radgeschw_VR 1184;
BA_ "GenSigTimeoutMsg_Gateway_C6" SG_ 1184 Radgeschw_VR 1184;
BA_ "GenSigTimeoutMsg_LWS_C6" SG_ 1184 Radgeschw_VR 1184;
BA_ "GenSigAutoGenDsp" SG_ 1192 Anfahrhilfe_aktiv 0;
BA_ "GenSigAutoGenSnd" SG_ 1192 Anfahrhilfe_aktiv 0;
BA_ "GenSigSendType" SG_ 1192 Anfahrhilfe_aktiv 7;
BA_ "NWM-WakeupAllowed" SG_ 1192 Anfahrhilfe_aktiv 0;
BA_ "GenSigTimeoutMsg_EPB_C6" SG_ 1192 Anfahrhilfe_aktiv 1192;
BA_ "GenSigTimeoutMsg_Gateway_C6" SG_ 1192 Anfahrhilfe_aktiv 1192;
BA_ "GenSigAutoGenDsp" SG_ 1192 AWV2_Durchfuehrung_Bremsruck 1;
BA_ "GenSigAutoGenSnd" SG_ 1192 AWV2_Durchfuehrung_Bremsruck 1;
BA_ "GenSigSendType" SG_ 1192 AWV2_Durchfuehrung_Bremsruck 7;
BA_ "NWM-WakeupAllowed" SG_ 1192 AWV2_Durchfuehrung_Bremsruck 0;
BA_ "GenSigTimeoutMsg_Gateway_C6" SG_ 1192 AWV2_Durchfuehrung_Bremsruck 1192;
BA_ "GenSigAutoGenDsp" SG_ 1192 Bremsdruck 0;
BA_ "GenSigAutoGenSnd" SG_ 1192 Bremsdruck 0;
BA_ "GenSigSendType" SG_ 1192 Bremsdruck 7;
BA_ "NWM-WakeupAllowed" SG_ 1192 Bremsdruck 0;
BA_ "GenSigTimeoutMsg__4CL_C6" SG_ 1192 Bremsdruck 1192;
BA_ "GenSigTimeoutMsg_EPB_C6" SG_ 1192 Bremsdruck 1192;
BA_ "GenSigTimeoutMsg_Gateway_C6" SG_ 1192 Bremsdruck 1192;
BA_ "GenSigAutoGenDsp" SG_ 1192 Bremsdruck_ungueltig 0;
BA_ "GenSigAutoGenSnd" SG_ 1192 Bremsdruck_ungueltig 0;
BA_ "GenSigSendType" SG_ 1192 Bremsdruck_ungueltig 7;
BA_ "GenSigStartValue" SG_ 1192 Bremsdruck_ungueltig 1;
BA_ "NWM-WakeupAllowed" SG_ 1192 Bremsdruck_ungueltig 0;
BA_ "GenSigTimeoutMsg__4CL_C6" SG_ 1192 Bremsdruck_ungueltig 1192;
BA_ "GenSigTimeoutMsg_EPB_C6" SG_ 1192 Bremsdruck_ungueltig 1192;
BA_ "GenSigTimeoutMsg_Gateway_C6" SG_ 1192 Bremsdruck_ungueltig 1192;
BA_ "GenSigAutoGenDsp" SG_ 1192 Bremsentemperatur 0;
BA_ "GenSigAutoGenSnd" SG_ 1192 Bremsentemperatur 0;
BA_ "GenSigSendType" SG_ 1192 Bremsentemperatur 7;
BA_ "NWM-WakeupAllowed" SG_ 1192 Bremsentemperatur 0;
BA_ "GenSigTimeoutMsg_Gateway_C6" SG_ 1192 Bremsentemperatur 1192;
BA_ "GenSigAutoGenDsp" SG_ 1192 Bremslicht_ECD 0;
BA_ "GenSigAutoGenSnd" SG_ 1192 Bremslicht_ECD 0;
BA_ "GenSigSendType" SG_ 1192 Bremslicht_ECD 7;
BA_ "NWM-WakeupAllowed" SG_ 1192 Bremslicht_ECD 0;
BA_ "GenSigTimeoutMsg_Gateway_C6" SG_ 1192 Bremslicht_ECD 1192;
BA_ "GenSigAutoGenDsp" SG_ 1192 BZ_Bremse5 0;
BA_ "GenSigAutoGenSnd" SG_ 1192 BZ_Bremse5 0;
BA_ "GenSigSendType" SG_ 1192 BZ_Bremse5 7;
BA_ "NWM-WakeupAllowed" SG_ 1192 BZ_Bremse5 0;
BA_ "GenSigTimeoutMsg__4CL_C6" SG_ 1192 BZ_Bremse5 1192;
BA_ "GenSigTimeoutMsg_EPB_C6" SG_ 1192 BZ_Bremse5 1192;
BA_ "GenSigTimeoutMsg_Gateway_C6" SG_ 1192 BZ_Bremse5 1192;
BA_ "GenSigAutoGenDsp" SG_ 1192 CHK_Bremse5 0;
BA_ "GenSigAutoGenSnd" SG_ 1192 CHK_Bremse5 0;
BA_ "GenSigSendType" SG_ 1192 CHK_Bremse5 7;
BA_ "NWM-WakeupAllowed" SG_ 1192 CHK_Bremse5 0;
BA_ "GenSigTimeoutMsg__4CL_C6" SG_ 1192 CHK_Bremse5 1192;
BA_ "GenSigTimeoutMsg_EPB_C6" SG_ 1192 CHK_Bremse5 1192;
BA_ "GenSigTimeoutMsg_Gateway_C6" SG_ 1192 CHK_Bremse5 1192;
BA_ "GenSigAutoGenDsp" SG_ 1192 FStatus_Anfahrhilfe 0;
BA_ "GenSigAutoGenSnd" SG_ 1192 FStatus_Anfahrhilfe 0;
BA_ "GenSigSendType" SG_ 1192 FStatus_Anfahrhilfe 7;
BA_ "NWM-WakeupAllowed" SG_ 1192 FStatus_Anfahrhilfe 0;
BA_ "GenSigTimeoutMsg_EPB_C6" SG_ 1192 FStatus_Anfahrhilfe 1192;
BA_ "GenSigTimeoutMsg_Gateway_C6" SG_ 1192 FStatus_Anfahrhilfe 1192;
BA_ "GenSigAutoGenDsp" SG_ 1192 Geschwindigkeitsueberwachung 1;
BA_ "GenSigAutoGenSnd" SG_ 1192 Geschwindigkeitsueberwachung 1;
BA_ "GenSigSendType" SG_ 1192 Geschwindigkeitsueberwachung 7;
BA_ "NWM-WakeupAllowed" SG_ 1192 Geschwindigkeitsueberwachung 0;
BA_ "GenSigTimeoutMsg_Gateway_C6" SG_ 1192 Geschwindigkeitsueberwachung 1192;
BA_ "GenSigAutoGenDsp" SG_ 1192 Giergeschwindigkeit 0;
BA_ "GenSigAutoGenSnd" SG_ 1192 Giergeschwindigkeit 0;
BA_ "GenSigSendType" SG_ 1192 Giergeschwindigkeit 7;
BA_ "NWM-WakeupAllowed" SG_ 1192 Giergeschwindigkeit 0;
BA_ "GenSigTimeoutMsg_Gateway_C6" SG_ 1192 Giergeschwindigkeit 1192;
BA_ "GenSigAutoGenDsp" SG_ 1192 Gierrate_ungueltig 0;
BA_ "GenSigAutoGenSnd" SG_ 1192 Gierrate_ungueltig 0;
BA_ "GenSigSendType" SG_ 1192 Gierrate_ungueltig 7;
BA_ "GenSigStartValue" SG_ 1192 Gierrate_ungueltig 1;
BA_ "NWM-WakeupAllowed" SG_ 1192 Gierrate_ungueltig 0;
BA_ "GenSigTimeoutMsg_Gateway_C6" SG_ 1192 Gierrate_ungueltig 1192;
BA_ "GenSigAutoGenDsp" SG_ 1192 Notfallblinken 1;
BA_ "GenSigAutoGenSnd" SG_ 1192 Notfallblinken 1;
BA_ "GenSigSendType" SG_ 1192 Notfallblinken 7;
BA_ "NWM-WakeupAllowed" SG_ 1192 Notfallblinken 0;
BA_ "GenSigTimeoutMsg_Gateway_C6" SG_ 1192 Notfallblinken 1192;
BA_ "GenSigAutoGenDsp" SG_ 1192 Reifentoleranzabgleich_VR 0;
BA_ "GenSigAutoGenSnd" SG_ 1192 Reifentoleranzabgleich_VR 0;
BA_ "GenSigSendType" SG_ 1192 Reifentoleranzabgleich_VR 7;
BA_ "GenSigStartValue" SG_ 1192 Reifentoleranzabgleich_VR 254;
BA_ "NWM-WakeupAllowed" SG_ 1192 Reifentoleranzabgleich_VR 0;
BA_ "GenSigTimeoutMsg_Gateway_C6" SG_ 1192 Reifentoleranzabgleich_VR 1192;
BA_ "GenSigAutoGenDsp" SG_ 1192 Rueckfallebene_ECD 1;
BA_ "GenSigAutoGenSnd" SG_ 1192 Rueckfallebene_ECD 1;
BA_ "GenSigSendType" SG_ 1192 Rueckfallebene_ECD 7;
BA_ "NWM-WakeupAllowed" SG_ 1192 Rueckfallebene_ECD 0;
BA_ "GenSigTimeoutMsg_Gateway_C6" SG_ 1192 Rueckfallebene_ECD 1192;
BA_ "GenSigAutoGenDsp" SG_ 1192 Signum_Bremsdruck 0;
BA_ "GenSigAutoGenSnd" SG_ 1192 Signum_Bremsdruck 0;
BA_ "GenSigSendType" SG_ 1192 Signum_Bremsdruck 7;
BA_ "NWM-WakeupAllowed" SG_ 1192 Signum_Bremsdruck 0;
BA_ "GenSigTimeoutMsg__4CL_C6" SG_ 1192 Signum_Bremsdruck 1192;
BA_ "GenSigTimeoutMsg_Gateway_C6" SG_ 1192 Signum_Bremsdruck 1192;
BA_ "GenSigAutoGenDsp" SG_ 1192 Signum_Giergeschwindigkeit 0;
BA_ "GenSigAutoGenSnd" SG_ 1192 Signum_Giergeschwindigkeit 0;
BA_ "GenSigSendType" SG_ 1192 Signum_Giergeschwindigkeit 7;
BA_ "NWM-WakeupAllowed" SG_ 1192 Signum_Giergeschwindigkeit 0;
BA_ "GenSigTimeoutMsg_Gateway_C6" SG_ 1192 Signum_Giergeschwindigkeit 1192;
BA_ "GenSigAutoGenDsp" SG_ 1192 Status_Bremsdruck_ESP_System 0;
BA_ "GenSigAutoGenSnd" SG_ 1192 Status_Bremsdruck_ESP_System 0;
BA_ "GenSigSendType" SG_ 1192 Status_Bremsdruck_ESP_System 7;
BA_ "NWM-WakeupAllowed" SG_ 1192 Status_Bremsdruck_ESP_System 0;
BA_ "GenSigTimeoutMsg_Gateway_C6" SG_ 1192 Status_Bremsdruck_ESP_System 1192;
BA_ "GenSigAutoGenDsp" SG_ 1192 Stillstandsflag 0;
BA_ "GenSigAutoGenSnd" SG_ 1192 Stillstandsflag 0;
BA_ "GenSigSendType" SG_ 1192 Stillstandsflag 7;
BA_ "NWM-WakeupAllowed" SG_ 1192 Stillstandsflag 0;
BA_ "GenSigTimeoutMsg__4CL_C6" SG_ 1192 Stillstandsflag 1192;
BA_ "GenSigTimeoutMsg_EPB_C6" SG_ 1192 Stillstandsflag 1192;
BA_ "GenSigTimeoutMsg_Gateway_C6" SG_ 1192 Stillstandsflag 1192;
BA_ "GenSigAutoGenDsp" SG_ 1192 TSP_aktiv 1;
BA_ "GenSigAutoGenSnd" SG_ 1192 TSP_aktiv 1;
BA_ "GenSigSendType" SG_ 1192 TSP_aktiv 7;
BA_ "NWM-WakeupAllowed" SG_ 1192 TSP_aktiv 0;
BA_ "GenSigTimeoutMsg_Gateway_C6" SG_ 1192 TSP_aktiv 1192;
BA_ "GenSigAutoGenDsp" SG_ 428 Aktives_Bremssystem 1;
BA_ "GenSigAutoGenSnd" SG_ 428 Aktives_Bremssystem 1;
BA_ "GenSigSendType" SG_ 428 Aktives_Bremssystem 7;
BA_ "NWM-WakeupAllowed" SG_ 428 Aktives_Bremssystem 0;
BA_ "GenSigTimeoutMsg_Gateway_C6" SG_ 428 Aktives_Bremssystem 428;
BA_ "GenSigAutoGenDsp" SG_ 428 AWV1_Parametersatz_HBA 1;
BA_ "GenSigAutoGenSnd" SG_ 428 AWV1_Parametersatz_HBA 1;
BA_ "GenSigSendType" SG_ 428 AWV1_Parametersatz_HBA 7;
BA_ "NWM-WakeupAllowed" SG_ 428 AWV1_Parametersatz_HBA 0;
BA_ "GenSigTimeoutMsg_Gateway_C6" SG_ 428 AWV1_Parametersatz_HBA 428;
BA_ "GenSigAutoGenDsp" SG_ 428 BZ_Bremse8 0;
BA_ "GenSigAutoGenSnd" SG_ 428 BZ_Bremse8 0;
BA_ "GenSigSendType" SG_ 428 BZ_Bremse8 7;
BA_ "NWM-WakeupAllowed" SG_ 428 BZ_Bremse8 0;
BA_ "GenSigTimeoutMsg_DME_EDC16CP3000" SG_ 428 BZ_Bremse8 428;
BA_ "GenSigTimeoutMsg_DME_ME7_MED9_C6" SG_ 428 BZ_Bremse8 428;
BA_ "GenSigTimeoutMsg_DME_SIMOS6_C6" SG_ 428 BZ_Bremse8 428;
BA_ "GenSigTimeoutMsg_EPB_C6" SG_ 428 BZ_Bremse8 428;
BA_ "GenSigTimeoutMsg_Gateway_C6" SG_ 428 BZ_Bremse8 428;
BA_ "GenSigAutoGenDsp" SG_ 428 CHK_Bremse8 0;
BA_ "GenSigAutoGenSnd" SG_ 428 CHK_Bremse8 0;
BA_ "GenSigSendType" SG_ 428 CHK_Bremse8 7;
BA_ "NWM-WakeupAllowed" SG_ 428 CHK_Bremse8 0;
BA_ "GenSigTimeoutMsg_DME_EDC16CP3000" SG_ 428 CHK_Bremse8 428;
BA_ "GenSigTimeoutMsg_DME_ME7_MED9_C6" SG_ 428 CHK_Bremse8 428;
BA_ "GenSigTimeoutMsg_DME_SIMOS6_C6" SG_ 428 CHK_Bremse8 428;
BA_ "GenSigTimeoutMsg_EPB_C6" SG_ 428 CHK_Bremse8 428;
BA_ "GenSigTimeoutMsg_Gateway_C6" SG_ 428 CHK_Bremse8 428;
BA_ "GenSigAutoGenDsp" SG_ 428 EPB_Botschaft_plausibel 0;
BA_ "GenSigAutoGenSnd" SG_ 428 EPB_Botschaft_plausibel 0;
BA_ "GenSigSendType" SG_ 428 EPB_Botschaft_plausibel 7;
BA_ "NWM-WakeupAllowed" SG_ 428 EPB_Botschaft_plausibel 0;
BA_ "GenSigTimeoutMsg_EPB_C6" SG_ 428 EPB_Botschaft_plausibel 428;
BA_ "GenSigTimeoutMsg_Gateway_C6" SG_ 428 EPB_Botschaft_plausibel 428;
BA_ "GenSigAutoGenDsp" SG_ 428 EPB_Verzoegerung_verfuegbar 0;
BA_ "GenSigAutoGenSnd" SG_ 428 EPB_Verzoegerung_verfuegbar 0;
BA_ "GenSigSendType" SG_ 428 EPB_Verzoegerung_verfuegbar 7;
BA_ "NWM-WakeupAllowed" SG_ 428 EPB_Verzoegerung_verfuegbar 0;
BA_ "GenSigTimeoutMsg_EPB_C6" SG_ 428 EPB_Verzoegerung_verfuegbar 428;
BA_ "GenSigTimeoutMsg_Gateway_C6" SG_ 428 EPB_Verzoegerung_verfuegbar 428;
BA_ "GenSigAutoGenDsp" SG_ 428 Fahrer_bremst 1;
BA_ "GenSigAutoGenSnd" SG_ 428 Fahrer_bremst 1;
BA_ "GenSigSendType" SG_ 428 Fahrer_bremst 7;
BA_ "NWM-WakeupAllowed" SG_ 428 Fahrer_bremst 0;
BA_ "GenSigTimeoutMsg_Gateway_C6" SG_ 428 Fahrer_bremst 428;
BA_ "GenSigAutoGenDsp" SG_ 428 Konsistenz_ACC_Botschaft 0;
BA_ "GenSigAutoGenSnd" SG_ 428 Konsistenz_ACC_Botschaft 0;
BA_ "GenSigSendType" SG_ 428 Konsistenz_ACC_Botschaft 7;
BA_ "NWM-WakeupAllowed" SG_ 428 Konsistenz_ACC_Botschaft 0;
BA_ "GenSigTimeoutMsg_DME_ME7_MED9_C6" SG_ 428 Konsistenz_ACC_Botschaft 428;
BA_ "GenSigTimeoutMsg_DME_SIMOS6_C6" SG_ 428 Konsistenz_ACC_Botschaft 428;
BA_ "GenSigTimeoutMsg_Gateway_C6" SG_ 428 Konsistenz_ACC_Botschaft 428;
BA_ "GenSigAutoGenDsp" SG_ 428 Laengsbeschleunigung 0;
BA_ "GenSigAutoGenSnd" SG_ 428 Laengsbeschleunigung 0;
BA_ "GenSigSendType" SG_ 428 Laengsbeschleunigung 7;
BA_ "GenSigStartValue" SG_ 428 Laengsbeschleunigung 512;
BA_ "NWM-WakeupAllowed" SG_ 428 Laengsbeschleunigung 0;
BA_ "GenSigTimeoutMsg_DME_SIMOS6_C6" SG_ 428 Laengsbeschleunigung 428;
BA_ "GenSigTimeoutMsg_Gateway_C6" SG_ 428 Laengsbeschleunigung 428;
BA_ "GenSigAutoGenDsp" SG_ 428 QBit_Laengsbeschleunigung 0;
BA_ "GenSigAutoGenSnd" SG_ 428 QBit_Laengsbeschleunigung 0;
BA_ "GenSigSendType" SG_ 428 QBit_Laengsbeschleunigung 7;
BA_ "NWM-WakeupAllowed" SG_ 428 QBit_Laengsbeschleunigung 0;
BA_ "GenSigTimeoutMsg_Gateway_C6" SG_ 428 QBit_Laengsbeschleunigung 428;
BA_ "GenSigAutoGenDsp" SG_ 428 Quattroantrieb 0;
BA_ "GenSigAutoGenSnd" SG_ 428 Quattroantrieb 0;
BA_ "GenSigSendType" SG_ 428 Quattroantrieb 7;
BA_ "NWM-WakeupAllowed" SG_ 428 Quattroantrieb 0;
BA_ "GenSigTimeoutMsg_Gateway_C6" SG_ 428 Quattroantrieb 428;
BA_ "GenSigAutoGenDsp" SG_ 428 Reifentoleranzabgleich_HL 0;
BA_ "GenSigAutoGenSnd" SG_ 428 Reifentoleranzabgleich_HL 0;
BA_ "GenSigSendType" SG_ 428 Reifentoleranzabgleich_HL 7;
BA_ "GenSigStartValue" SG_ 428 Reifentoleranzabgleich_HL 254;
BA_ "NWM-WakeupAllowed" SG_ 428 Reifentoleranzabgleich_HL 0;
BA_ "GenSigTimeoutMsg_Gateway_C6" SG_ 428 Reifentoleranzabgleich_HL 428;
BA_ "GenSigAutoGenDsp" SG_ 428 Reifentoleranzabgleich_HR 0;
BA_ "GenSigAutoGenSnd" SG_ 428 Reifentoleranzabgleich_HR 0;
BA_ "GenSigSendType" SG_ 428 Reifentoleranzabgleich_HR 7;
BA_ "GenSigStartValue" SG_ 428 Reifentoleranzabgleich_HR 254;
BA_ "NWM-WakeupAllowed" SG_ 428 Reifentoleranzabgleich_HR 0;
BA_ "GenSigTimeoutMsg_Gateway_C6" SG_ 428 Reifentoleranzabgleich_HR 428;
BA_ "GenSigAutoGenDsp" SG_ 428 Status_aktives_Bremssystem 1;
BA_ "GenSigAutoGenSnd" SG_ 428 Status_aktives_Bremssystem 1;
BA_ "GenSigSendType" SG_ 428 Status_aktives_Bremssystem 7;
BA_ "NWM-WakeupAllowed" SG_ 428 Status_aktives_Bremssystem 0;
BA_ "GenSigTimeoutMsg_Gateway_C6" SG_ 428 Status_aktives_Bremssystem 428;
BA_ "GenSigAutoGenDsp" SG_ 428 Status_BLS 0;
BA_ "GenSigAutoGenSnd" SG_ 428 Status_BLS 0;
BA_ "GenSigSendType" SG_ 428 Status_BLS 7;
BA_ "NWM-WakeupAllowed" SG_ 428 Status_BLS 0;
BA_ "GenSigTimeoutMsg_DME_EDC16CP3000" SG_ 428 Status_BLS 428;
BA_ "GenSigTimeoutMsg_DME_ME7_MED9_C6" SG_ 428 Status_BLS 428;
BA_ "GenSigTimeoutMsg_DME_SIMOS6_C6" SG_ 428 Status_BLS 428;
BA_ "GenSigTimeoutMsg_Gateway_C6" SG_ 428 Status_BLS 428;
BA_ "GenSigAutoGenDsp" SG_ 428 Status_Bremsdruck 0;
BA_ "GenSigAutoGenSnd" SG_ 428 Status_Bremsdruck 0;
BA_ "GenSigSendType" SG_ 428 Status_Bremsdruck 7;
BA_ "NWM-WakeupAllowed" SG_ 428 Status_Bremsdruck 0;
BA_ "GenSigTimeoutMsg_DME_ME7_MED9_C6" SG_ 428 Status_Bremsdruck 428;
BA_ "GenSigTimeoutMsg_EPB_C6" SG_ 428 Status_Bremsdruck 428;
BA_ "GenSigTimeoutMsg_Gateway_C6" SG_ 428 Status_Bremsdruck 428;
BA_ "GenSigAutoGenDsp" SG_ 428 Status_Bremse_ACC_Anf 0;
BA_ "GenSigAutoGenSnd" SG_ 428 Status_Bremse_ACC_Anf 0;
BA_ "GenSigSendType" SG_ 428 Status_Bremse_ACC_Anf 7;
BA_ "NWM-WakeupAllowed" SG_ 428 Status_Bremse_ACC_Anf 0;
BA_ "GenSigTimeoutMsg_DME_SIMOS6_C6" SG_ 428 Status_Bremse_ACC_Anf 428;
BA_ "GenSigTimeoutMsg_Gateway_C6" SG_ 428 Status_Bremse_ACC_Anf 428;
BA_ "GenSigAutoGenDsp" SG_ 428 Status_Bremsentemperatur 0;
BA_ "GenSigAutoGenSnd" SG_ 428 Status_Bremsentemperatur 0;
BA_ "GenSigSendType" SG_ 428 Status_Bremsentemperatur 7;
BA_ "NWM-WakeupAllowed" SG_ 428 Status_Bremsentemperatur 0;
BA_ "GenSigTimeoutMsg_DME_EDC16CP3000" SG_ 428 Status_Bremsentemperatur 428;
BA_ "GenSigTimeoutMsg_DME_ME7_MED9_C6" SG_ 428 Status_Bremsentemperatur 428;
BA_ "GenSigTimeoutMsg_DME_SIMOS6_C6" SG_ 428 Status_Bremsentemperatur 428;
BA_ "GenSigTimeoutMsg_Gateway_C6" SG_ 428 Status_Bremsentemperatur 428;
BA_ "GenSigAutoGenDsp" SG_ 428 Status_HW_BLS_Ausgang 1;
BA_ "GenSigAutoGenSnd" SG_ 428 Status_HW_BLS_Ausgang 1;
BA_ "GenSigSendType" SG_ 428 Status_HW_BLS_Ausgang 7;
BA_ "NWM-WakeupAllowed" SG_ 428 Status_HW_BLS_Ausgang 0;
BA_ "GenSigTimeoutMsg_Gateway_C6" SG_ 428 Status_HW_BLS_Ausgang 428;
BA_ "GenSigAutoGenDsp" SG_ 428 Status_Verzoegerungsregler 0;
BA_ "GenSigAutoGenSnd" SG_ 428 Status_Verzoegerungsregler 0;
BA_ "GenSigSendType" SG_ 428 Status_Verzoegerungsregler 7;
BA_ "NWM-WakeupAllowed" SG_ 428 Status_Verzoegerungsregler 0;
BA_ "GenSigTimeoutMsg_DME_EDC16CP3000" SG_ 428 Status_Verzoegerungsregler 428;
BA_ "GenSigTimeoutMsg_DME_ME7_MED9_C6" SG_ 428 Status_Verzoegerungsregler 428;
BA_ "GenSigTimeoutMsg_DME_SIMOS6_C6" SG_ 428 Status_Verzoegerungsregler 428;
BA_ "GenSigTimeoutMsg_Gateway_C6" SG_ 428 Status_Verzoegerungsregler 428;
BA_ "GenSigAutoGenDsp" SG_ 428 Verzoegerung_EPB_aktiviert 0;
BA_ "GenSigAutoGenSnd" SG_ 428 Verzoegerung_EPB_aktiviert 0;
BA_ "GenSigSendType" SG_ 428 Verzoegerung_EPB_aktiviert 7;
BA_ "NWM-WakeupAllowed" SG_ 428 Verzoegerung_EPB_aktiviert 0;
BA_ "GenSigTimeoutMsg_DME_EDC16CP3000" SG_ 428 Verzoegerung_EPB_aktiviert 428;
BA_ "GenSigTimeoutMsg_DME_ME7_MED9_C6" SG_ 428 Verzoegerung_EPB_aktiviert 428;
BA_ "GenSigTimeoutMsg_DME_SIMOS6_C6" SG_ 428 Verzoegerung_EPB_aktiviert 428;
BA_ "GenSigTimeoutMsg_EPB_C6" SG_ 428 Verzoegerung_EPB_aktiviert 428;
BA_ "GenSigTimeoutMsg_Gateway_C6" SG_ 428 Verzoegerung_EPB_aktiviert 428;
BA_ "GenSigAutoGenDsp" SG_ 1524 Antriebsvariante 0;
BA_ "GenSigAutoGenSnd" SG_ 1524 Antriebsvariante 0;
BA_ "GenSigSendType" SG_ 1524 Antriebsvariante 7;
BA_ "NWM-WakeupAllowed" SG_ 1524 Antriebsvariante 0;
BA_ "GenSigTimeoutMsg_ESP8_C6" SG_ 1524 Antriebsvariante 1524;
BA_ "GenSigAutoGenDsp" SG_ 1524 Bremsenvariante 0;
BA_ "GenSigAutoGenSnd" SG_ 1524 Bremsenvariante 0;
BA_ "GenSigSendType" SG_ 1524 Bremsenvariante 7;
BA_ "NWM-WakeupAllowed" SG_ 1524 Bremsenvariante 0;
BA_ "GenSigTimeoutMsg_ESP8_C6" SG_ 1524 Bremsenvariante 1524;
BA_ "GenSigAutoGenDsp" SG_ 1524 CHK_Bremse_Codierinfo 0;
BA_ "GenSigAutoGenSnd" SG_ 1524 CHK_Bremse_Codierinfo 0;
BA_ "GenSigSendType" SG_ 1524 CHK_Bremse_Codierinfo 7;
BA_ "NWM-WakeupAllowed" SG_ 1524 CHK_Bremse_Codierinfo 0;
BA_ "GenSigTimeoutMsg_ESP8_C6" SG_ 1524 CHK_Bremse_Codierinfo 1524;
BA_ "GenSigAutoGenDsp" SG_ 1518 Controller_ID 0;
BA_ "GenSigAutoGenSnd" SG_ 1518 Controller_ID 0;
BA_ "GenSigSendType" SG_ 1518 Controller_ID 7;
BA_ "NWM-WakeupAllowed" SG_ 1518 Controller_ID 0;
BA_ "GenSigTimeoutMsg_Gateway_C6" SG_ 1518 Controller_ID 1518;
BA_ "GenSigAutoGenDsp" SG_ 1518 Data_Byte_1 0;
BA_ "GenSigAutoGenSnd" SG_ 1518 Data_Byte_1 0;
BA_ "GenSigSendType" SG_ 1518 Data_Byte_1 7;
BA_ "NWM-WakeupAllowed" SG_ 1518 Data_Byte_1 0;
BA_ "GenSigTimeoutMsg_Gateway_C6" SG_ 1518 Data_Byte_1 1518;
BA_ "GenSigAutoGenDsp" SG_ 1518 Data_Byte_2 0;
BA_ "GenSigAutoGenSnd" SG_ 1518 Data_Byte_2 0;
BA_ "GenSigSendType" SG_ 1518 Data_Byte_2 7;
BA_ "NWM-WakeupAllowed" SG_ 1518 Data_Byte_2 0;
BA_ "GenSigTimeoutMsg_Gateway_C6" SG_ 1518 Data_Byte_2 1518;
BA_ "GenSigAutoGenDsp" SG_ 1518 Data_Byte_3 0;
BA_ "GenSigAutoGenSnd" SG_ 1518 Data_Byte_3 0;
BA_ "GenSigSendType" SG_ 1518 Data_Byte_3 7;
BA_ "NWM-WakeupAllowed" SG_ 1518 Data_Byte_3 0;
BA_ "GenSigTimeoutMsg_Gateway_C6" SG_ 1518 Data_Byte_3 1518;
BA_ "GenSigAutoGenDsp" SG_ 1518 Data_Byte_4 0;
BA_ "GenSigAutoGenSnd" SG_ 1518 Data_Byte_4 0;
BA_ "GenSigSendType" SG_ 1518 Data_Byte_4 7;
BA_ "NWM-WakeupAllowed" SG_ 1518 Data_Byte_4 0;
BA_ "GenSigTimeoutMsg_Gateway_C6" SG_ 1518 Data_Byte_4 1518;
BA_ "GenSigAutoGenDsp" SG_ 1518 Data_Byte_5 0;
BA_ "GenSigAutoGenSnd" SG_ 1518 Data_Byte_5 0;
BA_ "GenSigSendType" SG_ 1518 Data_Byte_5 7;
BA_ "NWM-WakeupAllowed" SG_ 1518 Data_Byte_5 0;
BA_ "GenSigTimeoutMsg_Gateway_C6" SG_ 1518 Data_Byte_5 1518;
BA_ "GenSigAutoGenDsp" SG_ 1518 Function_ID 0;
BA_ "GenSigAutoGenSnd" SG_ 1518 Function_ID 0;
BA_ "GenSigSendType" SG_ 1518 Function_ID 7;
BA_ "NWM-WakeupAllowed" SG_ 1518 Function_ID 0;
BA_ "GenSigTimeoutMsg_Gateway_C6" SG_ 1518 Function_ID 1518;
BA_ "GenSigAutoGenDsp" SG_ 1518 Module_ID 0;
BA_ "GenSigAutoGenSnd" SG_ 1518 Module_ID 0;
BA_ "GenSigSendType" SG_ 1518 Module_ID 7;
BA_ "NWM-WakeupAllowed" SG_ 1518 Module_ID 0;
BA_ "GenSigTimeoutMsg_Gateway_C6" SG_ 1518 Module_ID 1518;
BA_ "GenSigAutoGenDsp" SG_ 1518 OpCode 0;
BA_ "GenSigAutoGenSnd" SG_ 1518 OpCode 0;
BA_ "GenSigSendType" SG_ 1518 OpCode 7;
BA_ "NWM-WakeupAllowed" SG_ 1518 OpCode 0;
BA_ "GenSigTimeoutMsg_Gateway_C6" SG_ 1518 OpCode 1518;
BA_ "GenSigAutoGenDsp" SG_ 1518 Update_Indicator 0;
BA_ "GenSigAutoGenSnd" SG_ 1518 Update_Indicator 0;
BA_ "GenSigSendType" SG_ 1518 Update_Indicator 7;
BA_ "NWM-WakeupAllowed" SG_ 1518 Update_Indicator 0;
BA_ "GenSigTimeoutMsg_Gateway_C6" SG_ 1518 Update_Indicator 1518;
BA_ "GenSigAutoGenDsp" SG_ 1516 Controller_ID 0;
BA_ "GenSigAutoGenSnd" SG_ 1516 Controller_ID 0;
BA_ "GenSigSendType" SG_ 1516 Controller_ID 7;
BA_ "NWM-WakeupAllowed" SG_ 1516 Controller_ID 0;
BA_ "GenSigTimeoutMsg__4CL_C6" SG_ 1516 Controller_ID 1516;
BA_ "GenSigAutoGenDsp" SG_ 1516 Data_Byte_1 0;
BA_ "GenSigAutoGenSnd" SG_ 1516 Data_Byte_1 0;
BA_ "GenSigSendType" SG_ 1516 Data_Byte_1 7;
BA_ "NWM-WakeupAllowed" SG_ 1516 Data_Byte_1 0;
BA_ "GenSigTimeoutMsg__4CL_C6" SG_ 1516 Data_Byte_1 1516;
BA_ "GenSigAutoGenDsp" SG_ 1516 Data_Byte_2 0;
BA_ "GenSigAutoGenSnd" SG_ 1516 Data_Byte_2 0;
BA_ "GenSigSendType" SG_ 1516 Data_Byte_2 7;
BA_ "NWM-WakeupAllowed" SG_ 1516 Data_Byte_2 0;
BA_ "GenSigTimeoutMsg__4CL_C6" SG_ 1516 Data_Byte_2 1516;
BA_ "GenSigAutoGenDsp" SG_ 1516 Data_Byte_3 0;
BA_ "GenSigAutoGenSnd" SG_ 1516 Data_Byte_3 0;
BA_ "GenSigSendType" SG_ 1516 Data_Byte_3 7;
BA_ "NWM-WakeupAllowed" SG_ 1516 Data_Byte_3 0;
BA_ "GenSigTimeoutMsg__4CL_C6" SG_ 1516 Data_Byte_3 1516;
BA_ "GenSigAutoGenDsp" SG_ 1516 Data_Byte_4 0;
BA_ "GenSigAutoGenSnd" SG_ 1516 Data_Byte_4 0;
BA_ "GenSigSendType" SG_ 1516 Data_Byte_4 7;
BA_ "NWM-WakeupAllowed" SG_ 1516 Data_Byte_4 0;
BA_ "GenSigTimeoutMsg__4CL_C6" SG_ 1516 Data_Byte_4 1516;
BA_ "GenSigAutoGenDsp" SG_ 1516 Data_Byte_5 0;
BA_ "GenSigAutoGenSnd" SG_ 1516 Data_Byte_5 0;
BA_ "GenSigSendType" SG_ 1516 Data_Byte_5 7;
BA_ "NWM-WakeupAllowed" SG_ 1516 Data_Byte_5 0;
BA_ "GenSigTimeoutMsg__4CL_C6" SG_ 1516 Data_Byte_5 1516;
BA_ "GenSigAutoGenDsp" SG_ 1516 Function_ID 0;
BA_ "GenSigAutoGenSnd" SG_ 1516 Function_ID 0;
BA_ "GenSigSendType" SG_ 1516 Function_ID 7;
BA_ "NWM-WakeupAllowed" SG_ 1516 Function_ID 0;
BA_ "GenSigTimeoutMsg__4CL_C6" SG_ 1516 Function_ID 1516;
BA_ "GenSigAutoGenDsp" SG_ 1516 Module_ID 0;
BA_ "GenSigAutoGenSnd" SG_ 1516 Module_ID 0;
BA_ "GenSigSendType" SG_ 1516 Module_ID 7;
BA_ "NWM-WakeupAllowed" SG_ 1516 Module_ID 0;
BA_ "GenSigTimeoutMsg__4CL_C6" SG_ 1516 Module_ID 1516;
BA_ "GenSigAutoGenDsp" SG_ 1516 OpCode 0;
BA_ "GenSigAutoGenSnd" SG_ 1516 OpCode 0;
BA_ "GenSigSendType" SG_ 1516 OpCode 7;
BA_ "NWM-WakeupAllowed" SG_ 1516 OpCode 0;
BA_ "GenSigTimeoutMsg__4CL_C6" SG_ 1516 OpCode 1516;
BA_ "GenSigAutoGenDsp" SG_ 1516 Update_Indicator 0;
BA_ "GenSigAutoGenSnd" SG_ 1516 Update_Indicator 0;
BA_ "GenSigSendType" SG_ 1516 Update_Indicator 7;
BA_ "NWM-WakeupAllowed" SG_ 1516 Update_Indicator 0;
BA_ "GenSigTimeoutMsg__4CL_C6" SG_ 1516 Update_Indicator 1516;
BA_ "GenSigAutoGenDsp" SG_ 2000 Datum_Jahr 0;
BA_ "GenSigAutoGenSnd" SG_ 2000 Datum_Jahr 0;
BA_ "GenSigSendType" SG_ 2000 Datum_Jahr 7;
BA_ "NWM-WakeupAllowed" SG_ 2000 Datum_Jahr 0;
BA_ "GenSigTimeoutMsg__4CL_C6" SG_ 2000 Datum_Jahr 2000;
BA_ "GenSigTimeoutMsg__6HP_C6" SG_ 2000 Datum_Jahr 2000;
BA_ "GenSigTimeoutMsg_DME_EDC16CP3000" SG_ 2000 Datum_Jahr 2000;
BA_ "GenSigTimeoutMsg_EPB_C6" SG_ 2000 Datum_Jahr 2000;
BA_ "GenSigTimeoutMsg_ESP8_C6" SG_ 2000 Datum_Jahr 2000;
BA_ "GenSigTimeoutMsg_LWR_AFS_C6" SG_ 2000 Datum_Jahr 2000;
BA_ "GenSigAutoGenDsp" SG_ 2000 Datum_Monat 0;
BA_ "GenSigAutoGenSnd" SG_ 2000 Datum_Monat 0;
BA_ "GenSigSendType" SG_ 2000 Datum_Monat 7;
BA_ "NWM-WakeupAllowed" SG_ 2000 Datum_Monat 0;
BA_ "GenSigTimeoutMsg__4CL_C6" SG_ 2000 Datum_Monat 2000;
BA_ "GenSigTimeoutMsg__6HP_C6" SG_ 2000 Datum_Monat 2000;
BA_ "GenSigTimeoutMsg_DME_EDC16CP3000" SG_ 2000 Datum_Monat 2000;
BA_ "GenSigTimeoutMsg_EPB_C6" SG_ 2000 Datum_Monat 2000;
BA_ "GenSigTimeoutMsg_ESP8_C6" SG_ 2000 Datum_Monat 2000;
BA_ "GenSigTimeoutMsg_LWR_AFS_C6" SG_ 2000 Datum_Monat 2000;
BA_ "GenSigAutoGenDsp" SG_ 2000 Datum_Tag 0;
BA_ "GenSigAutoGenSnd" SG_ 2000 Datum_Tag 0;
BA_ "GenSigSendType" SG_ 2000 Datum_Tag 7;
BA_ "NWM-WakeupAllowed" SG_ 2000 Datum_Tag 0;
BA_ "GenSigTimeoutMsg__4CL_C6" SG_ 2000 Datum_Tag 2000;
BA_ "GenSigTimeoutMsg__6HP_C6" SG_ 2000 Datum_Tag 2000;
BA_ "GenSigTimeoutMsg_DME_EDC16CP3000" SG_ 2000 Datum_Tag 2000;
BA_ "GenSigTimeoutMsg_EPB_C6" SG_ 2000 Datum_Tag 2000;
BA_ "GenSigTimeoutMsg_ESP8_C6" SG_ 2000 Datum_Tag 2000;
BA_ "GenSigTimeoutMsg_LWR_AFS_C6" SG_ 2000 Datum_Tag 2000;
BA_ "GenSigAutoGenDsp" SG_ 2000 Kilometerstand 0;
BA_ "GenSigAutoGenSnd" SG_ 2000 Kilometerstand 0;
BA_ "GenSigSendType" SG_ 2000 Kilometerstand 7;
BA_ "NWM-WakeupAllowed" SG_ 2000 Kilometerstand 0;
BA_ "GenSigTimeoutMsg__4CL_C6" SG_ 2000 Kilometerstand 2000;
BA_ "GenSigTimeoutMsg__6HP_C6" SG_ 2000 Kilometerstand 2000;
BA_ "GenSigTimeoutMsg_DME_EDC16CP3000" SG_ 2000 Kilometerstand 2000;
BA_ "GenSigTimeoutMsg_EPB_C6" SG_ 2000 Kilometerstand 2000;
BA_ "GenSigTimeoutMsg_ESP8_C6" SG_ 2000 Kilometerstand 2000;
BA_ "GenSigTimeoutMsg_LWR_AFS_C6" SG_ 2000 Kilometerstand 2000;
BA_ "GenSigAutoGenDsp" SG_ 2000 Kilometerstand_alt 0;
BA_ "GenSigAutoGenSnd" SG_ 2000 Kilometerstand_alt 0;
BA_ "GenSigSendType" SG_ 2000 Kilometerstand_alt 7;
BA_ "NWM-WakeupAllowed" SG_ 2000 Kilometerstand_alt 0;
BA_ "GenSigTimeoutMsg__4CL_C6" SG_ 2000 Kilometerstand_alt 2000;
BA_ "GenSigTimeoutMsg_DME_EDC16CP3000" SG_ 2000 Kilometerstand_alt 2000;
BA_ "GenSigTimeoutMsg_EPB_C6" SG_ 2000 Kilometerstand_alt 2000;
BA_ "GenSigTimeoutMsg_ESP8_C6" SG_ 2000 Kilometerstand_alt 2000;
BA_ "GenSigTimeoutMsg_LWR_AFS_C6" SG_ 2000 Kilometerstand_alt 2000;
BA_ "GenSigAutoGenDsp" SG_ 2000 Time_Indication_Bit 0;
BA_ "GenSigAutoGenSnd" SG_ 2000 Time_Indication_Bit 0;
BA_ "GenSigSendType" SG_ 2000 Time_Indication_Bit 7;
BA_ "NWM-WakeupAllowed" SG_ 2000 Time_Indication_Bit 0;
BA_ "GenSigAutoGenDsp" SG_ 2000 Uhrzeit_Minute 0;
BA_ "GenSigAutoGenSnd" SG_ 2000 Uhrzeit_Minute 0;
BA_ "GenSigSendType" SG_ 2000 Uhrzeit_Minute 7;
BA_ "NWM-WakeupAllowed" SG_ 2000 Uhrzeit_Minute 0;
BA_ "GenSigTimeoutMsg__4CL_C6" SG_ 2000 Uhrzeit_Minute 2000;
BA_ "GenSigTimeoutMsg__6HP_C6" SG_ 2000 Uhrzeit_Minute 2000;
BA_ "GenSigTimeoutMsg_DME_EDC16CP3000" SG_ 2000 Uhrzeit_Minute 2000;
BA_ "GenSigTimeoutMsg_EPB_C6" SG_ 2000 Uhrzeit_Minute 2000;
BA_ "GenSigTimeoutMsg_ESP8_C6" SG_ 2000 Uhrzeit_Minute 2000;
BA_ "GenSigTimeoutMsg_LWR_AFS_C6" SG_ 2000 Uhrzeit_Minute 2000;
BA_ "GenSigAutoGenDsp" SG_ 2000 Uhrzeit_Sekunde 0;
BA_ "GenSigAutoGenSnd" SG_ 2000 Uhrzeit_Sekunde 0;
BA_ "GenSigSendType" SG_ 2000 Uhrzeit_Sekunde 7;
BA_ "NWM-WakeupAllowed" SG_ 2000 Uhrzeit_Sekunde 0;
BA_ "GenSigTimeoutMsg__4CL_C6" SG_ 2000 Uhrzeit_Sekunde 2000;
BA_ "GenSigTimeoutMsg__6HP_C6" SG_ 2000 Uhrzeit_Sekunde 2000;
BA_ "GenSigTimeoutMsg_DME_EDC16CP3000" SG_ 2000 Uhrzeit_Sekunde 2000;
BA_ "GenSigTimeoutMsg_EPB_C6" SG_ 2000 Uhrzeit_Sekunde 2000;
BA_ "GenSigTimeoutMsg_ESP8_C6" SG_ 2000 Uhrzeit_Sekunde 2000;
BA_ "GenSigTimeoutMsg_LWR_AFS_C6" SG_ 2000 Uhrzeit_Sekunde 2000;
BA_ "GenSigAutoGenDsp" SG_ 2000 Uhrzeit_Stunde 0;
BA_ "GenSigAutoGenSnd" SG_ 2000 Uhrzeit_Stunde 0;
BA_ "GenSigSendType" SG_ 2000 Uhrzeit_Stunde 7;
BA_ "NWM-WakeupAllowed" SG_ 2000 Uhrzeit_Stunde 0;
BA_ "GenSigTimeoutMsg__4CL_C6" SG_ 2000 Uhrzeit_Stunde 2000;
BA_ "GenSigTimeoutMsg__6HP_C6" SG_ 2000 Uhrzeit_Stunde 2000;
BA_ "GenSigTimeoutMsg_DME_EDC16CP3000" SG_ 2000 Uhrzeit_Stunde 2000;
BA_ "GenSigTimeoutMsg_EPB_C6" SG_ 2000 Uhrzeit_Stunde 2000;
BA_ "GenSigTimeoutMsg_ESP8_C6" SG_ 2000 Uhrzeit_Stunde 2000;
BA_ "GenSigTimeoutMsg_LWR_AFS_C6" SG_ 2000 Uhrzeit_Stunde 2000;
BA_ "GenSigAutoGenDsp" SG_ 2000 Verlernzaehler 0;
BA_ "GenSigAutoGenSnd" SG_ 2000 Verlernzaehler 0;
BA_ "GenSigSendType" SG_ 2000 Verlernzaehler 7;
BA_ "NWM-WakeupAllowed" SG_ 2000 Verlernzaehler 0;
BA_ "GenSigTimeoutMsg__4CL_C6" SG_ 2000 Verlernzaehler 2000;
BA_ "GenSigTimeoutMsg_EPB_C6" SG_ 2000 Verlernzaehler 2000;
BA_ "GenSigTimeoutMsg_ESP8_C6" SG_ 2000 Verlernzaehler 2000;
BA_ "GenSigTimeoutMsg_LWR_AFS_C6" SG_ 2000 Verlernzaehler 2000;
BA_ "GenSigAutoGenDsp" SG_ 2000 Zeit_alt 0;
BA_ "GenSigAutoGenSnd" SG_ 2000 Zeit_alt 0;
BA_ "GenSigSendType" SG_ 2000 Zeit_alt 7;
BA_ "NWM-WakeupAllowed" SG_ 2000 Zeit_alt 0;
BA_ "GenSigTimeoutMsg__4CL_C6" SG_ 2000 Zeit_alt 2000;
BA_ "GenSigTimeoutMsg_DME_EDC16CP3000" SG_ 2000 Zeit_alt 2000;
BA_ "GenSigTimeoutMsg_EPB_C6" SG_ 2000 Zeit_alt 2000;
BA_ "GenSigTimeoutMsg_ESP8_C6" SG_ 2000 Zeit_alt 2000;
BA_ "GenSigTimeoutMsg_LWR_AFS_C6" SG_ 2000 Zeit_alt 2000;
BA_ "GenSigAutoGenDsp" SG_ 1472 Anforderung_Shift_Lock_Lampe 1;
BA_ "GenSigAutoGenSnd" SG_ 1472 Anforderung_Shift_Lock_Lampe 1;
BA_ "GenSigSendType" SG_ 1472 Anforderung_Shift_Lock_Lampe 7;
BA_ "NWM-WakeupAllowed" SG_ 1472 Anforderung_Shift_Lock_Lampe 0;
BA_ "GenSigTimeoutMsg_Gateway_C6" SG_ 1472 Anforderung_Shift_Lock_Lampe 1472;
BA_ "GenSigAutoGenDsp" SG_ 1472 Auto_Oeffnen_Schliessen_erlaubt 1;
BA_ "GenSigAutoGenSnd" SG_ 1472 Auto_Oeffnen_Schliessen_erlaubt 1;
BA_ "GenSigSendType" SG_ 1472 Auto_Oeffnen_Schliessen_erlaubt 7;
BA_ "NWM-WakeupAllowed" SG_ 1472 Auto_Oeffnen_Schliessen_erlaubt 0;
BA_ "GenSigTimeoutMsg_CVT_C6" SG_ 1472 Auto_Oeffnen_Schliessen_erlaubt 1472;
BA_ "GenSigTimeoutMsg_Gateway_C6" SG_ 1472 Auto_Oeffnen_Schliessen_erlaubt 1472;
BA_ "GenSigAutoGenDsp" SG_ 1472 Bremslicht_dyn_Abbremsung 0;
BA_ "GenSigAutoGenSnd" SG_ 1472 Bremslicht_dyn_Abbremsung 0;
BA_ "GenSigSendType" SG_ 1472 Bremslicht_dyn_Abbremsung 7;
BA_ "NWM-WakeupAllowed" SG_ 1472 Bremslicht_dyn_Abbremsung 0;
BA_ "GenSigTimeoutMsg_Gateway_C6" SG_ 1472 Bremslicht_dyn_Abbremsung 1472;
BA_ "GenSigAutoGenDsp" SG_ 1472 BZ_EPB1 0;
BA_ "GenSigAutoGenSnd" SG_ 1472 BZ_EPB1 0;
BA_ "GenSigSendType" SG_ 1472 BZ_EPB1 7;
BA_ "NWM-WakeupAllowed" SG_ 1472 BZ_EPB1 0;
BA_ "GenSigTimeoutMsg_ESP8_C6" SG_ 1472 BZ_EPB1 1472;
BA_ "GenSigTimeoutMsg_Gateway_C6" SG_ 1472 BZ_EPB1 1472;
BA_ "GenSigAutoGenDsp" SG_ 1472 CHK_EPB1 0;
BA_ "GenSigAutoGenSnd" SG_ 1472 CHK_EPB1 0;
BA_ "GenSigSendType" SG_ 1472 CHK_EPB1 7;
BA_ "NWM-WakeupAllowed" SG_ 1472 CHK_EPB1 0;
BA_ "GenSigTimeoutMsg_ESP8_C6" SG_ 1472 CHK_EPB1 1472;
BA_ "GenSigTimeoutMsg_Gateway_C6" SG_ 1472 CHK_EPB1 1472;
BA_ "GenSigAutoGenDsp" SG_ 1472 Erreichte_Spannkraft 0;
BA_ "GenSigAutoGenSnd" SG_ 1472 Erreichte_Spannkraft 0;
BA_ "GenSigSendType" SG_ 1472 Erreichte_Spannkraft 7;
BA_ "NWM-WakeupAllowed" SG_ 1472 Erreichte_Spannkraft 0;
BA_ "GenSigTimeoutMsg_ESP8_C6" SG_ 1472 Erreichte_Spannkraft 1472;
BA_ "GenSigTimeoutMsg_Gateway_C6" SG_ 1472 Erreichte_Spannkraft 1472;
BA_ "GenSigAutoGenDsp" SG_ 1472 Fehlerlampe_BKL 0;
BA_ "GenSigAutoGenSnd" SG_ 1472 Fehlerlampe_BKL 0;
BA_ "GenSigSendType" SG_ 1472 Fehlerlampe_BKL 7;
BA_ "NWM-WakeupAllowed" SG_ 1472 Fehlerlampe_BKL 0;
BA_ "GenSigTimeoutMsg_Gateway_C6" SG_ 1472 Fehlerlampe_BKL 1472;
BA_ "GenSigAutoGenDsp" SG_ 1472 Fehlerlampe_Gelb_EPB 0;
BA_ "GenSigAutoGenSnd" SG_ 1472 Fehlerlampe_Gelb_EPB 0;
BA_ "GenSigSendType" SG_ 1472 Fehlerlampe_Gelb_EPB 7;
BA_ "NWM-WakeupAllowed" SG_ 1472 Fehlerlampe_Gelb_EPB 0;
BA_ "GenSigTimeoutMsg_Gateway_C6" SG_ 1472 Fehlerlampe_Gelb_EPB 1472;
BA_ "GenSigAutoGenDsp" SG_ 1472 Freig_Verz_anf_EPB 0;
BA_ "GenSigAutoGenSnd" SG_ 1472 Freig_Verz_anf_EPB 0;
BA_ "GenSigSendType" SG_ 1472 Freig_Verz_anf_EPB 7;
BA_ "NWM-WakeupAllowed" SG_ 1472 Freig_Verz_anf_EPB 0;
BA_ "GenSigTimeoutMsg_ESP8_C6" SG_ 1472 Freig_Verz_anf_EPB 1472;
BA_ "GenSigTimeoutMsg_Gateway_C6" SG_ 1472 Freig_Verz_anf_EPB 1472;
BA_ "GenSigAutoGenDsp" SG_ 1472 FSPE_EPB 0;
BA_ "GenSigAutoGenSnd" SG_ 1472 FSPE_EPB 0;
BA_ "GenSigSendType" SG_ 1472 FSPE_EPB 7;
BA_ "NWM-WakeupAllowed" SG_ 1472 FSPE_EPB 0;
BA_ "GenSigTimeoutMsg_Gateway_C6" SG_ 1472 FSPE_EPB 1472;
BA_ "GenSigAutoGenDsp" SG_ 1472 FStatus_EPB 0;
BA_ "GenSigAutoGenSnd" SG_ 1472 FStatus_EPB 0;
BA_ "GenSigSendType" SG_ 1472 FStatus_EPB 7;
BA_ "NWM-WakeupAllowed" SG_ 1472 FStatus_EPB 0;
BA_ "GenSigTimeoutMsg_ESP8_C6" SG_ 1472 FStatus_EPB 1472;
BA_ "GenSigTimeoutMsg_Gateway_C6" SG_ 1472 FStatus_EPB 1472;
BA_ "GenSigAutoGenDsp" SG_ 1472 Funktionslampe_Auto_P 0;
BA_ "GenSigAutoGenSnd" SG_ 1472 Funktionslampe_Auto_P 0;
BA_ "GenSigSendType" SG_ 1472 Funktionslampe_Auto_P 7;
BA_ "NWM-WakeupAllowed" SG_ 1472 Funktionslampe_Auto_P 0;
BA_ "GenSigTimeoutMsg_Gateway_C6" SG_ 1472 Funktionslampe_Auto_P 1472;
BA_ "GenSigAutoGenDsp" SG_ 1472 Funktionslampe_EPB 0;
BA_ "GenSigAutoGenSnd" SG_ 1472 Funktionslampe_EPB 0;
BA_ "GenSigSendType" SG_ 1472 Funktionslampe_EPB 7;
BA_ "NWM-WakeupAllowed" SG_ 1472 Funktionslampe_EPB 0;
BA_ "GenSigTimeoutMsg_Gateway_C6" SG_ 1472 Funktionslampe_EPB 1472;
BA_ "GenSigAutoGenDsp" SG_ 1472 KL15_Status_Info 0;
BA_ "GenSigAutoGenSnd" SG_ 1472 KL15_Status_Info 0;
BA_ "GenSigSendType" SG_ 1472 KL15_Status_Info 7;
BA_ "GenSigStartValue" SG_ 1472 KL15_Status_Info 1;
BA_ "NWM-WakeupAllowed" SG_ 1472 KL15_Status_Info 0;
BA_ "GenSigTimeoutMsg_Gateway_C6" SG_ 1472 KL15_Status_Info 1472;
BA_ "GenSigAutoGenDsp" SG_ 1472 Kupplungsmodulationsbereich 1;
BA_ "GenSigAutoGenSnd" SG_ 1472 Kupplungsmodulationsbereich 1;
BA_ "GenSigSendType" SG_ 1472 Kupplungsmodulationsbereich 7;
BA_ "NWM-WakeupAllowed" SG_ 1472 Kupplungsmodulationsbereich 0;
BA_ "GenSigTimeoutMsg_Gateway_C6" SG_ 1472 Kupplungsmodulationsbereich 1472;
BA_ "GenSigAutoGenDsp" SG_ 1472 Neigungswinkel 0;
BA_ "GenSigAutoGenSnd" SG_ 1472 Neigungswinkel 0;
BA_ "GenSigSendType" SG_ 1472 Neigungswinkel 7;
BA_ "NWM-WakeupAllowed" SG_ 1472 Neigungswinkel 0;
BA_ "GenSigTimeoutMsg__6HP_C6" SG_ 1472 Neigungswinkel 1472;
BA_ "GenSigTimeoutMsg_ESP8_C6" SG_ 1472 Neigungswinkel 1472;
BA_ "GenSigTimeoutMsg_Gateway_C6" SG_ 1472 Neigungswinkel 1472;
BA_ "GenSigAutoGenDsp" SG_ 1472 QBit_Neigungswinkel 1;
BA_ "GenSigAutoGenSnd" SG_ 1472 QBit_Neigungswinkel 1;
BA_ "GenSigSendType" SG_ 1472 QBit_Neigungswinkel 7;
BA_ "NWM-WakeupAllowed" SG_ 1472 QBit_Neigungswinkel 0;
BA_ "GenSigTimeoutMsg_Gateway_C6" SG_ 1472 QBit_Neigungswinkel 1472;
BA_ "GenSigAutoGenDsp" SG_ 1472 Schalterinfo_EPB 0;
BA_ "GenSigAutoGenSnd" SG_ 1472 Schalterinfo_EPB 0;
BA_ "GenSigSendType" SG_ 1472 Schalterinfo_EPB 7;
BA_ "NWM-WakeupAllowed" SG_ 1472 Schalterinfo_EPB 0;
BA_ "GenSigTimeoutMsg_ESP8_C6" SG_ 1472 Schalterinfo_EPB 1472;
BA_ "GenSigTimeoutMsg_Gateway_C6" SG_ 1472 Schalterinfo_EPB 1472;
BA_ "GenSigAutoGenDsp" SG_ 1472 Schalterstatus_EPB 0;
BA_ "GenSigAutoGenSnd" SG_ 1472 Schalterstatus_EPB 0;
BA_ "GenSigSendType" SG_ 1472 Schalterstatus_EPB 7;
BA_ "NWM-WakeupAllowed" SG_ 1472 Schalterstatus_EPB 0;
BA_ "GenSigTimeoutMsg_ESP8_C6" SG_ 1472 Schalterstatus_EPB 1472;
BA_ "GenSigTimeoutMsg_Gateway_C6" SG_ 1472 Schalterstatus_EPB 1472;
BA_ "GenSigAutoGenDsp" SG_ 1472 SIB_EPB 0;
BA_ "GenSigAutoGenSnd" SG_ 1472 SIB_EPB 0;
BA_ "GenSigSendType" SG_ 1472 SIB_EPB 7;
BA_ "NWM-WakeupAllowed" SG_ 1472 SIB_EPB 0;
BA_ "GenSigTimeoutMsg_Gateway_C6" SG_ 1472 SIB_EPB 1472;
BA_ "GenSigAutoGenDsp" SG_ 1472 Status_EPB 0;
BA_ "GenSigAutoGenSnd" SG_ 1472 Status_EPB 0;
BA_ "GenSigSendType" SG_ 1472 Status_EPB 7;
BA_ "NWM-WakeupAllowed" SG_ 1472 Status_EPB 0;
BA_ "GenSigTimeoutMsg_ESP8_C6" SG_ 1472 Status_EPB 1472;
BA_ "GenSigTimeoutMsg_Gateway_C6" SG_ 1472 Status_EPB 1472;
BA_ "GenSigAutoGenDsp" SG_ 1472 Status_NWG 0;
BA_ "GenSigAutoGenSnd" SG_ 1472 Status_NWG 0;
BA_ "GenSigSendType" SG_ 1472 Status_NWG 7;
BA_ "NWM-WakeupAllowed" SG_ 1472 Status_NWG 0;
BA_ "GenSigTimeoutMsg__6HP_C6" SG_ 1472 Status_NWG 1472;
BA_ "GenSigTimeoutMsg_ESP8_C6" SG_ 1472 Status_NWG 1472;
BA_ "GenSigTimeoutMsg_Gateway_C6" SG_ 1472 Status_NWG 1472;
BA_ "GenSigAutoGenDsp" SG_ 1472 Textmeldungen_EPB 0;
BA_ "GenSigAutoGenSnd" SG_ 1472 Textmeldungen_EPB 0;
BA_ "GenSigSendType" SG_ 1472 Textmeldungen_EPB 7;
BA_ "NWM-WakeupAllowed" SG_ 1472 Textmeldungen_EPB 0;
BA_ "GenSigTimeoutMsg_Gateway_C6" SG_ 1472 Textmeldungen_EPB 1472;
BA_ "GenSigAutoGenDsp" SG_ 1472 Verschleissanzeige 0;
BA_ "GenSigAutoGenSnd" SG_ 1472 Verschleissanzeige 0;
BA_ "GenSigSendType" SG_ 1472 Verschleissanzeige 7;
BA_ "NWM-WakeupAllowed" SG_ 1472 Verschleissanzeige 0;
BA_ "GenSigTimeoutMsg_Gateway_C6" SG_ 1472 Verschleissanzeige 1472;
BA_ "GenSigAutoGenDsp" SG_ 1472 Verz_anf_EPB 0;
BA_ "GenSigAutoGenSnd" SG_ 1472 Verz_anf_EPB 0;
BA_ "GenSigSendType" SG_ 1472 Verz_anf_EPB 7;
BA_ "NWM-WakeupAllowed" SG_ 1472 Verz_anf_EPB 0;
BA_ "GenSigTimeoutMsg_ESP8_C6" SG_ 1472 Verz_anf_EPB 1472;
BA_ "GenSigTimeoutMsg_Gateway_C6" SG_ 1472 Verz_anf_EPB 1472;
BA_ "GenSigAutoGenDsp" SG_ 1472 Warnton_1 1;
BA_ "GenSigAutoGenSnd" SG_ 1472 Warnton_1 1;
BA_ "GenSigSendType" SG_ 1472 Warnton_1 7;
BA_ "NWM-WakeupAllowed" SG_ 1472 Warnton_1 0;
BA_ "GenSigTimeoutMsg_Gateway_C6" SG_ 1472 Warnton_1 1472;
BA_ "GenSigAutoGenDsp" SG_ 1472 Warnton_2 1;
BA_ "GenSigAutoGenSnd" SG_ 1472 Warnton_2 1;
BA_ "GenSigSendType" SG_ 1472 Warnton_2 7;
BA_ "NWM-WakeupAllowed" SG_ 1472 Warnton_2 0;
BA_ "GenSigTimeoutMsg_Gateway_C6" SG_ 1472 Warnton_2 1472;
BA_ "GenSigAutoGenDsp" SG_ 1472 Warnton_EPB 0;
BA_ "GenSigAutoGenSnd" SG_ 1472 Warnton_EPB 0;
BA_ "GenSigSendType" SG_ 1472 Warnton_EPB 7;
BA_ "NWM-WakeupAllowed" SG_ 1472 Warnton_EPB 0;
BA_ "GenSigTimeoutMsg_Gateway_C6" SG_ 1472 Warnton_EPB 1472;
BA_ "GenSigAutoGenDsp" SG_ 912 AAG_BLS_unplausibel 0;
BA_ "GenSigAutoGenSnd" SG_ 912 AAG_BLS_unplausibel 0;
BA_ "GenSigSendType" SG_ 912 AAG_BLS_unplausibel 7;
BA_ "NWM-WakeupAllowed" SG_ 912 AAG_BLS_unplausibel 0;
BA_ "GenSigAutoGenDsp" SG_ 912 AAG_Botschaftszaehler 0;
BA_ "GenSigAutoGenSnd" SG_ 912 AAG_Botschaftszaehler 0;
BA_ "GenSigSendType" SG_ 912 AAG_Botschaftszaehler 7;
BA_ "NWM-WakeupAllowed" SG_ 912 AAG_Botschaftszaehler 0;
BA_ "GenSigTimeoutMsg_DME_EDC16CP3000" SG_ 912 AAG_Botschaftszaehler 912;
BA_ "GenSigTimeoutMsg_DME_ME7_MED9_C6" SG_ 912 AAG_Botschaftszaehler 912;
BA_ "GenSigAutoGenDsp" SG_ 912 AAG_ECD_unplausibel 0;
BA_ "GenSigAutoGenSnd" SG_ 912 AAG_ECD_unplausibel 0;
BA_ "GenSigSendType" SG_ 912 AAG_ECD_unplausibel 7;
BA_ "NWM-WakeupAllowed" SG_ 912 AAG_ECD_unplausibel 0;
BA_ "GenSigTimeoutMsg_DME_EDC16CP3000" SG_ 912 AAG_ECD_unplausibel 912;
BA_ "GenSigTimeoutMsg_DME_ME7_MED9_C6" SG_ 912 AAG_ECD_unplausibel 912;
BA_ "GenSigAutoGenDsp" SG_ 912 Abblend_VL_def 0;
BA_ "GenSigAutoGenSnd" SG_ 912 Abblend_VL_def 0;
BA_ "GenSigSendType" SG_ 912 Abblend_VL_def 7;
BA_ "NWM-WakeupAllowed" SG_ 912 Abblend_VL_def 0;
BA_ "GenSigTimeoutMsg_LWR_AFS_C6" SG_ 912 Abblend_VL_def 912;
BA_ "GenSigAutoGenDsp" SG_ 912 Abblend_VR_def 0;
BA_ "GenSigAutoGenSnd" SG_ 912 Abblend_VR_def 0;
BA_ "GenSigSendType" SG_ 912 Abblend_VR_def 7;
BA_ "NWM-WakeupAllowed" SG_ 912 Abblend_VR_def 0;
BA_ "GenSigTimeoutMsg_LWR_AFS_C6" SG_ 912 Abblend_VR_def 912;
BA_ "GenSigAutoGenDsp" SG_ 912 Abblendlicht_aktiv 0;
BA_ "GenSigAutoGenSnd" SG_ 912 Abblendlicht_aktiv 0;
BA_ "GenSigSendType" SG_ 912 Abblendlicht_aktiv 7;
BA_ "NWM-WakeupAllowed" SG_ 912 Abblendlicht_aktiv 0;
BA_ "GenSigTimeoutMsg_LWR_AFS_C6" SG_ 912 Abblendlicht_aktiv 912;
BA_ "GenSigAutoGenDsp" SG_ 912 ACAN_Sleep_ACK 0;
BA_ "GenSigAutoGenSnd" SG_ 912 ACAN_Sleep_ACK 0;
BA_ "GenSigSendType" SG_ 912 ACAN_Sleep_ACK 7;
BA_ "NWM-WakeupAllowed" SG_ 912 ACAN_Sleep_ACK 0;
BA_ "GenSigTimeoutMsg__4CL_C6" SG_ 912 ACAN_Sleep_ACK 912;
BA_ "GenSigTimeoutMsg__6HP_C6" SG_ 912 ACAN_Sleep_ACK 912;
BA_ "GenSigTimeoutMsg_CVT_C6" SG_ 912 ACAN_Sleep_ACK 912;
BA_ "GenSigTimeoutMsg_DME_EDC16CP3000" SG_ 912 ACAN_Sleep_ACK 912;
BA_ "GenSigTimeoutMsg_DME_ME7_MED9_C6" SG_ 912 ACAN_Sleep_ACK 912;
BA_ "GenSigTimeoutMsg_DME_SIMOS6_C6" SG_ 912 ACAN_Sleep_ACK 912;
BA_ "GenSigTimeoutMsg_EPB_C6" SG_ 912 ACAN_Sleep_ACK 912;
BA_ "GenSigTimeoutMsg_ESP8_C6" SG_ 912 ACAN_Sleep_ACK 912;
BA_ "GenSigTimeoutMsg_LWS_C6" SG_ 912 ACAN_Sleep_ACK 912;
BA_ "GenSigAutoGenDsp" SG_ 912 Anhaenger_alt 0;
BA_ "GenSigAutoGenSnd" SG_ 912 Anhaenger_alt 0;
BA_ "GenSigSendType" SG_ 912 Anhaenger_alt 7;
BA_ "NWM-WakeupAllowed" SG_ 912 Anhaenger_alt 0;
BA_ "GenSigTimeoutMsg__4CL_C6" SG_ 912 Anhaenger_alt 912;
BA_ "GenSigTimeoutMsg_DME_ME7_MED9_C6" SG_ 912 Anhaenger_alt 912;
BA_ "GenSigAutoGenDsp" SG_ 912 Anhaenger_erkannt 0;
BA_ "GenSigAutoGenSnd" SG_ 912 Anhaenger_erkannt 0;
BA_ "GenSigSendType" SG_ 912 Anhaenger_erkannt 7;
BA_ "NWM-WakeupAllowed" SG_ 912 Anhaenger_erkannt 0;
BA_ "GenSigTimeoutMsg__4CL_C6" SG_ 912 Anhaenger_erkannt 912;
BA_ "GenSigTimeoutMsg_DME_EDC16CP3000" SG_ 912 Anhaenger_erkannt 912;
BA_ "GenSigTimeoutMsg_DME_ME7_MED9_C6" SG_ 912 Anhaenger_erkannt 912;
BA_ "GenSigAutoGenDsp" SG_ 912 Blinken_Autobahn 0;
BA_ "GenSigAutoGenSnd" SG_ 912 Blinken_Autobahn 0;
BA_ "GenSigSendType" SG_ 912 Blinken_Autobahn 7;
BA_ "NWM-WakeupAllowed" SG_ 912 Blinken_Autobahn 0;
BA_ "GenSigTimeoutMsg_LWR_AFS_C6" SG_ 912 Blinken_Autobahn 912;
BA_ "GenSigAutoGenDsp" SG_ 912 Blinken_links 0;
BA_ "GenSigAutoGenSnd" SG_ 912 Blinken_links 0;
BA_ "GenSigSendType" SG_ 912 Blinken_links 7;
BA_ "NWM-WakeupAllowed" SG_ 912 Blinken_links 0;
BA_ "GenSigTimeoutMsg_LWR_AFS_C6" SG_ 912 Blinken_links 912;
BA_ "GenSigAutoGenDsp" SG_ 912 Blinken_rechts 0;
BA_ "GenSigAutoGenSnd" SG_ 912 Blinken_rechts 0;
BA_ "GenSigSendType" SG_ 912 Blinken_rechts 7;
BA_ "NWM-WakeupAllowed" SG_ 912 Blinken_rechts 0;
BA_ "GenSigTimeoutMsg_LWR_AFS_C6" SG_ 912 Blinken_rechts 912;
BA_ "GenSigAutoGenDsp" SG_ 912 Bremsl_3_def 0;
BA_ "GenSigAutoGenSnd" SG_ 912 Bremsl_3_def 0;
BA_ "GenSigSendType" SG_ 912 Bremsl_3_def 7;
BA_ "NWM-WakeupAllowed" SG_ 912 Bremsl_3_def 0;
BA_ "GenSigTimeoutMsg_DME_EDC16CP3000" SG_ 912 Bremsl_3_def 912;
BA_ "GenSigTimeoutMsg_DME_ME7_MED9_C6" SG_ 912 Bremsl_3_def 912;
BA_ "GenSigAutoGenDsp" SG_ 912 Bremsl_HL_def 0;
BA_ "GenSigAutoGenSnd" SG_ 912 Bremsl_HL_def 0;
BA_ "GenSigSendType" SG_ 912 Bremsl_HL_def 7;
BA_ "NWM-WakeupAllowed" SG_ 912 Bremsl_HL_def 0;
BA_ "GenSigTimeoutMsg_DME_EDC16CP3000" SG_ 912 Bremsl_HL_def 912;
BA_ "GenSigTimeoutMsg_DME_ME7_MED9_C6" SG_ 912 Bremsl_HL_def 912;
BA_ "GenSigAutoGenDsp" SG_ 912 Bremsl_HR_def 0;
BA_ "GenSigAutoGenSnd" SG_ 912 Bremsl_HR_def 0;
BA_ "GenSigSendType" SG_ 912 Bremsl_HR_def 7;
BA_ "NWM-WakeupAllowed" SG_ 912 Bremsl_HR_def 0;
BA_ "GenSigTimeoutMsg_DME_EDC16CP3000" SG_ 912 Bremsl_HR_def 912;
BA_ "GenSigTimeoutMsg_DME_ME7_MED9_C6" SG_ 912 Bremsl_HR_def 912;
BA_ "GenSigAutoGenDsp" SG_ 912 Bremslicht_AH_def 0;
BA_ "GenSigAutoGenSnd" SG_ 912 Bremslicht_AH_def 0;
BA_ "GenSigSendType" SG_ 912 Bremslicht_AH_def 7;
BA_ "NWM-WakeupAllowed" SG_ 912 Bremslicht_AH_def 0;
BA_ "GenSigTimeoutMsg_DME_EDC16CP3000" SG_ 912 Bremslicht_AH_def 912;
BA_ "GenSigTimeoutMsg_DME_ME7_MED9_C6" SG_ 912 Bremslicht_AH_def 912;
BA_ "GenSigAutoGenDsp" SG_ 912 Fernlicht_aktiv 0;
BA_ "GenSigAutoGenSnd" SG_ 912 Fernlicht_aktiv 0;
BA_ "GenSigSendType" SG_ 912 Fernlicht_aktiv 7;
BA_ "NWM-WakeupAllowed" SG_ 912 Fernlicht_aktiv 0;
BA_ "GenSigTimeoutMsg_LWR_AFS_C6" SG_ 912 Fernlicht_aktiv 912;
BA_ "GenSigAutoGenDsp" SG_ 912 ILM_BLS_unplausibel 0;
BA_ "GenSigAutoGenSnd" SG_ 912 ILM_BLS_unplausibel 0;
BA_ "GenSigSendType" SG_ 912 ILM_BLS_unplausibel 7;
BA_ "NWM-WakeupAllowed" SG_ 912 ILM_BLS_unplausibel 0;
BA_ "GenSigAutoGenDsp" SG_ 912 ILM_ECD_unplausibel 0;
BA_ "GenSigAutoGenSnd" SG_ 912 ILM_ECD_unplausibel 0;
BA_ "GenSigSendType" SG_ 912 ILM_ECD_unplausibel 7;
BA_ "NWM-WakeupAllowed" SG_ 912 ILM_ECD_unplausibel 0;
BA_ "GenSigTimeoutMsg_DME_EDC16CP3000" SG_ 912 ILM_ECD_unplausibel 912;
BA_ "GenSigTimeoutMsg_DME_ME7_MED9_C6" SG_ 912 ILM_ECD_unplausibel 912;
BA_ "GenSigAutoGenDsp" SG_ 912 ILM_Fahrer1_alt 0;
BA_ "GenSigAutoGenSnd" SG_ 912 ILM_Fahrer1_alt 0;
BA_ "GenSigSendType" SG_ 912 ILM_Fahrer1_alt 7;
BA_ "NWM-WakeupAllowed" SG_ 912 ILM_Fahrer1_alt 0;
BA_ "GenSigTimeoutMsg_EPB_C6" SG_ 912 ILM_Fahrer1_alt 912;
BA_ "GenSigAutoGenDsp" SG_ 912 ILM_H_Botschaftszaehler 0;
BA_ "GenSigAutoGenSnd" SG_ 912 ILM_H_Botschaftszaehler 0;
BA_ "GenSigSendType" SG_ 912 ILM_H_Botschaftszaehler 7;
BA_ "NWM-WakeupAllowed" SG_ 912 ILM_H_Botschaftszaehler 0;
BA_ "GenSigTimeoutMsg_DME_ME7_MED9_C6" SG_ 912 ILM_H_Botschaftszaehler 912;
BA_ "GenSigAutoGenDsp" SG_ 912 KY2_ELV_verr 0;
BA_ "GenSigAutoGenSnd" SG_ 912 KY2_ELV_verr 0;
BA_ "GenSigSendType" SG_ 912 KY2_ELV_verr 7;
BA_ "NWM-WakeupAllowed" SG_ 912 KY2_ELV_verr 0;
BA_ "GenSigTimeoutMsg_EPB_C6" SG_ 912 KY2_ELV_verr 912;
BA_ "GenSigAutoGenDsp" SG_ 912 Licht_hinten_alt 0;
BA_ "GenSigAutoGenSnd" SG_ 912 Licht_hinten_alt 0;
BA_ "GenSigSendType" SG_ 912 Licht_hinten_alt 7;
BA_ "NWM-WakeupAllowed" SG_ 912 Licht_hinten_alt 0;
BA_ "GenSigTimeoutMsg_DME_ME7_MED9_C6" SG_ 912 Licht_hinten_alt 912;
BA_ "GenSigTimeoutMsg_LWR_AFS_C6" SG_ 912 Licht_hinten_alt 912;
BA_ "GenSigAutoGenDsp" SG_ 912 Licht_vorne_alt 0;
BA_ "GenSigAutoGenSnd" SG_ 912 Licht_vorne_alt 0;
BA_ "GenSigSendType" SG_ 912 Licht_vorne_alt 7;
BA_ "NWM-WakeupAllowed" SG_ 912 Licht_vorne_alt 0;
BA_ "GenSigTimeoutMsg_LWR_AFS_C6" SG_ 912 Licht_vorne_alt 912;
BA_ "GenSigAutoGenDsp" SG_ 912 mKessy2_alt 0;
BA_ "GenSigAutoGenSnd" SG_ 912 mKessy2_alt 0;
BA_ "GenSigSendType" SG_ 912 mKessy2_alt 7;
BA_ "NWM-WakeupAllowed" SG_ 912 mKessy2_alt 0;
BA_ "GenSigTimeoutMsg_EPB_C6" SG_ 912 mKessy2_alt 912;
BA_ "GenSigAutoGenDsp" SG_ 912 mStHeizung1_alt 0;
BA_ "GenSigAutoGenSnd" SG_ 912 mStHeizung1_alt 0;
BA_ "GenSigSendType" SG_ 912 mStHeizung1_alt 7;
BA_ "NWM-WakeupAllowed" SG_ 912 mStHeizung1_alt 0;
BA_ "GenSigAutoGenDsp" SG_ 912 Nebellicht_aktiv 0;
BA_ "GenSigAutoGenSnd" SG_ 912 Nebellicht_aktiv 0;
BA_ "GenSigSendType" SG_ 912 Nebellicht_aktiv 7;
BA_ "NWM-WakeupAllowed" SG_ 912 Nebellicht_aktiv 0;
BA_ "GenSigAutoGenDsp" SG_ 912 RDK_alt 0;
BA_ "GenSigAutoGenSnd" SG_ 912 RDK_alt 0;
BA_ "GenSigSendType" SG_ 912 RDK_alt 7;
BA_ "NWM-WakeupAllowed" SG_ 912 RDK_alt 0;
BA_ "GenSigAutoGenDsp" SG_ 912 Rueckfahrlicht_akt 0;
BA_ "GenSigAutoGenSnd" SG_ 912 Rueckfahrlicht_akt 0;
BA_ "GenSigSendType" SG_ 912 Rueckfahrlicht_akt 7;
BA_ "NWM-WakeupAllowed" SG_ 912 Rueckfahrlicht_akt 0;
BA_ "GenSigTimeoutMsg_ESP8_C6" SG_ 912 Rueckfahrlicht_akt 912;
BA_ "GenSigTimeoutMsg_LWR_AFS_C6" SG_ 912 Rueckfahrlicht_akt 912;
BA_ "GenSigAutoGenDsp" SG_ 912 Rueckfahrlichtschalter_ein 0;
BA_ "GenSigAutoGenSnd" SG_ 912 Rueckfahrlichtschalter_ein 0;
BA_ "GenSigSendType" SG_ 912 Rueckfahrlichtschalter_ein 7;
BA_ "NWM-WakeupAllowed" SG_ 912 Rueckfahrlichtschalter_ein 0;
BA_ "GenSigTimeoutMsg_EPB_C6" SG_ 912 Rueckfahrlichtschalter_ein 912;
BA_ "GenSigTimeoutMsg_ESP8_C6" SG_ 912 Rueckfahrlichtschalter_ein 912;
BA_ "GenSigAutoGenDsp" SG_ 912 SH_aktiv_Flag 0;
BA_ "GenSigAutoGenSnd" SG_ 912 SH_aktiv_Flag 0;
BA_ "GenSigSendType" SG_ 912 SH_aktiv_Flag 7;
BA_ "NWM-WakeupAllowed" SG_ 912 SH_aktiv_Flag 0;
BA_ "GenSigTimeoutMsg_DME_ME7_MED9_C6" SG_ 912 SH_aktiv_Flag 912;
BA_ "GenSigAutoGenDsp" SG_ 912 SH_MVW 0;
BA_ "GenSigAutoGenSnd" SG_ 912 SH_MVW 0;
BA_ "GenSigSendType" SG_ 912 SH_MVW 7;
BA_ "NWM-WakeupAllowed" SG_ 912 SH_MVW 0;
BA_ "GenSigTimeoutMsg_DME_ME7_MED9_C6" SG_ 912 SH_MVW 912;
BA_ "GenSigAutoGenDsp" SG_ 912 Warnblink_aktiv 0;
BA_ "GenSigAutoGenSnd" SG_ 912 Warnblink_aktiv 0;
BA_ "GenSigSendType" SG_ 912 Warnblink_aktiv 7;
BA_ "NWM-WakeupAllowed" SG_ 912 Warnblink_aktiv 0;
BA_ "GenSigAutoGenDsp" SG_ 912 Wischer_vorne_laeuft 0;
BA_ "GenSigAutoGenSnd" SG_ 912 Wischer_vorne_laeuft 0;
BA_ "GenSigSendType" SG_ 912 Wischer_vorne_laeuft 7;
BA_ "NWM-WakeupAllowed" SG_ 912 Wischer_vorne_laeuft 0;
BA_ "GenSigTimeoutMsg_ESP8_C6" SG_ 912 Wischer_vorne_laeuft 912;
BA_ "GenSigAutoGenDsp" SG_ 684 BZ_Geschwindigkeit1 0;
BA_ "GenSigAutoGenSnd" SG_ 684 BZ_Geschwindigkeit1 0;
BA_ "GenSigSendType" SG_ 684 BZ_Geschwindigkeit1 7;
BA_ "NWM-WakeupAllowed" SG_ 684 BZ_Geschwindigkeit1 0;
BA_ "GenSigTimeoutMsg__4CL_C6" SG_ 684 BZ_Geschwindigkeit1 684;
BA_ "GenSigAutoGenDsp" SG_ 684 CHK_Geschwindigkeit1 0;
BA_ "GenSigAutoGenSnd" SG_ 684 CHK_Geschwindigkeit1 0;
BA_ "GenSigSendType" SG_ 684 CHK_Geschwindigkeit1 7;
BA_ "NWM-WakeupAllowed" SG_ 684 CHK_Geschwindigkeit1 0;
BA_ "GenSigTimeoutMsg__4CL_C6" SG_ 684 CHK_Geschwindigkeit1 684;
BA_ "GenSigAutoGenDsp" SG_ 684 Fahrtrichtung 0;
BA_ "GenSigAutoGenSnd" SG_ 684 Fahrtrichtung 0;
BA_ "GenSigSendType" SG_ 684 Fahrtrichtung 7;
BA_ "NWM-WakeupAllowed" SG_ 684 Fahrtrichtung 0;
BA_ "GenSigAutoGenDsp" SG_ 684 Geschwindigkeit_16Bit 0;
BA_ "GenSigAutoGenSnd" SG_ 684 Geschwindigkeit_16Bit 0;
BA_ "GenSigSendType" SG_ 684 Geschwindigkeit_16Bit 7;
BA_ "GenSigStartValue" SG_ 684 Geschwindigkeit_16Bit 65416;
BA_ "NWM-WakeupAllowed" SG_ 684 Geschwindigkeit_16Bit 0;
BA_ "GenSigTimeoutMsg__4CL_C6" SG_ 684 Geschwindigkeit_16Bit 684;
BA_ "GenSigAutoGenDsp" SG_ 684 QBit_Geschwindigkeit 0;
BA_ "GenSigAutoGenSnd" SG_ 684 QBit_Geschwindigkeit 0;
BA_ "GenSigSendType" SG_ 684 QBit_Geschwindigkeit 7;
BA_ "GenSigStartValue" SG_ 684 QBit_Geschwindigkeit 1;
BA_ "NWM-WakeupAllowed" SG_ 684 QBit_Geschwindigkeit 0;
BA_ "GenSigTimeoutMsg__4CL_C6" SG_ 684 QBit_Geschwindigkeit 684;
BA_ "GenSigAutoGenDsp" SG_ 684 QBit_Referenzgeschwindigkeit 0;
BA_ "GenSigAutoGenSnd" SG_ 684 QBit_Referenzgeschwindigkeit 0;
BA_ "GenSigSendType" SG_ 684 QBit_Referenzgeschwindigkeit 7;
BA_ "GenSigStartValue" SG_ 684 QBit_Referenzgeschwindigkeit 1;
BA_ "NWM-WakeupAllowed" SG_ 684 QBit_Referenzgeschwindigkeit 0;
BA_ "GenSigAutoGenDsp" SG_ 684 Referenzgeschwindigkeit 0;
BA_ "GenSigAutoGenSnd" SG_ 684 Referenzgeschwindigkeit 0;
BA_ "GenSigSendType" SG_ 684 Referenzgeschwindigkeit 7;
BA_ "GenSigStartValue" SG_ 684 Referenzgeschwindigkeit 65416;
BA_ "NWM-WakeupAllowed" SG_ 684 Referenzgeschwindigkeit 0;
VAL_ 866 Freigabe_Verzoeg_Anf 0 "Verzoeg_Anf_nicht_freig" 1 "Verzoeg_Anf_freig" ;
VAL_ 866 Status_ACC 0 "ACC_OFF" 2 "ACC_STANDBY" 1 "ACC_INIT" 7 "ACC_FEHLER_IRREVERS" 3 "ACC_AKTIV" 4 "ACC_OVERRIDE" 6 "ACC_FEHLER_REVERS" ;
VAL_ 866 Sender_Info 1 "Sender_ACC" 0 "Sender_Motor" ;
VAL_ 866 Verhinderung_SA 1 "SA_nicht_zulaessig" 0 "SA_zulaessig" ;
VAL_ 866 Freigabe_Momenten_Anf 1 "Mmot_Anf_freig" 0 "Mmot_Anf_nicht_freig" ;
VAL_ 866 Sollbeschl_Getr 166 "Init" ;
VAL_ 866 FSPE_ACC 1 "KD_Fehler_eingetr" 0 "kein_KD_Fehler_eingetr" ;
VAL_ 866 Vorbefuellung_Bremsanlage 1 "Vorbefuellung" 0 "keine_Vorbefuellung" ;
VAL_ 866 Verzoeg_Anf_ACC 166 "Init" ;
VAL_ 866 ESP_Beeinflussung_ACC 1 "ESP_Beeinfl" 0 "keine_ESP_Beeinfl" ;
VAL_ 866 AWV1_Parameter_HBA 0 "Defaultparametersatz" 1 "leicht_erhoehte_Empfindlichkeit" 3 "hoechste_Empfindlichkeit" 2 "erhoehte_Empfindlichkeit" ;
VAL_ 866 AWV1_Freigabe 0 "AWV1_nicht_freigegeben" 1 "AWV1_freigegeben" ;
VAL_ 866 AWV1_Prefill 0 "keine_Prefill_Anforderung" 1 "AWV1_freigegeben" ;
VAL_ 866 Anhalten 1 "Anhalteanforderung_aktiv" 0 "keine_Anhalteanforderung" ;
VAL_ 866 AWV2_Freigabe 1 "Freigabe" 0 "keine_Freigabe" ;
VAL_ 80 Gurtschlossabfrage_Fahrer 1 "Fehler" 0 "nicht_verfuegbar" 2 "Gurt_nicht_gesteckt" 3 "Gurt_gesteckt" ;
VAL_ 80 Crash_Intensitaet 7 "RdW_Schwelle_RB" 4 "RdW_Schwelle" 2 "US_Schwelle" 1 "Gurtstrafferschwelle" ;
VAL_ 80 Airbag_deaktiviert 0 "Airbag_aktiv" 1 "Airbag_deaktiviert" ;
VAL_ 80 Gurtschlossabfrage_Beifahrer 1 "Fehler" 3 "Gurt_gesteckt" 0 "nicht_verfuegbar" 2 "Gurt_nicht_gesteckt" ;
VAL_ 80 Airbag_Systemfehler 0 "kein_Fehler" 1 "Systemfehler" ;
VAL_ 80 Airbag_im_Stellgliedtest 0 "Airbag_nicht_im_Stellgliedtest" 1 "Airbag_im_Stellgliedtest" ;
VAL_ 80 Seiten_Crash_Beifahrer 0 "kein_Seiten_Crash_Beifahrer" 1 "Seiten_Crash_Beifahrer" ;
VAL_ 80 Front_Crash 1 "Front_Crash" 0 "kein_Front_Crash" ;
VAL_ 80 Rollover 0 "kein_Rollover" 1 "Rollover" ;
VAL_ 80 Beifahrerairbag_deaktiviert 1 "Beifahrerairbag_deaktiviert" 0 "Beifahrerairbag_aktiv" ;
VAL_ 80 FSPE_Airbag 1 "KD_Fehler_eingetr" 0 "kein_KD_Fehler_eingetr" ;
VAL_ 80 Heck_Crash 1 "Heck_Crash" 0 "kein_Heck_Crash" ;
VAL_ 80 Seiten_Crash_Fahrer 0 "kein_Seiten_Crash" 1 "Seiten_Crash" ;
VAL_ 80 Airbag_in_Diagnose 1 "Airbag_in_Diagnose" 0 "Airbag_nicht_in_Diagnose" ;
VAL_ 80 Airbag_Lampe 1 "Lampe_an" 0 "Lampe_aus" ;
VAL_ 80 Gurtwarnung_Beifahrer 1 "Warnung_ausloesen" 0 "keine_Warnung" ;
VAL_ 1360 Belegerkenn_Beifahrersitz 1 "Fehler" 0 "Nicht_verfuegbar" 3 "Belegt" 2 "Nicht_belegt" ;
VAL_ 1360 OOP_Fahrer 4 "Fahrer_in_Position" 0 "Nicht_verfuegbar" 5 "Fahrer_oop_70%" 1 "Fehler" 6 "Fahrer_oop_30%" ;
VAL_ 1360 Belegerkenn_hinten_Fahrer 0 "Nicht_verfuegbar" 3 "Belegt" 1 "Fehler" 2 "Nicht_belegt" ;
VAL_ 1360 Belegerkenn_hinten_Beifahrer 0 "Nicht_verfuegbar" 2 "Nicht_belegt" 3 "Belegt" 1 "Fehler" ;
VAL_ 1360 Belegerkenn_hinten_Mitte 0 "Nicht_verfuegbar" 1 "Fehler" 2 "Nicht_belegt" 3 "Belegt" ;
VAL_ 1360 OOP_Beifahrer 5 "Fahrer_oop_70%" 0 "Nicht_verfuegbar" 6 "Fahrer_oop_30%" 4 "Fahrer_in_Position" 1 "Fehler" ;
VAL_ 1360 Erhoehung_Aufmerk_BFS 2 "BF_Airbag_aktiviert" 1 "BF_Airbag_deaktiviert" 3 "nicht_benutzt" 0 "keine_Beschreibung" ;
VAL_ 882 Red_Innenraumgeblaese 3 "" 1 "Reduzierung Stufe 1" 2 "Reduzierung Stufe 2" 0 "nix" ;
VAL_ 416 ASR_Steuergeraet 1 "ASR_ESP_MABS" 0 "ABS_EDS" ;
VAL_ 416 EBV_Eingriff 0 "kein_Eingriff" 1 "EBV_Eingriff" ;
VAL_ 416 ASR_Anforderung 1 "ASR_Anforderung" 0 "keine_Anforderung" ;
VAL_ 416 Lampe_ASR_ESP 0 "Lampe_aus" 1 "Lampe_ein" ;
VAL_ 416 ABS_Bremsung 1 "ABS_Bremsung" 0 "kein_Eingriff" ;
VAL_ 416 BKL 1 "Lampe_ein" 0 "Lampe_aus" ;
VAL_ 416 Geschwindigkeitersatzwert 0 "iO" 1 "Ersatzwert" ;
VAL_ 416 Schlechtwegausblendung 0 "kein_Ausblendung" 1 "Ausblendung" ;
VAL_ 416 MSR_Anforderung 0 "keine_Anforderung" 1 "MSR_Anforderung" ;
VAL_ 416 FStatus_Schlechtwegausblendung 1 "ungueltig" 0 "gueltig" ;
VAL_ 416 ESP_Eingriff 1 "ESP_Eingriff" 0 "kein_ESP_Eingriff" ;
VAL_ 416 ESP_Systemstatus 0 "OK" 1 "Fehler" ;
VAL_ 416 EDS_Eingriff 1 "EDS_Eingriff" 0 "kein_Eingriff" ;
VAL_ 416 Bremslichtschalter_ESP 0 "kein_Bremsen" 1 "Bremse_betaetigt" ;
VAL_ 416 Lampe_ABS 0 "Lampe_aus" 1 "Lampe_ein" ;
VAL_ 416 ESP_passiv_getastet 1 "Passiv_getastet" 0 "ESP_aktiviert" ;
VAL_ 416 ASR_Schaltbeeinflussung 0 "keine_Anforderung" 3 "Schaltverbot" 2 "Rueckschaltung" 1 "ASR_Schaltkennfeld" ;
VAL_ 416 Bremstestschalter_ESP 0 "kein_Bremsen" 1 "Bremse_betaetigt" ;
VAL_ 416 Geschwindigkeit_15Bit 32742 "V_Fehler" 32725 "V_Uspg" 32708 "V_INIT" ;
VAL_ 416 Fahrer_bremst 0 "Fahrer_bremst_nicht" 1 "Fahrer_bremst" ;
VAL_ 416 Status_aktives_Bremssystem 1 "System_aktiv" 0 "System_inaktiv" ;
VAL_ 1440 FSPE_Bremse 0 "kein_KD_Fehler_eingetr" 1 "KD_Fehler_eingetr" ;
VAL_ 1440 Mux_Code_Bremse2 0 "ay" 1 "Zaehnezahl" ;
VAL_ 1440 QBit_Querbeschleunigung 0 "gueltiger_Wert" 1 "Ersatz_Init_Fehlerwert" ;
VAL_ 1440 Wegimpulszaehlerstatus 0 "Reset_kein_Ueberlauf" 1 "mind_1x_Ueberlauf" ;
VAL_ 1440 SIB_ESP 0 "CAN_wird_benoetigt" 1 "Sleep_bereit" ;
VAL_ 1440 Mittlere_Raddrehzahl 32725 "V_Uspg" 32742 "V_Fehler" ;
VAL_ 1440 FStatus_Wegimpulse 1 "Fehler" 0 "Wegimpulse_iO" ;
VAL_ 1440 Querbeschleunigung 255 "Fehler" ;
VAL_ 1440 Lampe_ASR_ESP 0 "Lampe_aus" 1 "Lampe_ein" ;
VAL_ 1440 Lampe_ABS 0 "Lampe_aus" 1 "Lampe_ein" ;
VAL_ 1440 BKL 1 "Lampe_ein" 0 "Lampe_aus" ;
VAL_ 1440 Warnlampe_RKA 1 "Lampe_ein" 0 "Lampe_aus" ;
VAL_ 1440 Textbits_Bremse 1 "ESP_Stoerung" 7 "ASR_deaktiviert" 4 "Werkstatt_Bremse" 6 "ESP_deaktiviert" 10 "keine_BKV" 3 "ESP_ABS_Stoerung" 0 "kein_Text" 8 "ESP_aktiviert" 5 "ASR_Stoerung" 9 "Stoerung_Hillholder" 2 "ABS_Stoerung" ;
VAL_ 1440 Akustische_Warnung 1 "ein_Mal_Gong" 2 "drei_Mal_Gong" 0 "kein_Gong_kein_Summer" 3 "Summer_2kHz" ;
VAL_ 1440 Bremskontroll_Blinkmode 1 "BKL_blinkt_mit_1Hz" 0 "BKL_blinkt_nicht" ;
VAL_ 1184 Fahrtrichtung_HR 1 "Rueckwaerts" 0 "Vorwaerts" ;
VAL_ 1184 Radgeschw_HL 32708 "V_INIT" 32725 "V_Uspg" 32742 "V_Fehler" ;
VAL_ 1184 Radgeschw_VL 32725 "V_Uspg" 32742 "V_Fehler" 32708 "V_INIT" ;
VAL_ 1184 Radgeschw_VR 32725 "V_Uspg" 32708 "V_INIT" 32742 "V_Fehler" ;
VAL_ 1184 Fahrtrichtung_HL 0 "Vorwaerts" 1 "Rueckwaerts" ;
VAL_ 1184 Fahrtrichtung_VL 0 "Vorwaerts" 1 "Rueckwaerts" ;
VAL_ 1184 Radgeschw_HR 32725 "V_Uspg" 32708 "V_INIT" 32742 "V_Fehler" ;
VAL_ 1184 Fahrtrichtung_VR 0 "Vorwaerts" 1 "Rueckwaerts" ;
VAL_ 1192 Gierrate_ungueltig 1 "ungueltig" 0 "gueltig" ;
VAL_ 1192 Status_Bremsdruck_ESP_System 0 "kein_aktiver_Druckaufbau" 1 "aktiver_Druckaufbau" ;
VAL_ 1192 Bremsdruck 4095 "" ;
VAL_ 1192 Bremslicht_ECD 1 "Lampe_an" 0 "Lampe_aus" ;
VAL_ 1192 Signum_Giergeschwindigkeit 0 "positiv" 1 "negativ" ;
VAL_ 1192 Giergeschwindigkeit 16383 "Fehler" ;
VAL_ 1192 Reifentoleranzabgleich_VR 255 "" 254 "nicht_konvergent" ;
VAL_ 1192 Stillstandsflag 0 "kein_Stillstand_erkannt" 1 "Stillstand_erkannt" ;
VAL_ 1192 Bremsdruck_ungueltig 1 "ungueltig" 0 "gueltig" ;
VAL_ 1192 Signum_Bremsdruck 0 "positiv" 1 "negativ" ;
VAL_ 1192 Geschwindigkeitsueberwachung 0 "Funktion_nicht_verfuegbar" 1 "Funktion_verfuegbar" ;
VAL_ 1192 TSP_aktiv 1 "Bremslicht_an" 0 "keine_Bremslichtanforderung" ;
VAL_ 1192 Notfallblinken 0 "keine_Notbremsung_erkannt" 1 "Notbremsung_erkannt" ;
VAL_ 1192 Rueckfallebene_ECD 0 "iO" 1 "Fehler_Drucksensor" ;
VAL_ 1192 FStatus_Anfahrhilfe 0 "kein_Fehler" 1 "Fehler" ;
VAL_ 1192 Anfahrhilfe_aktiv 0 "nicht_aktiv" 1 "Anfahrhilfe_aktiv" ;
VAL_ 428 Status_BLS 1 "Fehler" 0 "kein_Fehler" ;
VAL_ 428 Verzoegerung_EPB_aktiviert 0 "nicht_aktiviert" 1 "aktiviert" ;
VAL_ 428 EPB_Botschaft_plausibel 1 "plausibel" 0 "nicht_plausibel" ;
VAL_ 428 Status_Bremse_ACC_Anf 1 "aktiv" 0 "passiv" ;
VAL_ 428 Quattroantrieb 0 "Front" 1 "Quattro" ;
VAL_ 428 EPB_Verzoegerung_verfuegbar 0 "nicht_verfuegbar" 1 "System_verfuegbar" ;
VAL_ 428 Status_Bremsdruck 1 "mit_Bremsdruck" 0 "Bremse_drucklos" ;
VAL_ 428 Status_Bremsentemperatur 1 "ueberhitzt" 0 "nicht_ueberhitzt" ;
VAL_ 428 Konsistenz_ACC_Botschaft 1 "ACC_Botschaft_inkonsistent" 0 "ACC_Botschaft_konsistent" ;
VAL_ 428 Aktives_Bremssystem 1 "ja" 0 "nein" ;
VAL_ 428 Status_aktives_Bremssystem 1 "System_aktiv" 0 "System_inaktiv" ;
VAL_ 428 Status_HW_BLS_Ausgang 0 "Ausgang_iO" 1 "Ausgang_defekt" ;
VAL_ 428 Fahrer_bremst 0 "Fahrer_bremst_nicht" 1 "Fahrer_bremst" ;
VAL_ 428 QBit_Laengsbeschleunigung 1 "Ersatz_Init_Fehlerwert" 0 "gueltiger_Wert" ;
VAL_ 1524 Antriebsvariante 1 "front" 2 "quattro" 0 "keine_Variante_hinterlegt" ;
VAL_ 2000 Kilometerstand 1048575 "Fehler" ;
VAL_ 1472 Fehlerlampe_BKL 1 "BKL_an" 0 "BKL_aus" ;
VAL_ 1472 KL15_Status_Info 0 "KL15_aus" 1 "KL15_ein" ;
VAL_ 1472 Schalterstatus_EPB 1 "Schalter_ausser_Funktion" 0 "volle_Funktion" ;
VAL_ 1472 Status_EPB 0 "Bremse_geoeffnet" 1 "Bremse_geschlossen" ;
VAL_ 1472 Warnton_EPB 0 "Warnton_aus" 1 "Warnton_an" ;
VAL_ 1472 Status_NWG 1 "keine_Funktion" 0 "volle_Funktion" ;
VAL_ 1472 Fehlerlampe_Gelb_EPB 1 "Lampe_ein" 0 "Lampe_aus" ;
VAL_ 1472 Verschleissanzeige 0 "Belaege_iO" 2 "Belag_verschlissen" ;
VAL_ 1472 Erreichte_Spannkraft 31 "Fehler" ;
VAL_ 1472 Funktionslampe_EPB 0 "Lampe_aus" 1 "Lampe_an" ;
VAL_ 1472 Schalterinfo_EPB 3 "Schalterfehler" 2 "Fahreranforderung_Schliessen" 0 "keine_Schalterinfo" 1 "Fahreranforderung_Oeffnen" ;
VAL_ 1472 FSPE_EPB 0 "kein_KD_Fehler_eingetr" 1 "KD_Fehler_eingetr" ;
VAL_ 1472 FStatus_EPB 2 "rechte_Seite_fehlerhaft" 1 "linke_Seite_fehlerhaft" 3 "beide_Seiten_fehlerhaft" 0 "volle_Funktion" ;
VAL_ 1472 Freig_Verz_anf_EPB 0 "keine_Freigabe" 1 "Freigabe" ;
VAL_ 1472 SIB_EPB 1 "Sleep_bereit" 0 "CAN_wird_benoetigt" ;
VAL_ 1472 Textmeldungen_EPB 2 "Parkbremse_von_Hand_oeffnen" 3 "EPB_in_Diagnose" 0 "keine_Anzeige" 1 "Neigungswinkel_zu_gross" 5 "Parkbremse_Motorlauf_schliessen" 4 "Bremspedal_betaetigen" ;
VAL_ 1472 Warnton_1 1 "Warnton1_ein" 0 "Warnton1_aus" ;
VAL_ 1472 Warnton_2 1 "Warnton2_ein" 0 "Warnton2_aus" ;
VAL_ 1472 Auto_Oeffnen_Schliessen_erlaubt 1 "erlaubt" 0 "nicht_erlaubt" ;
VAL_ 1472 QBit_Neigungswinkel 1 "Ersatz_Init_Fehlerwert" 0 "gueltiger_Wert" ;
VAL_ 1472 Kupplungsmodulationsbereich 2 "Sensorsignal_ungenau" 3 "Sensor_defekt" 0 "Ausserhalb_Modulber" 1 "im_Modulber" ;
VAL_ 1472 Anforderung_Shift_Lock_Lampe 0 "Shift_Lock_Lampe_aus" 1 "Shift_Lock_Lampe_ein" ;
VAL_ 1472 Bremslicht_dyn_Abbremsung 1 "Bremslicht_an" 0 "Bremslicht_aus" ;
VAL_ 1472 Funktionslampe_Auto_P 0 "Lampe_aus" 1 "Lampe_an" ;
VAL_ 912 ACAN_Sleep_ACK 1 "ACAN_Goto_Sleep" 0 "ACAN_Wach" ;
VAL_ 912 AAG_BLS_unplausibel 0 "BLS Signal unplausibel" 1 "" ;
VAL_ 912 AAG_ECD_unplausibel 0 "" 1 "1 = ECD Signal unplausibel" ;
VAL_ 684 QBit_Referenzgeschwindigkeit 0 "gueltiger_Wert" 1 "Ersatz_Init_Fehlerwert" ;
VAL_ 684 QBit_Geschwindigkeit 0 "gueltiger_Wert" 1 "Ersatz_Init_Fehlerwert" ;
VAL_ 684 Fahrtrichtung 0 "Vorwaerts" 1 "Rueckwaerts" ;
